VERSION ""

NS_ :

BS_:

BU_: WPC2 RLPSU DPSU APSU PSB SHVU_RR vHS_B2 FCS EMCU SLB ARS RCM CGW_CCU vDummy_HS_B ATS RLHV SGU PFSU ALBCU DSAU SWRC SHVU_FR RCS RRPSU BLTN_CAM SCM DLBCU OHCL RWPC RRHV WPC HOD ASAU

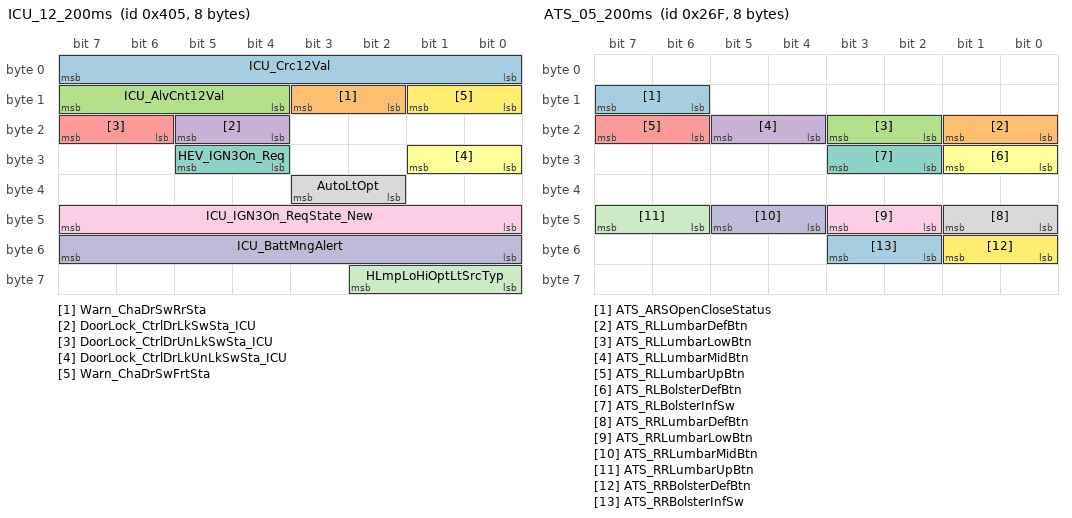
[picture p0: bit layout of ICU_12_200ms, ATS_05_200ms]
BO_ 1029 ICU_12_200ms: 8 CGW_CCU
 SG_ ICU_Crc12Val : 0|8@1+ (1,0) [0|0] ""  Vector__XXX
 SG_ Warn_ChaDrSwRrSta : 10|2@1+ (1,0) [0|0] ""  Vector__XXX
 SG_ ICU_AlvCnt12Val : 12|4@1+ (1,0) [0|0] ""  Vector__XXX
 SG_ DoorLock_CtrlDrLkSwSta_ICU : 20|2@1+ (1,0) [0|0] ""  Vector__XXX
 SG_ DoorLock_CtrlDrUnLkSwSta_ICU : 22|2@1+ (1,0) [0|0] ""  Vector__XXX
 SG_ DoorLock_CtrlDrLkUnLkSwSta_ICU : 24|2@1+ (1,0) [0|0] ""  Vector__XXX
 SG_ HEV_IGN3On_Req : 28|2@1+ (1,0) [0|0] ""  Vector__XXX
 SG_ AutoLtOpt : 34|2@1+ (1,0) [0|0] ""  Vector__XXX
 SG_ ICU_IGN3On_ReqState_New : 40|8@1+ (1,0) [0|0] ""  APSU,RLHV,RRHV,SHVU_FR,SHVU_RR,DPSU,DLBCU,PFSU,RRPSU,RLPSU
 SG_ ICU_BattMngAlert : 48|8@1+ (1,0) [0|0] ""  Vector__XXX
 SG_ HLmpLoHiOptLtSrcTyp : 56|3@1+ (1,0) [0|0] ""  Vector__XXX
 SG_ Warn_ChaDrSwFrtSta : 8|2@1+ (1,0) [0|0] ""  Vector__XXX

BO_ 623 ATS_05_200ms: 8 ATS
 SG_ ATS_ARSOpenCloseStatus : 14|2@1+ (1,0) [0|0] ""  Vector__XXX
 SG_ ATS_RLLumbarDefBtn : 16|2@1+ (1,0) [0|0] ""  Vector__XXX
 SG_ ATS_RLLumbarLowBtn : 18|2@1+ (1,0) [0|0] ""  Vector__XXX
 SG_ ATS_RLLumbarMidBtn : 20|2@1+ (1,0) [0|0] ""  Vector__XXX
 SG_ ATS_RLLumbarUpBtn : 22|2@1+ (1,0) [0|0] ""  Vector__XXX
 SG_ ATS_RLBolsterDefBtn : 24|2@1+ (1,0) [0|0] ""  Vector__XXX
 SG_ ATS_RLBolsterInfSw : 26|2@1+ (1,0) [0|0] ""  Vector__XXX
 SG_ ATS_RRLumbarDefBtn : 40|2@1+ (1,0) [0|0] ""  Vector__XXX
 SG_ ATS_RRLumbarLowBtn : 42|2@1+ (1,0) [0|0] ""  Vector__XXX
 SG_ ATS_RRLumbarMidBtn : 44|2@1+ (1,0) [0|0] ""  Vector__XXX
 SG_ ATS_RRLumbarUpBtn : 46|2@1+ (1,0) [0|0] ""  Vector__XXX
 SG_ ATS_RRBolsterDefBtn : 48|2@1+ (1,0) [0|0] ""  Vector__XXX
 SG_ ATS_RRBolsterInfSw : 50|2@1+ (1,0) [0|0] ""  Vector__XXX

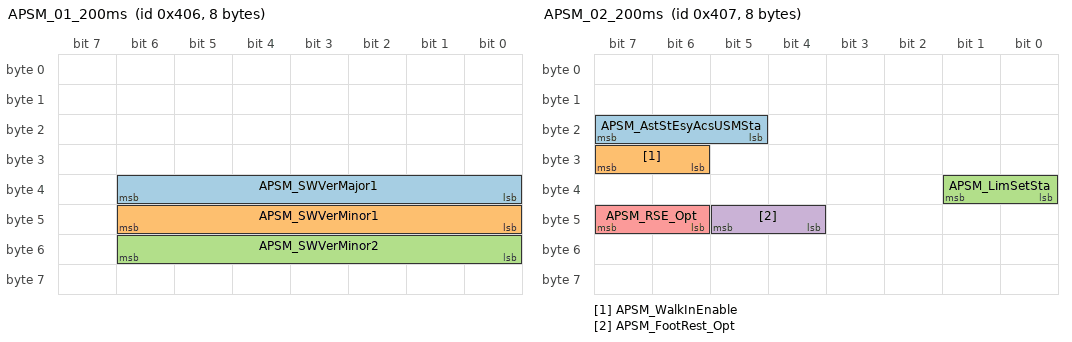
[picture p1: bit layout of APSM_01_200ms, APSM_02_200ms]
BO_ 1030 APSM_01_200ms: 8 APSU
 SG_ APSM_SWVerMajor1 : 32|7@1+ (1,0) [0|0] ""  CGW_CCU
 SG_ APSM_SWVerMinor1 : 40|7@1+ (1,0) [0|0] ""  CGW_CCU
 SG_ APSM_SWVerMinor2 : 48|7@1+ (1,0) [0|0] ""  CGW_CCU

BO_ 1031 APSM_02_200ms: 8 APSU
 SG_ APSM_AstStEsyAcsUSMSta : 21|3@1+ (1,0) [0|0] ""  CGW_CCU
 SG_ APSM_WalkInEnable : 30|2@1+ (1,0) [0|0] ""  Vector__XXX
 SG_ APSM_LimSetSta : 32|2@1+ (1,0) [0|0] ""  Vector__XXX
 SG_ APSM_FootRest_Opt : 44|2@1+ (1,0) [0|0] ""  Vector__XXX
 SG_ APSM_RSE_Opt : 46|2@1+ (1,0) [0|0] ""  Vector__XXX

BO_ 1048 ICU_08_200ms: 8 CGW_CCU
 SG_ ICU_Crc8Val : 0|8@1+ (1,0) [0|0] ""  Vector__XXX
 SG_ ICU_AlvCnt8Val : 12|4@1+ (1,0) [0|0] ""  Vector__XXX
 SG_ DriveTypeOption : 16|2@1+ (1,0) [0|0] ""  APSU,SHVU_FR,SHVU_RR,DPSU,DLBCU,ATS,BLTN_CAM
 SG_ Warn_RrLftSBRMATSwSta : 18|2@1+ (1,0) [0|0] ""  Vector__XXX
 SG_ Warn_RrRhtSBRMATSwSta : 20|2@1+ (1,0) [0|0] ""  Vector__XXX
 SG_ Lamp_FootLampOnReq : 30|2@1+ (1,0) [0|0] ""  Vector__XXX
 SG_ Lamp_MoodLampOnReq : 32|3@1+ (1,0) [0|0] ""  Vector__XXX
 SG_ ICU_PowerAutoCutModSta : 35|2@1+ (1,0) [0|0] ""  APSU,RLHV,RRHV,DPSU,RRPSU,RLPSU,BLTN_CAM
 SG_ ICU_SoCBattStaMsgReq : 37|2@1+ (1,0) [0|0] ""  Vector__XXX
 SG_ C_1stCTRSeatBeltSW : 39|1@1+ (1,0) [0|0] ""  Vector__XXX
 SG_ Brake_SwSta_ICU : 46|2@1+ (1,0) [0|0] ""  Vector__XXX
 SG_ C_1stCTRSBRMatSw : 48|1@1+ (1,0) [0|0] ""  Vector__XXX
 SG_ C_3rdRCSeatBeltSW : 51|1@1+ (1,0) [0|0] ""  ARS,RRPSU,RLPSU,WPC2
 SG_ C_3rdRRSBRMatSw : 52|1@1+ (1,0) [0|0] ""  ARS,RRPSU,RLPSU,WPC2
 SG_ C_3rdRLSBRMatSw : 53|1@1+ (1,0) [0|0] ""  ARS,RLPSU,WPC2
 SG_ C_3rdRRSeatBeltSW : 54|1@1+ (1,0) [0|0] ""  ARS,RRPSU,RLPSU,WPC2
 SG_ C_3rdRLSeatBeltSW : 55|1@1+ (1,0) [0|0] ""  ARS,RRPSU,RLPSU,WPC2
 SG_ HSWS_SysWrngSta_ICU : 8|2@1+ (1,0) [0|0] ""  Vector__XXX

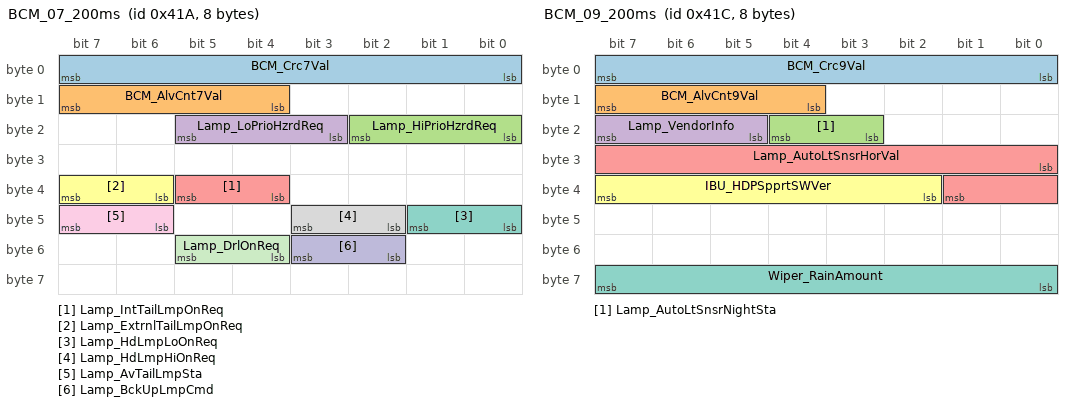
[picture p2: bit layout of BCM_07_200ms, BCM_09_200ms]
BO_ 1050 BCM_07_200ms: 8 CGW_CCU
 SG_ BCM_Crc7Val : 0|8@1+ (1,0) [0|0] ""  Vector__XXX
 SG_ BCM_AlvCnt7Val : 12|4@1+ (1,0) [0|0] ""  Vector__XXX
 SG_ Lamp_HiPrioHzrdReq : 16|3@1+ (1,0) [0|0] ""  Vector__XXX
 SG_ Lamp_LoPrioHzrdReq : 19|3@1+ (1,0) [0|0] ""  Vector__XXX
 SG_ Lamp_IntTailLmpOnReq : 36|2@1+ (1,0) [0|0] ""  FCS,WPC,RWPC,APSU,RLHV,RRHV,SHVU_FR,SHVU_RR,DPSU,WPC2
 SG_ Lamp_ExtrnlTailLmpOnReq : 38|2@1+ (1,0) [0|0] ""  BLTN_CAM
 SG_ Lamp_HdLmpLoOnReq : 40|2@1+ (1,0) [0|0] ""  Vector__XXX
 SG_ Lamp_HdLmpHiOnReq : 42|2@1+ (1,0) [0|0] ""  Vector__XXX
 SG_ Lamp_AvTailLmpSta : 46|2@1+ (1,0) [0|0] ""  SWRC,APSU,ATS
 SG_ Lamp_BckUpLmpCmd : 50|2@1+ (1,0) [0|0] ""  Vector__XXX
 SG_ Lamp_DrlOnReq : 52|2@1+ (1,0) [0|0] ""  Vector__XXX

BO_ 1052 BCM_09_200ms: 8 CGW_CCU
 SG_ BCM_Crc9Val : 0|8@1+ (1,0) [0|0] ""  Vector__XXX
 SG_ BCM_AlvCnt9Val : 12|4@1+ (1,0) [0|0] ""  Vector__XXX
 SG_ Lamp_AutoLtSnsrNightSta : 19|2@1+ (1,0) [0|0] ""  SWRC,APSU,ATS
 SG_ Lamp_VendorInfo : 21|3@1+ (1,0) [0|0] ""  Vector__XXX
 SG_ Lamp_AutoLtSnsrHorVal : 24|10@1+ (1,0) [0|0] ""  ATS
 SG_ IBU_HDPSpprtSWVer : 34|6@1+ (1,0) [0|0] ""  Vector__XXX
 SG_ Wiper_RainAmount : 56|8@1+ (0.5,0) [0|0] ""  Vector__XXX

BO_ 1041 ICU_02_200ms: 8 CGW_CCU
 SG_ ICU_Crc2Val : 0|8@1+ (1,0) [0|0] ""  Vector__XXX
 SG_ ICU_MtGearPosRSta : 10|2@1+ (1,0) [0|0] ""  BLTN_CAM
 SG_ ICU_AlvCnt2Val : 12|4@1+ (1,0) [0|0] ""  Vector__XXX
 SG_ Autocut_DlvryModSta : 20|2@1+ (1,0) [0|0] ""  Vector__XXX
 SG_ DoorLock_AsstDrUnLkSta : 22|2@1+ (1,0) [0|0] ""  Vector__XXX
 SG_ Warn_DrvDrSwSta : 24|2@1+ (1,0) [0|0] ""  WPC,RWPC,DPSU,BLTN_CAM,WPC2
 SG_ DoorLock_DrvKeyUnLkSwSta : 26|2@1+ (1,0) [0|0] ""  Vector__XXX
 SG_ DoorLock_RrLftDrUnLkSta : 28|2@1+ (1,0) [0|0] ""  Vector__XXX
 SG_ DoorLock_RrRtDrUnLkSta : 30|2@1+ (1,0) [0|0] ""  Vector__XXX
 SG_ Warn_AsstDrSwSta : 34|2@1+ (1,0) [0|0] ""  WPC,RWPC,APSU,RLPSU,BLTN_CAM,ALBCU,WPC2
 SG_ Warn_AsstStBltSwSta : 36|2@1+ (1,0) [0|0] ""  PSB,APSU,RLPSU,ASAU,ALBCU
 SG_ Warn_BrkFldSwSta : 38|2@1+ (1,0) [0|0] ""  Vector__XXX
 SG_ DoorLock_DrvKeyLkSwSta : 40|2@1+ (1,0) [0|0] ""  Vector__XXX
 SG_ Warn_DrvStBltSwSta : 42|2@1+ (1,0) [0|0] ""  PSB,DPSU,DLBCU,ATS,DSAU,ASAU
 SG_ Warn_HoodSwSta : 44|2@1+ (1,0) [0|0] ""  BLTN_CAM
 SG_ Warn_PassStOccSta : 46|2@1+ (1,0) [0|0] ""  APSU
 SG_ Warn_PrkngBrkSwSta : 48|2@1+ (1,0) [0|0] ""  APSU,RLHV,RRHV,PFSU,RRPSU,RLPSU
 SG_ Warn_RrCtrStBltSwSta : 50|2@1+ (1,0) [0|0] ""  PSB
 SG_ Warn_RrLftDrSwSta : 52|2@1+ (1,0) [0|0] ""  WPC,RWPC,APSU,RLHV,RLPSU,BLTN_CAM,WPC2
 SG_ Warn_RrLftStBltSwSta : 54|2@1+ (1,0) [0|0] ""  PSB,APSU,DPSU
 SG_ Warn_RrRtDrSwSta : 56|2@1+ (1,0) [0|0] ""  WPC,RWPC,APSU,RRHV,RRPSU,RLPSU,BLTN_CAM,WPC2
 SG_ Warn_RrRtStBltSwSta : 58|2@1+ (1,0) [0|0] ""  PSB,APSU,DPSU,RRPSU
 SG_ Warn_HoodSwMemorySta : 60|2@1+ (1,0) [0|0] ""  Vector__XXX
 SG_ Warn_WshrFldSwSta : 62|2@1+ (1,0) [0|0] ""  Vector__XXX
 SG_ ICU_Haptic_OPT : 8|2@1+ (1,0) [0|0] ""  Vector__XXX

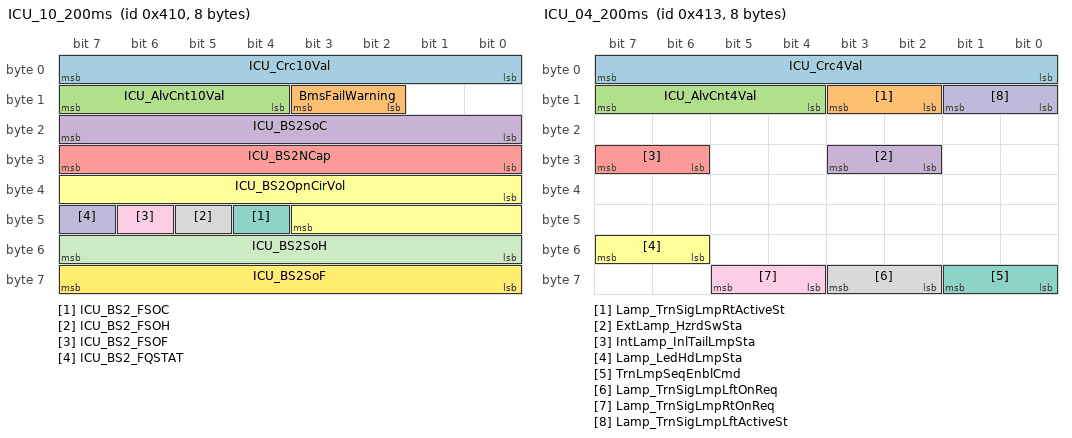
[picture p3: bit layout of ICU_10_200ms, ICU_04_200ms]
BO_ 1040 ICU_10_200ms: 8 CGW_CCU
 SG_ ICU_Crc10Val : 0|8@1+ (1,0) [0|0] ""  Vector__XXX
 SG_ BmsFailWarning : 10|2@1+ (1,0) [0|0] ""  Vector__XXX
 SG_ ICU_AlvCnt10Val : 12|4@1+ (1,0) [0|0] ""  Vector__XXX
 SG_ ICU_BS2SoC : 16|8@1+ (1,0) [0|0] ""  BLTN_CAM
 SG_ ICU_BS2NCap : 24|8@1+ (1,0) [0|0] ""  Vector__XXX
 SG_ ICU_BS2OpnCirVol : 32|12@1+ (0.001,10) [0|0] ""  Vector__XXX
 SG_ ICU_BS2_FSOC : 44|1@1+ (1,0) [0|0] ""  Vector__XXX
 SG_ ICU_BS2_FSOH : 45|1@1+ (1,0) [0|0] ""  Vector__XXX
 SG_ ICU_BS2_FSOF : 46|1@1+ (1,0) [0|0] ""  Vector__XXX
 SG_ ICU_BS2_FQSTAT : 47|1@1+ (1,0) [0|0] ""  Vector__XXX
 SG_ ICU_BS2SoH : 48|8@1+ (1,0) [0|0] ""  Vector__XXX
 SG_ ICU_BS2SoF : 56|8@1+ (0.05,0) [0|0] ""  Vector__XXX

BO_ 1043 ICU_04_200ms: 8 CGW_CCU
 SG_ ICU_Crc4Val : 0|8@1+ (1,0) [0|0] ""  Vector__XXX
 SG_ Lamp_TrnSigLmpRtActiveSt : 10|2@1+ (1,0) [0|0] ""  Vector__XXX
 SG_ ICU_AlvCnt4Val : 12|4@1+ (1,0) [0|0] ""  Vector__XXX
 SG_ ExtLamp_HzrdSwSta : 26|2@1+ (1,0) [0|0] ""  Vector__XXX
 SG_ IntLamp_InlTailLmpSta : 30|2@1+ (1,0) [0|0] ""  SWRC,BLTN_CAM,WPC2
 SG_ Lamp_LedHdLmpSta : 54|2@1+ (1,0) [0|0] ""  Vector__XXX
 SG_ TrnLmpSeqEnblCmd : 56|2@1+ (1,0) [0|0] ""  Vector__XXX
 SG_ Lamp_TrnSigLmpLftOnReq : 58|2@1+ (1,0) [0|0] ""  BLTN_CAM
 SG_ Lamp_TrnSigLmpRtOnReq : 60|2@1+ (1,0) [0|0] ""  BLTN_CAM
 SG_ Lamp_TrnSigLmpLftActiveSt : 8|2@1+ (1,0) [0|0] ""  Vector__XXX

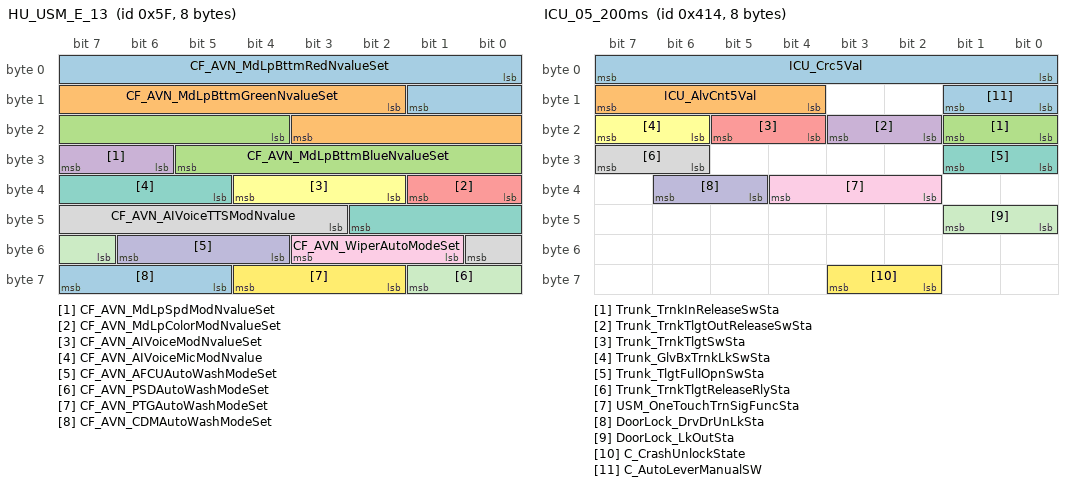
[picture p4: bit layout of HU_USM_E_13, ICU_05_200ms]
BO_ 95 HU_USM_E_13: 8 CGW_CCU
 SG_ CF_AVN_MdLpBttmRedNvalueSet : 0|10@1+ (1,0) [0|0] ""  Vector__XXX
 SG_ CF_AVN_MdLpBttmGreenNvalueSet : 10|10@1+ (1,0) [0|0] ""  Vector__XXX
 SG_ CF_AVN_MdLpBttmBlueNvalueSet : 20|10@1+ (1,10) [0|0] ""  Vector__XXX
 SG_ CF_AVN_MdLpSpdModNvalueSet : 30|2@1+ (1,0) [0|0] ""  Vector__XXX
 SG_ CF_AVN_MdLpColorModNvalueSet : 32|2@1+ (1,0) [0|0] ""  Vector__XXX
 SG_ CF_AVN_AIVoiceModNvalueSet : 34|3@1+ (1,0) [0|0] ""  SWRC
 SG_ CF_AVN_AIVoiceMicModNvalue : 37|6@1+ (1,0) [0|0] ""  SWRC
 SG_ CF_AVN_AIVoiceTTSModNvalue : 43|6@1+ (1,0) [0|0] ""  SWRC
 SG_ CF_AVN_WiperAutoModeSet : 49|3@1+ (1,0) [0|0] ""  Vector__XXX
 SG_ CF_AVN_AFCUAutoWashModeSet : 52|3@1+ (1,0) [0|0] ""  Vector__XXX
 SG_ CF_AVN_PSDAutoWashModeSet : 55|3@1+ (1,0) [0|0] ""  Vector__XXX
 SG_ CF_AVN_PTGAutoWashModeSet : 58|3@1+ (1,0) [0|0] ""  Vector__XXX
 SG_ CF_AVN_CDMAutoWashModeSet : 61|3@1+ (1,0) [0|0] ""  Vector__XXX

BO_ 639 ATS_04_00ms: 8 ATS
 SG_ ATS_RRSeatHeaterSW : 0|2@1+ (1,0) [0|0] ""  RRHV,SHVU_RR
 SG_ ATS_RLSeatHeaterUpSW : 10|2@1+ (1,0) [0|0] ""  RLHV,SHVU_RR
 SG_ ATS_RRSeatVentDownSW : 12|2@1+ (1,0) [0|0] ""  RRHV,SHVU_RR
 SG_ ATS_RLSeatVentDownSW : 14|2@1+ (1,0) [0|0] ""  RLHV,SHVU_RR
 SG_ ATS_RLMemoryRestBtn : 16|2@1+ (1,0) [0|0] ""  Vector__XXX
 SG_ ATS_RLMemoryReturnBtn : 18|2@1+ (1,0) [0|0] ""  Vector__XXX
 SG_ ATS_RLSeatHeaterSW : 2|2@1+ (1,0) [0|0] ""  RLHV,SHVU_RR
 SG_ ATS_RRMemoryRestBtn : 20|2@1+ (1,0) [0|0] ""  Vector__XXX
 SG_ ATS_RRMemoryReturnBtn : 22|2@1+ (1,0) [0|0] ""  Vector__XXX
 SG_ ATS_RRMemoryAvWtcBtn : 24|2@1+ (1,0) [0|0] ""  Vector__XXX
 SG_ ATS_RRMemoryReadingBtn : 26|2@1+ (1,0) [0|0] ""  Vector__XXX
 SG_ ATS_RRRestModBtnSTD : 32|2@1+ (1,0) [0|0] ""  Vector__XXX
 SG_ ATS_RRResetModBtnSTD : 34|2@1+ (1,0) [0|0] ""  Vector__XXX
 SG_ ATS_RRAvWtcModBtnSTD : 36|2@1+ (1,0) [0|0] ""  Vector__XXX
 SG_ ATS_RRReadingModBtnSTD : 38|2@1+ (1,0) [0|0] ""  Vector__XXX
 SG_ ATS_RRSeatVentSW : 4|2@1+ (1,0) [0|0] ""  RRHV,SHVU_RR
 SG_ ATS_RLRestModBtnSTD : 40|2@1+ (1,0) [0|0] ""  Vector__XXX
 SG_ ATS_RLResetModBtnSTD : 42|2@1+ (1,0) [0|0] ""  Vector__XXX
 SG_ ATS_RRModestateStopBtn : 44|2@1+ (1,0) [0|0] ""  Vector__XXX
 SG_ ATS_RLModestateStopBtn : 46|2@1+ (1,0) [0|0] ""  Vector__XXX
 SG_ ATS_RLResetRestBtn : 48|2@1+ (1,0) [0|0] ""  Vector__XXX
 SG_ ATS_RLResetReturnBtn : 50|2@1+ (1,0) [0|0] ""  Vector__XXX
 SG_ ATS_RRResetRestBtn : 52|2@1+ (1,0) [0|0] ""  Vector__XXX
 SG_ ATS_RRResetReturnBtn : 54|2@1+ (1,0) [0|0] ""  Vector__XXX
 SG_ ATS_RRResetAvWtcBtn : 56|2@1+ (1,0) [0|0] ""  Vector__XXX
 SG_ ATS_RRResetReadingBtn : 58|2@1+ (1,0) [0|0] ""  Vector__XXX
 SG_ ATS_RLSeatVentSW : 6|2@1+ (1,0) [0|0] ""  RLHV,SHVU_RR
 SG_ ATS_RRSeatHeaterUpSW : 8|2@1+ (1,0) [0|0] ""  RRHV,SHVU_RR

BO_ 1044 ICU_05_200ms: 8 CGW_CCU
 SG_ ICU_Crc5Val : 0|8@1+ (1,0) [0|0] ""  Vector__XXX
 SG_ ICU_AlvCnt5Val : 12|4@1+ (1,0) [0|0] ""  Vector__XXX
 SG_ Trunk_TrnkInReleaseSwSta : 16|2@1+ (1,0) [0|0] ""  Vector__XXX
 SG_ Trunk_TrnkTlgtOutReleaseSwSta : 18|2@1+ (1,0) [0|0] ""  Vector__XXX
 SG_ Trunk_TrnkTlgtSwSta : 20|2@1+ (1,0) [0|0] ""  APSU,RLHV,RRHV,PFSU,RRPSU,RLPSU,BLTN_CAM
 SG_ Trunk_GlvBxTrnkLkSwSta : 22|2@1+ (1,0) [0|0] ""  Vector__XXX
 SG_ Trunk_TlgtFullOpnSwSta : 24|2@1+ (1,0) [0|0] ""  Vector__XXX
 SG_ Trunk_TrnkTlgtReleaseRlySta : 30|2@1+ (1,0) [0|0] ""  Vector__XXX
 SG_ USM_OneTouchTrnSigFuncSta : 34|3@1+ (1,0) [0|0] ""  Vector__XXX
 SG_ DoorLock_DrvDrUnLkSta : 37|2@1+ (1,0) [0|0] ""  Vector__XXX
 SG_ DoorLock_LkOutSta : 40|2@1+ (1,0) [0|0] ""  Vector__XXX
 SG_ C_CrashUnlockState : 58|2@1+ (1,0) [0|0] ""  BLTN_CAM
 SG_ C_AutoLeverManualSW : 8|2@1+ (1,0) [0|0] ""  Vector__XXX

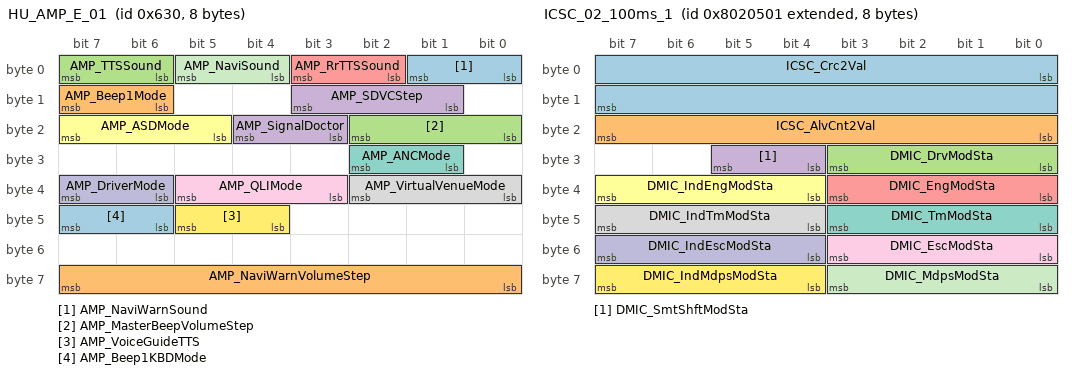
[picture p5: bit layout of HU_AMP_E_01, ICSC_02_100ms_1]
BO_ 1584 HU_AMP_E_01: 8 CGW_CCU
 SG_ AMP_NaviWarnSound : 0|2@1+ (1,0) [0|0] ""  Vector__XXX
 SG_ AMP_Beep1Mode : 14|2@1+ (1,0) [0|0] ""  ATS
 SG_ AMP_MasterBeepVolumeStep : 16|3@1+ (1,0) [0|0] ""  Vector__XXX
 SG_ AMP_SignalDoctor : 19|2@1+ (1,0) [0|0] ""  Vector__XXX
 SG_ AMP_RrTTSSound : 2|2@1+ (1,0) [0|0] ""  Vector__XXX
 SG_ AMP_ASDMode : 21|3@1+ (1,0) [0|0] ""  Vector__XXX
 SG_ AMP_ANCMode : 25|2@1+ (1,0) [0|0] ""  Vector__XXX
 SG_ AMP_VirtualVenueMode : 32|3@1+ (1,0) [0|0] ""  Vector__XXX
 SG_ AMP_QLIMode : 35|3@1+ (1,0) [0|0] ""  Vector__XXX
 SG_ AMP_DriverMode : 38|2@1+ (1,0) [0|0] ""  Vector__XXX
 SG_ AMP_NaviSound : 4|2@1+ (1,0) [0|0] ""  Vector__XXX
 SG_ AMP_VoiceGuideTTS : 44|2@1+ (1,0) [0|0] ""  Vector__XXX
 SG_ AMP_Beep1KBDMode : 46|2@1+ (1,0) [0|0] ""  Vector__XXX
 SG_ AMP_NaviWarnVolumeStep : 56|8@1+ (1,0) [0|0] ""  Vector__XXX
 SG_ AMP_TTSSound : 6|2@1+ (1,0) [0|0] ""  Vector__XXX
 SG_ AMP_SDVCStep : 9|3@1+ (1,0) [0|0] ""  Vector__XXX

BO_ 2281833729 ICSC_02_100ms_1: 8 CGW_CCU
 SG_ ICSC_Crc2Val : 0|16@1+ (1,0) [0|0] ""  Vector__XXX
 SG_ ICSC_AlvCnt2Val : 16|8@1+ (1,0) [0|0] ""  Vector__XXX
 SG_ DMIC_DrvModSta : 24|4@1+ (1,0) [0|0] ""  APSU,DLBCU,DSAU,ASAU,ALBCU
 SG_ DMIC_SmtShftModSta : 28|2@1+ (1,0) [0|0] ""  Vector__XXX
 SG_ DMIC_EngModSta : 32|4@1+ (1,0) [0|0] ""  Vector__XXX
 SG_ DMIC_IndEngModSta : 36|4@1+ (1,0) [0|0] ""  Vector__XXX
 SG_ DMIC_TmModSta : 40|4@1+ (1,0) [0|0] ""  Vector__XXX
 SG_ DMIC_IndTmModSta : 44|4@1+ (1,0) [0|0] ""  Vector__XXX
 SG_ DMIC_EscModSta : 48|4@1+ (1,0) [0|0] ""  Vector__XXX
 SG_ DMIC_IndEscModSta : 52|4@1+ (1,0) [0|0] ""  Vector__XXX
 SG_ DMIC_MdpsModSta : 56|4@1+ (1,0) [0|0] ""  Vector__XXX
 SG_ DMIC_IndMdpsModSta : 60|4@1+ (1,0) [0|0] ""  Vector__XXX

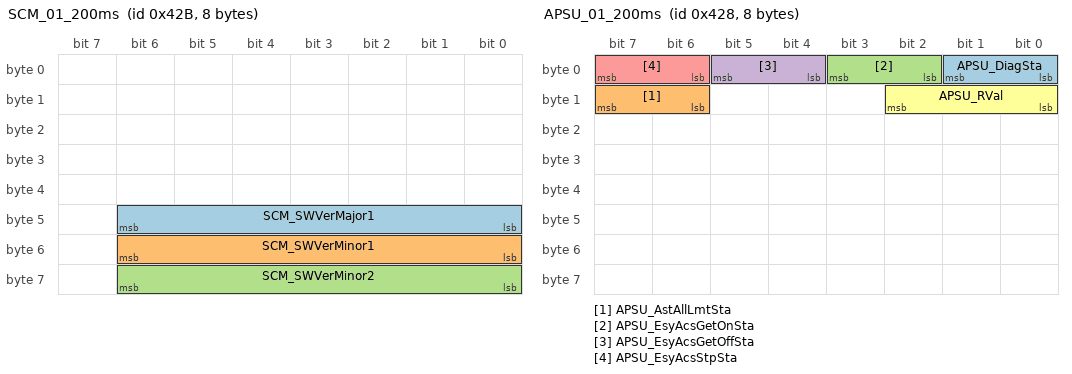
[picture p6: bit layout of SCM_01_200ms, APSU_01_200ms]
BO_ 1067 SCM_01_200ms: 8 SCM
 SG_ SCM_SWVerMajor1 : 40|7@1+ (1,0) [0|0] ""  CGW_CCU
 SG_ SCM_SWVerMinor1 : 48|7@1+ (1,0) [0|0] ""  CGW_CCU
 SG_ SCM_SWVerMinor2 : 56|7@1+ (1,0) [0|0] ""  CGW_CCU

BO_ 577 HU_APSU_PE_02: 8 CGW_CCU
 SG_ C_AstBolsterInfSw_HU : 0|2@1+ (1,0) [0|0] ""  ASAU,ALBCU
 SG_ C_RLHrestUpSw_HU : 14|2@1+ (1,0) [0|0] ""  APSU,RRPSU,RLPSU
 SG_ C_RLHrestDnSw_HU : 16|2@1+ (1,0) [0|0] ""  APSU,RRPSU,RLPSU
 SG_ C_RLHrestFwdSw_HU : 18|2@1+ (1,0) [0|0] ""  APSU,RRPSU,RLPSU
 SG_ C_AstBolsterDefSw_HU : 2|2@1+ (1,0) [0|0] ""  ASAU,ALBCU
 SG_ C_RLHrestBwdSw_HU : 20|2@1+ (1,0) [0|0] ""  APSU,RRPSU,RLPSU
 SG_ C_RLLumbarUpSw_HU : 22|2@1+ (1,0) [0|0] ""  RLPSU
 SG_ C_RLLumbarMidSw_HU : 24|2@1+ (1,0) [0|0] ""  RLPSU
 SG_ C_RLLumbarLowSw_HU : 26|2@1+ (1,0) [0|0] ""  RLPSU
 SG_ C_RLLumbarDefSw_HU : 28|2@1+ (1,0) [0|0] ""  RLPSU
 SG_ C_RLBolsterInfSw_HU : 30|2@1+ (1,0) [0|0] ""  RLPSU
 SG_ C_RLBolsterDefSw_HU : 32|2@1+ (1,0) [0|0] ""  RLPSU
 SG_ C_AstHrestUpSw_HU : 36|2@1+ (1,0) [0|0] ""  APSU
 SG_ C_AstHrestDnSw_HU : 38|2@1+ (1,0) [0|0] ""  APSU
 SG_ C_AstFootrestFldSw_HU : 4|2@1+ (1,0) [0|0] ""  APSU
 SG_ C_AstHrestFwdSw_HU : 46|2@1+ (1,0) [0|0] ""  APSU
 SG_ C_AstHrestBwdSw_HU : 54|2@1+ (1,0) [0|0] ""  APSU
 SG_ C_AstFootrestUnFldSw_HU : 6|2@1+ (1,0) [0|0] ""  APSU

BO_ 2281833731 ICSC_02_100ms_3: 8 CGW_CCU
 SG_ DMIC_VcuModSta : 0|4@1+ (1,0) [0|0] ""  Vector__XXX
 SG_ DMIC_DrvModTyp : 12|4@1+ (1,0) [0|0] ""  Vector__XXX
 SG_ DMIC_EngFltSta : 16|2@1+ (1,0) [0|0] ""  Vector__XXX
 SG_ DMIC_TmFltSta : 18|2@1+ (1,0) [0|0] ""  Vector__XXX
 SG_ DMIC_EscFltSta : 20|2@1+ (1,0) [0|0] ""  Vector__XXX
 SG_ DMIC_MdpsFltSta : 22|2@1+ (1,0) [0|0] ""  Vector__XXX
 SG_ DMIC_EcsFltSta : 24|2@1+ (1,0) [0|0] ""  Vector__XXX
 SG_ DMIC_AwdFltSta : 26|2@1+ (1,0) [0|0] ""  Vector__XXX
 SG_ DMIC_RevFltSta : 28|2@1+ (1,0) [0|0] ""  Vector__XXX
 SG_ DMIC_PrflFltSta : 30|2@1+ (1,0) [0|0] ""  Vector__XXX
 SG_ DMIC_ElsdFltSta : 32|2@1+ (1,0) [0|0] ""  Vector__XXX
 SG_ DMIC_EsndFltSta : 34|2@1+ (1,0) [0|0] ""  Vector__XXX
 SG_ DMIC_RwsFltSta : 36|2@1+ (1,0) [0|0] ""  Vector__XXX
 SG_ DMIC_IndWhlDrvSta : 38|2@1+ (1,0) [0|0] ""  Vector__XXX
 SG_ DMIC_IndVcuModSta : 4|4@1+ (1,0) [0|0] ""  Vector__XXX
 SG_ DMIC_VcuFltSta : 40|2@1+ (1,0) [0|0] ""  Vector__XXX
 SG_ DMIC_IndMtrPwrSta : 42|3@1+ (1,0) [0|0] ""  Vector__XXX
 SG_ DMIC_IndAccSenSta : 45|3@1+ (1,0) [0|0] ""  Vector__XXX
 SG_ DMIC_IndDecSenSta : 48|3@1+ (1,0) [0|0] ""  Vector__XXX
 SG_ DMIC_IndMaxVehSpdSta : 51|6@1+ (1,0) [0|0] ""  Vector__XXX
 SG_ DMIC_DrvMod2Typ : 60|4@1+ (1,0) [0|0] ""  Vector__XXX
 SG_ DMIC_DrvModFltSta : 8|4@1+ (1,0) [0|0] ""  Vector__XXX

BO_ 578 HU_APSU_PE_03: 8 CGW_CCU
 SG_ C_RRLegSupFwdSw_HU : 0|2@1+ (1,0) [0|0] ""  APSU,RRPSU,RLPSU
 SG_ C_RRHrestDnSw_HU : 10|2@1+ (1,0) [0|0] ""  APSU,RRPSU,RLPSU
 SG_ C_RRHrestFwdSw_HU : 12|2@1+ (1,0) [0|0] ""  APSU,RRPSU,RLPSU
 SG_ C_RRHrestBwdSw_HU : 14|2@1+ (1,0) [0|0] ""  APSU,RRPSU,RLPSU
 SG_ C_RRLumbarUpSw_HU : 16|2@1+ (1,0) [0|0] ""  APSU,RRPSU
 SG_ C_RRLumbarMidSw_HU : 18|2@1+ (1,0) [0|0] ""  APSU,RRPSU
 SG_ C_RRLegSupBwdSw_HU : 2|2@1+ (1,0) [0|0] ""  APSU,RRPSU,RLPSU
 SG_ C_RRLumbarLowSw_HU : 20|2@1+ (1,0) [0|0] ""  APSU,RRPSU
 SG_ C_RRLumbarDefSw_HU : 22|2@1+ (1,0) [0|0] ""  APSU,RRPSU
 SG_ C_RRBolsterInfSw_HU : 24|2@1+ (1,0) [0|0] ""  APSU,RRPSU
 SG_ C_RRLegSupUpSw_HU : 4|2@1+ (1,0) [0|0] ""  APSU,RRPSU,RLPSU
 SG_ C_RROneTchNValueSet : 40|3@1+ (1,0) [0|0] ""  APSU,RRPSU,RLPSU,ATS
 SG_ C_RLOneTchNValueSet : 43|3@1+ (1,0) [0|0] ""  APSU,RRPSU,RLPSU,ATS
 SG_ C_RRBolsterDefSw_HU : 46|2@1+ (1,0) [0|0] ""  APSU,RRPSU
 SG_ C_AstRlxTiltUpSw_HU : 50|2@1+ (1,0) [0|0] ""  APSU
 SG_ C_AstRlxTiltDnSw_HU : 52|2@1+ (1,0) [0|0] ""  APSU
 SG_ C_RLRSEUpSw_HU : 54|2@1+ (1,0) [0|0] ""  APSU,RRPSU,RLPSU
 SG_ C_RLRSEDnSw_HU : 56|2@1+ (1,0) [0|0] ""  APSU,RRPSU,RLPSU
 SG_ C_RRRSEUpSw_HU : 58|2@1+ (1,0) [0|0] ""  APSU,RRPSU,RLPSU
 SG_ C_RRLegSupDnSw_HU : 6|2@1+ (1,0) [0|0] ""  APSU,RRPSU,RLPSU
 SG_ C_RRRSEDnSw_HU : 60|2@1+ (1,0) [0|0] ""  APSU,RRPSU,RLPSU
 SG_ C_RRHrestUpSw_HU : 8|2@1+ (1,0) [0|0] ""  APSU,RRPSU,RLPSU

BO_ 1064 APSU_01_200ms: 8 APSU
 SG_ APSU_DiagSta : 0|2@1+ (1,0) [0|0] ""  Vector__XXX
 SG_ APSU_AstAllLmtSta : 14|2@1+ (1,0) [0|0] ""  RLPSU,RRPSU
 SG_ APSU_EsyAcsGetOnSta : 2|2@1+ (1,0) [0|0] ""  ALBCU
 SG_ APSU_EsyAcsGetOffSta : 4|2@1+ (1,0) [0|0] ""  ALBCU
 SG_ APSU_EsyAcsStpSta : 6|2@1+ (1,0) [0|0] ""  ALBCU
 SG_ APSU_RVal : 8|3@1+ (1,0) [0|0] ""  Vector__XXX

CM_ BO_ 1030 "[PE] Periodic and On Event";
CM_ SG_ 1030 APSM_SWVerMajor1 "First Word(ASCII) in APSM S/W Ver";
CM_ SG_ 1030 APSM_SWVerMinor1 "Second Word(ASCII) in APSM S/W Ver";
CM_ SG_ 1030 APSM_SWVerMinor2 "Third Word(ASCII) in APSM S/W Ver";
CM_ BO_ 1031 "[PE] Periodic and On Event";
CM_ SG_ 1031 APSM_AstStEsyAcsUSMSta "USM_MovingValue";
CM_ SG_ 1031 APSM_LimSetSta "APSM limit setting state";
CM_ SG_ 1031 APSM_FootRest_Opt "Foot Rest OPTION";
CM_ SG_ 1031 APSM_RSE_Opt "RSE OPTION";
CM_ BO_ 1064 "[PE] Periodic and On Event";
CM_ SG_ 1064 APSU_DiagSta "APSU_DiagnosticStatus";
CM_ SG_ 1064 APSU_EsyAcsGetOnSta "APSU_EasyAccessGetOnStatus";
CM_ SG_ 1064 APSU_EsyAcsGetOffSta "APSU_EasyAccessGetOffStatus";
CM_ SG_ 1064 APSU_EsyAcsStpSta "APSU_EasyAccessStopStatus";
CM_ SG_ 1064 APSU_RVal "APSU_RValue";
CM_ BO_ 639 "[EC] On Event and On Change";
CM_ SG_ 639 ATS_RRSeatHeaterSW "ATS touch command for seat heat control (For Rear Right seat)";
CM_ SG_ 639 ATS_RLSeatHeaterUpSW "ATS touch command for seat heat control  (For Rear Left seat)";
CM_ SG_ 639 ATS_RRSeatVentDownSW "ATS touch command for seat Vent control (For Rear Right seat)";
CM_ SG_ 639 ATS_RLSeatVentDownSW "ATS touch command for seat Vent control (For Rear Left seat)";
CM_ SG_ 639 ATS_RLMemoryRestBtn "Rear Left Rest Mode Custom Save Button (Except North America)";
CM_ SG_ 639 ATS_RLMemoryReturnBtn "Rear Left Return Mode Custom Save Button (Except North America)";
CM_ SG_ 639 ATS_RLSeatHeaterSW "ATS touch command for seat heat control  (For Rear Left seat)";
CM_ SG_ 639 ATS_RRMemoryRestBtn "Rear Right Rest Mode Custom Save Button (Except North America)";
CM_ SG_ 639 ATS_RRMemoryReturnBtn "Rear Right Return Mode Custom Save Button (Except North America)";
CM_ SG_ 639 ATS_RRMemoryAvWtcBtn "Rear Right AV Watching Mode Custom Save Button (Except North America)";
CM_ SG_ 639 ATS_RRMemoryReadingBtn "Rear Right Reading Mode Custom Save Button (Except North America)";
CM_ SG_ 639 ATS_RRRestModBtnSTD "Rear Right Rest Mode Touch Button (EXCEPT North America)";
CM_ SG_ 639 ATS_RRResetModBtnSTD "Rear Right Return Mode Touch Button (EXCEPT North America)";
CM_ SG_ 639 ATS_RRAvWtcModBtnSTD "Rear Right AV Watching Mode Touch Button (EXCEPT North America)";
CM_ SG_ 639 ATS_RRReadingModBtnSTD "Rear Right Reading Mode Touch Button (EXCEPT North America)";
CM_ SG_ 639 ATS_RRSeatVentSW "ATS touch command for seat Vent control (For Rear Right seat)";
CM_ SG_ 639 ATS_RLRestModBtnSTD "Rear Left Rest Mode Touch Button (EXCEPT North America)";
CM_ SG_ 639 ATS_RLResetModBtnSTD "Rear Left Return Mode Touch Button (EXCEPT North America)";
CM_ SG_ 639 ATS_RRModestateStopBtn "Rear Right One touch mode Stop Button";
CM_ SG_ 639 ATS_RLModestateStopBtn "Rear Left One touch mode Stop Button";
CM_ SG_ 639 ATS_RLResetRestBtn "Rear Left Rest Mode Custom Initialization Button (Except North America)";
CM_ SG_ 639 ATS_RLResetReturnBtn "Rear Left Return Mode Custom Initialization Button (Except North America)";
CM_ SG_ 639 ATS_RRResetRestBtn "Rear Right Rest Mode Custom Initialization Button (Except North America)";
CM_ SG_ 639 ATS_RRResetReturnBtn "Rear Right Return Mode Custom Initialization Button (Except North America)";
CM_ SG_ 639 ATS_RRResetAvWtcBtn "Rear Right AV Watching Mode Custom Initialization Button (Except North America)";
CM_ SG_ 639 ATS_RRResetReadingBtn "Rear Right Reading Mode Custom Initialization Button (Except North America)";
CM_ SG_ 639 ATS_RLSeatVentSW "ATS touch command for seat Vent control (For Rear Left seat)";
CM_ SG_ 639 ATS_RRSeatHeaterUpSW "ATS touch command for seat heat control  (For Rear Right seat)";
CM_ BO_ 623 "[PE] Periodic and On Event";
CM_ SG_ 623 ATS_ARSOpenCloseStatus "Armrest Open / Close Status";
CM_ SG_ 623 ATS_RLLumbarDefBtn "Rear Left Lumbar Deflation Touch Button";
CM_ SG_ 623 ATS_RLLumbarLowBtn "Rear Left Lumbar Low Touch Button";
CM_ SG_ 623 ATS_RLLumbarMidBtn "Rear Left Lumbar Middle Touch Button";
CM_ SG_ 623 ATS_RLLumbarUpBtn "Rear Left Lumbar Up Touch Button";
CM_ SG_ 623 ATS_RLBolsterDefBtn "Rear Left Bolster Deflation Touch Button";
CM_ SG_ 623 ATS_RLBolsterInfSw "Rear Left Bolster Inflation Touch Button";
CM_ SG_ 623 ATS_RRLumbarDefBtn "Rear Right Lumbar Deflation Touch Button";
CM_ SG_ 623 ATS_RRLumbarLowBtn "Rear Right Lumbar Low Touch Button";
CM_ SG_ 623 ATS_RRLumbarMidBtn "Rear Right Lumbar Middle Touch Button";
CM_ SG_ 623 ATS_RRLumbarUpBtn "Rear Right Lumbar Up Touch Button";
CM_ SG_ 623 ATS_RRBolsterDefBtn "Rear Right Bolster Deflation Touch Button";
CM_ SG_ 623 ATS_RRBolsterInfSw "Rear Right Bolster Inflation Touch Button";
CM_ BO_ 1050 "[PE] Periodic and On Event";
CM_ SG_ 1050 BCM_Crc7Val "BCM_CyclicRedundancyCheck7Value";
CM_ SG_ 1050 BCM_AlvCnt7Val "BCM_AliveCounter7Value";
CM_ SG_ 1050 Lamp_HiPrioHzrdReq "Lamp_HighPriorityHazardRequest ##2G##BCM - BCMmsg19 - C_HazardFromBCMHigh";
CM_ SG_ 1050 Lamp_LoPrioHzrdReq "Lamp_LowPriorityHazardStatus ##2G##BCM - BCMmsg19 - C_HazardfromBCMLow";
CM_ SG_ 1050 Lamp_IntTailLmpOnReq "Lamp_InternalTailLampOnRequest ##2G##BCM - BCMmsg19 - C_IntTailOn";
CM_ SG_ 1050 Lamp_ExtrnlTailLmpOnReq "Lamp_ExternalTailLampOnRequest ##2G##BCM - BCMmsg19 - C_ExtTailOn";
CM_ SG_ 1050 Lamp_HdLmpLoOnReq "Lamp_HeadLampLowOnRequest ##2G##BCM - BCMmsg19 - C_HLpLowOn";
CM_ SG_ 1050 Lamp_HdLmpHiOnReq "Lamp_HeadLampHighOnRequest ##2G##BCM - BCMmsg19 - C_HLpHighOn";
CM_ SG_ 1050 Lamp_AvTailLmpSta "Lamp_AvTailLampStatus ##2G##BCM - BCMmsg18 - C_AvTail";
CM_ BO_ 1052 "[PE] Periodic and On Event";
CM_ SG_ 1052 BCM_Crc9Val "BCM_CyclicRedundancyCheck9Value";
CM_ SG_ 1052 BCM_AlvCnt9Val "BCM_AliveCounter9Value";
CM_ SG_ 1052 Lamp_AutoLtSnsrNightSta "Lamp_AutoLightSensorNightStatus ##2G##BCM - BCMmsg24 - C_AutolightValue";
CM_ SG_ 1052 Lamp_AutoLtSnsrHorVal "Lamp_AutoLightSensorHorValue ##2G##BCM - BCMmsg24 - C_AutolightSensorHorState";
CM_ BO_ 1584 "[EC] On Event and On Change";
CM_ SG_ 1584 AMP_NaviWarnSound "Navi Warning prompt on/off";
CM_ SG_ 1584 AMP_Beep1Mode "Play touch beep sound one time
Beep1 mode on/off
For Harman AMP
Default : Off
Goes On when play beep sound
-This Signal's Feedback is AMP_Beep1ModeState(0x180)@AMP";
CM_ SG_ 1584 AMP_SignalDoctor "Command for Turn SignalDoctor(= Clarifi, Vitual high quality sound function) ON/OFF
Harman AMP Only
Current name is Clarifi";
CM_ SG_ 1584 AMP_RrTTSSound "Rear TTS prompt on/offOnly ON during the Rear TTS Sound Playing Default : Off-This Signal's Feedback is AMP_RrTTSModeState(0x60c)@AMP";
CM_ SG_ 1584 AMP_ASDMode "ASD Set Mode Value";
CM_ SG_ 1584 AMP_ANCMode "Signal for setting ANC On/Off";
CM_ SG_ 1584 AMP_NaviSound "Navi prompt on/off
Only ON during the Navi Guide Sound Playing
Default : Off
-This Signal's Feedback is AMP_NaviModeState(0x180)@AMP";
CM_ SG_ 1584 AMP_Beep1KBDMode "Play touch beep sound at keyboard screen on AVN-This Signal's Feedback is AMP_Beep1KBDModeState@AMP";
CM_ SG_ 1584 AMP_NaviWarnVolumeStep "- Command for Navigation Warning Prompt Volume Setting";
CM_ SG_ 1584 AMP_TTSSound "TTS prompt on/offOnly ON during the TTS Sound Playing Default : Off-This Signal's Feedback is AMP_TTSModeState(0x60c)@AMP";
CM_ SG_ 1584 AMP_SDVCStep "SDVC(Speed Dependant Volume Control = VSC) 
Step4 : off, low, mid, high";
CM_ BO_ 577 "[PE] Periodic and On Event";
CM_ SG_ 577 C_AstBolsterInfSw_HU "Assistant seat moving switch: Bolster Inflate";
CM_ SG_ 577 C_RLHrestUpSw_HU "2nd Left side seat Moving control : Headrest Up";
CM_ SG_ 577 C_RLHrestDnSw_HU "2nd Left side seat Moving control : Headrest Down";
CM_ SG_ 577 C_RLHrestFwdSw_HU "2nd Left side seat Moving control : Headrest Forward";
CM_ SG_ 577 C_AstBolsterDefSw_HU "Assistant seat moving switch: Bolster Deflate";
CM_ SG_ 577 C_RLHrestBwdSw_HU "2nd Left side seat Moving control : Headrest Backward";
CM_ SG_ 577 C_RLLumbarUpSw_HU "2nd Left side seat Moving control : Lumbar Up";
CM_ SG_ 577 C_RLLumbarMidSw_HU "2nd Left side seat Moving control : Lumbar Mid";
CM_ SG_ 577 C_RLLumbarLowSw_HU "2nd Left side seat Moving control : Lumbar Low";
CM_ SG_ 577 C_RLLumbarDefSw_HU "2nd Left side seat Moving control : Lumbar Deflate";
CM_ SG_ 577 C_RLBolsterInfSw_HU "2nd Left side seat Moving control : Bolster Inflate";
CM_ SG_ 577 C_RLBolsterDefSw_HU "2nd Left side seat Moving control : Bolster Deflate";
CM_ SG_ 577 C_AstHrestUpSw_HU "Assistant seat moving switch : Headrest Up";
CM_ SG_ 577 C_AstHrestDnSw_HU "Assistant seat Moving control : Headrest Down";
CM_ SG_ 577 C_AstFootrestFldSw_HU "Assistant seat moving switch: Footrest Fold";
CM_ SG_ 577 C_AstHrestFwdSw_HU "Assistant seat Moving control : Headrest Forward";
CM_ SG_ 577 C_AstHrestBwdSw_HU "Assistant seat moving switch : Headrest Backward";
CM_ SG_ 577 C_AstFootrestUnFldSw_HU "Assistant seat moving switch: Footrest Unfold";
CM_ BO_ 578 "[PE] Periodic and On Event";
CM_ SG_ 578 C_RRLegSupFwdSw_HU "2nd Right side seat Moving control : Leg Support Forward";
CM_ SG_ 578 C_RRHrestDnSw_HU "2nd Right side seat Moving control : Headrest Down";
CM_ SG_ 578 C_RRHrestFwdSw_HU "2nd Right side seat Moving control : Headrest Forward";
CM_ SG_ 578 C_RRHrestBwdSw_HU "2nd Right side seat Moving control : Headrest Backward";
CM_ SG_ 578 C_RRLumbarUpSw_HU "2nd Right side seat Moving control : Lumbar Up";
CM_ SG_ 578 C_RRLumbarMidSw_HU "2nd Right side seat Moving control : Lumbar Mid";
CM_ SG_ 578 C_RRLegSupBwdSw_HU "2nd Right side seat Moving control : Leg Support Backward";
CM_ SG_ 578 C_RRLumbarLowSw_HU "2nd Right side seat Moving control : Lumbar Low";
CM_ SG_ 578 C_RRLumbarDefSw_HU "2nd Right side seat Moving control : Lumbar Deflate";
CM_ SG_ 578 C_RRBolsterInfSw_HU "2nd Right side seat Moving control : Bolster Inflate";
CM_ SG_ 578 C_RRLegSupUpSw_HU "2nd Right side seat Moving control : Leg Support Up";
CM_ SG_ 578 C_RROneTchNValueSet "2nd Right side seat One Touch Mode";
CM_ SG_ 578 C_RLOneTchNValueSet "2nd Left side seat One Touch Mode";
CM_ SG_ 578 C_RRBolsterDefSw_HU "2nd Right side seat Moving control : Bolster Deflate";
CM_ SG_ 578 C_AstRlxTiltUpSw_HU "Assistant seat Moving control : Relaxtion Tilt Up";
CM_ SG_ 578 C_AstRlxTiltDnSw_HU "Assistant seat Moving control : Relaxtion Tilt Down";
CM_ SG_ 578 C_RLRSEUpSw_HU "2nd Left side seat Moving control : RSE Up";
CM_ SG_ 578 C_RLRSEDnSw_HU "2nd Left side seat Moving control : RSE Down";
CM_ SG_ 578 C_RRRSEUpSw_HU "2nd Right side seat Moving control : RSE Up";
CM_ SG_ 578 C_RRLegSupDnSw_HU "2nd Right side seat Moving control : Leg Support Down";
CM_ SG_ 578 C_RRRSEDnSw_HU "2nd Right side seat Moving control : RSE Down";
CM_ SG_ 578 C_RRHrestUpSw_HU "2nd Right side seat Moving control : Headrest Up";
CM_ BO_ 95 "[EC] On Event and On Change";
CM_ SG_ 95 CF_AVN_AIVoiceModNvalueSet "Signal of mood lamp concern about AI voice";
CM_ SG_ 95 CF_AVN_AIVoiceMicModNvalue "Signal of AI voice size HU to MLM";
CM_ SG_ 95 CF_AVN_AIVoiceTTSModNvalue "Signal TTS Mode HU to MLM";
CM_ BO_ 2281833729 "[P] Periodic";
CM_ SG_ 2281833729 ICSC_Crc2Val "ICSC_CyclicRedundancyCheck2Value";
CM_ SG_ 2281833729 ICSC_AlvCnt2Val "ICSC_AliveCounter2Value";
CM_ SG_ 2281833729 DMIC_DrvModSta "DMIC_DriveModeStatus ##2G##ICSC - IVSS11 - DrivingModeState";
CM_ SG_ 2281833729 DMIC_SmtShftModSta "DMIC_SmartShiftModeStatus ##2G##ICSC - IVSS11 - SMART_SHIFT_MODE";
CM_ SG_ 2281833729 DMIC_EngModSta "DMIC_EngineModeStatus ##2G##ICSC - IVSS11 - MODE_ENG";
CM_ SG_ 2281833729 DMIC_IndEngModSta "DMIC_IndividualEngineModeStatus ##2G##ICSC - IVSS11 - MODE_PT_IND";
CM_ SG_ 2281833729 DMIC_TmModSta "DMIC_TmModeStatus ##2G##ICSC - IVSS11 - MODE_TM";
CM_ SG_ 2281833729 DMIC_IndTmModSta "DMIC_IndividualTmModeStatus";
CM_ SG_ 2281833729 DMIC_EscModSta "DMIC_EscModeStatus ##2G##ICSC - IVSS11 - MODE_ESC";
CM_ SG_ 2281833729 DMIC_IndEscModSta "DMIC_IndividualEscModeStatus ##2G##ICSC - IVSS11 - MODE_ESC_IND";
CM_ SG_ 2281833729 DMIC_MdpsModSta "DMIC_MdpsModeStatus ##2G##ICSC - IVSS11 - MODE_MDPS";
CM_ SG_ 2281833729 DMIC_IndMdpsModSta "DMIC_IndividualMdpsModeStatus ##2G##ICSC - IVSS11 - MODE_MDPS_IND";
CM_ BO_ 2281833731 "[P] Periodic";
CM_ SG_ 2281833731 DMIC_VcuModSta "VCU: DMIC_VcuModeStatus like a #2G# IVSS11-MODE_ENG";
CM_ SG_ 2281833731 DMIC_DrvModTyp "DMIC_DriveModeType ##2G##ICSC - IVSS11 - DRIVE_MODE_TYPE";
CM_ SG_ 2281833731 DMIC_EngFltSta "DMIC_EngineFaultStatus ##2G##ICSC - IVSS11 - MODE_ENG_FltStat";
CM_ SG_ 2281833731 DMIC_TmFltSta "DMIC_TransmissionFaultStatus ##2G##ICSC - IVSS11 - MODE_TM_FltStat";
CM_ SG_ 2281833731 DMIC_EscFltSta "DMIC_EscFaultStatus ##2G##ICSC - IVSS11 - MODE_ESC_FltStat";
CM_ SG_ 2281833731 DMIC_MdpsFltSta "DMIC_MdpsFaultStatus ##2G##ICSC - IVSS11 - MODE_MDPS_FltStat";
CM_ SG_ 2281833731 DMIC_EcsFltSta "DMIC_EcsFltSta ##2G##ICSC - IVSS11 - MODE_ECS_FltStat";
CM_ SG_ 2281833731 DMIC_AwdFltSta "DMIC_AwdFaultStatus ##2G##ICSC - IVSS11 - MODE_4WD_FltStat";
CM_ SG_ 2281833731 DMIC_RevFltSta "DMIC_RevFaultStatus ##2G##ICSC - IVSS11 - MODE_REV_FltStat";
CM_ SG_ 2281833731 DMIC_PrflFltSta "DMIC_PrefillFaultStatus ##2G##ICSC - IVSS11 - MODE_PRFL_FltStat";
CM_ SG_ 2281833731 DMIC_ElsdFltSta "DMIC_ElsdFaultStatus ##2G##ICSC - IVSS11 - MODE_ELSD_FltStat";
CM_ SG_ 2281833731 DMIC_EsndFltSta "DMIC_EsndFaultStatus ##2G##ICSC - IVSS11 - MODE_ENSD_FltStat";
CM_ SG_ 2281833731 DMIC_RwsFltSta "DMIC_RwsFaultStatus";
CM_ SG_ 2281833731 DMIC_IndVcuModSta "VCU: DMIC_IndividualVcuModeStatus like a #2G# IVSS11-MODE_ENG_IND";
CM_ SG_ 2281833731 DMIC_VcuFltSta "VCU: DMIC_VcuFaultStatus like a ##2G##ICSC - IVSS11 - MODE_ENG_FltStat";
CM_ SG_ 2281833731 DMIC_DrvMod2Typ "DMIC_DriveModeType2 ##2G##ICSC - IVSS11 - DRIVE_MODE_TYPE";
CM_ SG_ 2281833731 DMIC_DrvModFltSta "DMIC_DriveModeFaultStatus ##2G##ICSC - IVSS11 - MODE_DRIVING_FltStat";
CM_ BO_ 1041 "[PE] Periodic and On Event";
CM_ SG_ 1041 ICU_Crc2Val "ICU_CyclicRedundancyCheck2Value";
CM_ SG_ 1041 ICU_MtGearPosRSta "##2G## -  - C_InhibitRMT,CF_Gway_InhibitRMT";
CM_ SG_ 1041 ICU_AlvCnt2Val "ICU_AliveCounter2Value";
CM_ SG_ 1041 Autocut_DlvryModSta "Autocut_DeliveryModeStatus ##2G## -  - C_SJBDeliveryMode,CF_Gway_SJBDeliveryMode";
CM_ SG_ 1041 DoorLock_AsstDrUnLkSta "DoorLock_AssistDoorUnLockStatus ##2G## -  - C_AstUnlockState,DoorLock_AsstDrUnLkSta";
CM_ SG_ 1041 Warn_DrvDrSwSta "DoorLock_DriverDoorSwitchStatus ##2G## -  - C_DrvDrSw,CF_Gway_DrvDrSw,Warn_DrvDrSwSta";
CM_ SG_ 1041 DoorLock_DrvKeyUnLkSwSta "DoorLock_DriverKeyUnLockSwitchStatus ##2G## -  - C_DrvKeyUnlockSw";
CM_ SG_ 1041 DoorLock_RrLftDrUnLkSta "DoorLock_RearLeftDoorUnLockStatus ##2G## -  - C_RLUnlockState,DoorLock_RrLftDrUnLkSta";
CM_ SG_ 1041 DoorLock_RrRtDrUnLkSta "DoorLock_RearRightDoorUnLockStatus ##2G## -  - C_RRUnlockState,DoorLock_RrRtDrUnLkSta";
CM_ SG_ 1041 Warn_AsstDrSwSta "Warn_AssistDoorSwitchStatus ##2G## -  - C_AstDrSw,CF_Gway_AstDrSw,Warn_AsstDrSwSta";
CM_ SG_ 1041 Warn_AsstStBltSwSta "Warn_AssistSeatBeltSwitchStatus ##2G## -  - C_AstSeatBeltSw,CF_Gway_AstSeatBeltSw";
CM_ SG_ 1041 Warn_BrkFldSwSta "Warn_BrakeFluidSwitchStatus ##2G## -  - C_BrakeFluidSw,CF_Gway_BrakeFluidSw";
CM_ SG_ 1041 DoorLock_DrvKeyLkSwSta "DoorLock_DriverKeyLockSwitchStatus ##2G## -  - C_DrvKeyLockSw";
CM_ SG_ 1041 Warn_DrvStBltSwSta "Warn_DriverSeatbeltSwitchStatus ##2G## -  - C_DrvSeatBeltSw,CF_Gway_DrvSeatBeltSw";
CM_ SG_ 1041 Warn_HoodSwSta "Warn_HoodSwitchStatus ##2G## -  - C_HoodSw,CF_Gway_HoodSw";
CM_ SG_ 1041 Warn_PassStOccSta "Warn_PassengerSeatOccupyStatus ##2G## -  - C_SBRMatSw";
CM_ SG_ 1041 Warn_PrkngBrkSwSta "Warn_ParkingBrakeSwitchStatus ##2G## -  - C_ParkBrakeSw";
CM_ SG_ 1041 Warn_RrCtrStBltSwSta "Warn_RearCenterSeatBeltSwitchStatus ##2G## -  - C_RCSeatBeltSw";
CM_ SG_ 1041 Warn_RrLftDrSwSta "Warn_RearLeftDoorSwitchStatus ##2G## -  - C_RLDrSw,CF_Gway_RLDrSw,Warn_RrLftDrSwSta";
CM_ SG_ 1041 Warn_RrLftStBltSwSta "Warn_RearLeftSeatBeltSwitchStatus ##2G## -  - C_RLSeatBeltSw";
CM_ SG_ 1041 Warn_RrRtDrSwSta "Warn_RearRightDoorSwitchStatus ##2G## -  - C_RRDrSw,CF_Gway_RRDrSw,Warn_RrRtDrSwSta";
CM_ SG_ 1041 Warn_RrRtStBltSwSta "Warn_RearRightSeatBeltSwitchStatus ##2G## -  - C_RRSeatBeltSw";
CM_ SG_ 1041 Warn_HoodSwMemorySta "Warn_HoodSwitchMemoryStatus ##2G## -  - CF_Hoodsw_memory,C_HoodSwMemory";
CM_ SG_ 1041 Warn_WshrFldSwSta "Washer Fluid Switch Signal ##2G## -  - CF_Gway_WasherFluidSw";
CM_ SG_ 1041 ICU_Haptic_OPT "Steering Wheel Haptic Warning Option Infomation ##2G## -  - C_ICU_Haptic_OPT";
CM_ BO_ 1043 "[PE] Periodic and On Event";
CM_ SG_ 1043 ICU_Crc4Val "ICU_CyclicRedundancyCheck4Value";
CM_ SG_ 1043 Lamp_TrnSigLmpRtActiveSt "Lamp_TurnSignalLampRightActiveState";
CM_ SG_ 1043 ICU_AlvCnt4Val "ICU_AliveCounter4Value";
CM_ SG_ 1043 ExtLamp_HzrdSwSta "ExtLamp_HazardSwitchStatus ##2G## -  - C_HazardSw,CF_Gway_HazardSw";
CM_ SG_ 1043 IntLamp_InlTailLmpSta "IntLamp_InternalTailLampStatus ##2G## -  - C_IntTailAct,CF_Gway_IntTailAct";
CM_ SG_ 1043 Lamp_LedHdLmpSta "Lamp_LedHeadLampStatus ##2G## -  - CF_Afs_LedHLStat";
CM_ SG_ 1043 Lamp_TrnSigLmpLftOnReq "Lamp_TurnSignalLampLeftOnRequest ##2G## -  - Lamp_TsigLmpFrtLftOnReq";
CM_ SG_ 1043 Lamp_TrnSigLmpRtOnReq "Lamp_TurnSignalLampRightOnRequest ##2G## -  - Lamp_TSigLmpRtLftOnReq";
CM_ SG_ 1043 Lamp_TrnSigLmpLftActiveSt "Lamp_TurnSignalLampLeftActiveState";
CM_ BO_ 1044 "[PE] Periodic and On Event";
CM_ SG_ 1044 ICU_Crc5Val "ICU_CyclicRedundancyCheck5Value";
CM_ SG_ 1044 ICU_AlvCnt5Val "ICU_AliveCounter5Value";
CM_ SG_ 1044 Trunk_TrnkInReleaseSwSta "Trunk_TrunkInnerReleaseSwitchStatus ##2G## -  - C_TrunkInnerReleaseSw";
CM_ SG_ 1044 Trunk_TrnkTlgtOutReleaseSwSta "Trunk_TrunkTailgateOutReleaseSwitchStatus ##2G## -  - C_TrunkTgOtrReleaseSW";
CM_ SG_ 1044 Trunk_TrnkTlgtSwSta "Trunk_TrunkTailgateSwitchStatus ##2G## -  - C_TrunkTgSw,CF_Gway_TrunkTgSw,Trunk_TrnkTlgtSwSta";
CM_ SG_ 1044 Trunk_GlvBxTrnkLkSwSta "Trunk_GloveBoxTrunkLockSwitchStatus ##2G## -  - C_GloveBoxTrunkLockSw";
CM_ SG_ 1044 Trunk_TlgtFullOpnSwSta "Trunk_TailGateFullOpenSwitchStatus ##2G## -  - C_TgFullOpenSW";
CM_ SG_ 1044 Trunk_TrnkTlgtReleaseRlySta "Trunk_TrunkTailgateReleaseRelayStatus ##2G## -  - C_TrunkTgReleaseRlyAct";
CM_ SG_ 1044 USM_OneTouchTrnSigFuncSta "USM_OneTouchTurnSignalFunctionStatus ##2G## -  - CF_Gway_OTTurnRValue,C_OTTurnRValue";
CM_ SG_ 1044 DoorLock_DrvDrUnLkSta "DoorLock_DriverDoorUnLockStatus ##2G## -  - C_DrvUnlockState,CF_Gway_DrvUnlockState";
CM_ SG_ 1044 DoorLock_LkOutSta "DoorLock_LockOutputStatus ##2G## -  - C_LockUnlockOutState";
CM_ SG_ 1044 C_CrashUnlockState "Crash Unlock Active State";
CM_ SG_ 1044 C_AutoLeverManualSW "Auto Lever Manual Switch Status Information";
CM_ BO_ 1048 "[PE] Periodic and On Event";
CM_ SG_ 1048 ICU_Crc8Val "ICU_CyclicRedundancyCheck8Value";
CM_ SG_ 1048 ICU_AlvCnt8Val "ICU_AliveCounter8Value";
CM_ SG_ 1048 DriveTypeOption "##2G## -  - C_DriveTypeOption,CF_Gway_DriveTypeOption";
CM_ SG_ 1048 Warn_RrLftSBRMATSwSta "##2G## -  - C_RLSBRMatSw";
CM_ SG_ 1048 Warn_RrRhtSBRMATSwSta "##2G## -  - C_RRSBRMatSw";
CM_ SG_ 1048 Lamp_FootLampOnReq "##2G## -  - C_FootLpOn";
CM_ SG_ 1048 Lamp_MoodLampOnReq "##2G## -  - C_MoodLpOn";
CM_ SG_ 1048 ICU_PowerAutoCutModSta "##2G## -  - CF_Gway_ICUPowerAutoCutMode";
CM_ SG_ 1048 ICU_SoCBattStaMsgReq "##2G## -  - Batt_SoCWarningAlertMsgReq";
CM_ SG_ 1048 Brake_SwSta_ICU "Brake Switch Status ##2G## -  - C_BrakeSw";
CM_ SG_ 1048 C_3rdRRSeatBeltSW "3rd Rear Right Seat Belt Switch Status";
CM_ SG_ 1048 C_3rdRLSeatBeltSW "3rd Rear Left Seat Belt Switch Status";
CM_ SG_ 1048 HSWS_SysWrngSta_ICU "HSWS Status ##2G## -  - C_HSWSSysStat";
CM_ BO_ 1040 "[PE] Periodic and On Event";
CM_ SG_ 1040 ICU_Crc10Val "ICU_CyclicRedundancyCheck10Value";
CM_ SG_ 1040 ICU_AlvCnt10Val "ICU_AliveCounter10Value";
CM_ SG_ 1040 ICU_BS2SoC "This signal is battery State of Charge as calculated by battery sensor. ##2G## -  - BS2_SOC,Batt_SoC";
CM_ SG_ 1040 ICU_BS2NCap "Nominal capacity ##2G## -  - BS2_CNOM";
CM_ SG_ 1040 ICU_BS2OpnCirVol "Last open circuit voltage ##2G## -  - BS2_OCV";
CM_ SG_ 1040 ICU_BS2_FSOC "Fault State of SOC";
CM_ SG_ 1040 ICU_BS2_FSOH "Fault State of SOH";
CM_ SG_ 1040 ICU_BS2_FSOF "Fault State of SOF";
CM_ SG_ 1040 ICU_BS2_FQSTAT "State of quiescent current";
CM_ SG_ 1040 ICU_BS2SoH "This signal is battery State of Health(SOH) as calculated by battery sensor. ##2G## -  - BAT_SOH";
CM_ SG_ 1040 ICU_BS2SoF "This signal is battery State of Function(SOF) as calculated by battery sensor. ##2G## -  - BAT_SOF";
CM_ BO_ 1029 "[PE] Periodic and On Event";
CM_ SG_ 1029 ICU_Crc12Val "ICU_CyclicRedundancyCheck12Value";
CM_ SG_ 1029 Warn_ChaDrSwRrSta "##2G## -  - CF_Gway_ChaDrSwRr";
CM_ SG_ 1029 ICU_AlvCnt12Val "ICU_AliveCounter12Value";
CM_ SG_ 1029 DoorLock_CtrlDrLkSwSta_ICU "Central Door Lock Switch State(DRV or AST or RL or RR Door trim)";
CM_ SG_ 1029 DoorLock_CtrlDrUnLkSwSta_ICU "Central Door Unlock Switch State(DRV or AST or RL or RR Door trim)";
CM_ SG_ 1029 DoorLock_CtrlDrLkUnLkSwSta_ICU "Central Door Lock/Unlock Switch State(C/PAD, Integrated & self return type)";
CM_ SG_ 1029 HEV_IGN3On_Req "HEV IGN3 Relay Control Request State";
CM_ SG_ 1029 AutoLtOpt "Auto Light »ç¾ç Àû¿ë ¿©ºÎ ¹× Àû¿ë ¿É¼Ç Á¤º¸ Ãâ·Â (¹ÌÀû¿ë/Àû¿ë)";
CM_ SG_ 1029 ICU_IGN3On_ReqState_New "EV IGN3 Relay Request unit State";
CM_ SG_ 1029 ICU_BattMngAlert "This signal is for battery discharge warning.";
CM_ SG_ 1029 HLmpLoHiOptLtSrcTyp "Head Low&High Lamp »ç¾ç Àû¿ë ¿©ºÎ ¹× Light Source Type, ¿É¼Ç Á¤º¸ Ãâ·Â";
CM_ SG_ 1029 Warn_ChaDrSwFrtSta "##2G## - -  CF_Gway_ChaDrSwFrt";
CM_ BO_ 1067 "[PE] Periodic and On Event";
CM_ SG_ 1067 SCM_SWVerMajor1 "First Word(ASCII) in SCM S/W Ver";
CM_ SG_ 1067 SCM_SWVerMinor1 "Second Word(ASCII) in SCM S/W Ver";
CM_ SG_ 1067 SCM_SWVerMinor2 "Third Word(ASCII) in SCM S/W Ver";
BA_DEF_ BO_ "DiagState" ENUM "No","Yes" ;
BA_DEF_ BO_ "DiagResponse" ENUM "No","Yes" ;
BA_DEF_ BO_ "DiagRequest" ENUM "No","Yes" ;
BA_DEF_ BO_ "TpMessage" ENUM "No","Yes" ;
BA_DEF_ BO_ "UsrMsgIDSforwardDeviation" INT 0 100 ;
BA_DEF_ BO_ "UsrMsgIDSbackwardDeviation" INT 50 1000 ;
BA_DEF_ BO_ "GenMsgCycleTime" INT 0 2000 ;
BA_DEF_ BO_ "GenMsgStartDelayTime" INT 0 2000 ;
BA_DEF_ BO_ "GenMsgSendType" ENUM "Cyclic","NoMsgSendType" ;
BA_DEF_ BO_ "GenMsgCycleTimeFast" INT 0 500 ;
BA_DEF_ BO_ "GenMsgDelayTime" INT 0 20 ;
BA_DEF_ BO_ "GenMsgILSupport" ENUM "No","Yes" ;
BA_DEF_ BO_ "GenMsgNrOfRepetition" INT 0 3 ;
BA_DEF_ BO_ "NmMessage" ENUM "No","Yes" ;
BA_DEF_ BO_ "NWM-Botschaft" ENUM "No","Yes" ;
BA_DEF_ BO_ "TpTxIndex" INT 0 255 ;
BA_DEF_ BO_ "VFrameFormat" ENUM "StandardCAN","ExtendedCAN","reserved","reserved","reserved","reserved","reserved","reserved","reserved","reserved","reserved","reserved","reserved","reserved","StandardCAN_FD","ExtendedCAN_FD" ;
BA_DEF_ SG_ "UserSigValidity" ENUM "B+","ACC","IG","IG1","IG2","IG3","IG1 or IG2","IG1 or IG3","Undef" ;
BA_DEF_ SG_ "TimeoutValue" STRING ;
BA_DEF_ SG_ "UsrSigPurpose" ENUM "Undef","FN","DIAG","DIAG(Req)","DIAG(Res)","DIAG(Phy)","DEV","CCP(Req)","CCP(Res)","NM","TP" ;
BA_DEF_ SG_ "GenSigStartValue" INT 0 1215752192 ;
BA_DEF_ SG_ "NetworkRequest" ENUM "Yes","No" ;
BA_DEF_ SG_ "NetworkRequestHoldingTime" INT 0 65535 ;
BA_DEF_ SG_ "Description" STRING ;
BA_DEF_ SG_ "Version" STRING ;
BA_DEF_ SG_ "GenSigEnvVarType" ENUM "Int","Float","Undef" ;
BA_DEF_ SG_ "GenSigSendType" ENUM "Cyclic","OnWrite","OnWriteWithRepetition","OnChange","OnChangeWithRepetition","IfActive","IfActiveWithRepetition","NoSigSendType","OnChangeAndIfActive","OnChangeAndIfActiveWithRepetition" ;
BA_DEF_ SG_ "GwSigLatencyTime" INT 0 65536 ;
BA_DEF_ SG_ "GwSigMissingSourceType" ENUM "Undef","OldValue","DefaultValue","InitialValue" ;
BA_DEF_ SG_ "NWM-WakeupAllowed" ENUM "<n.a.>" ;
BA_DEF_ SG_ "RoutingFactor" INT 1 1215752192 ;
BA_DEF_REL_ BU_SG_REL_ "GenSigTimeoutTime" INT 0 7000 ;
BA_DEF_DEF_ "DiagState" "No" ;
BA_DEF_DEF_ "DiagResponse" "No" ;
BA_DEF_DEF_ "DiagRequest" "No" ;
BA_DEF_DEF_ "TpMessage" "No" ;
BA_DEF_DEF_ "UsrMsgIDSforwardDeviation" 10 ;
BA_DEF_DEF_ "UsrMsgIDSbackwardDeviation" 100 ;
BA_DEF_DEF_ "GenMsgCycleTime" 200 ;
BA_DEF_DEF_ "GenMsgStartDelayTime" 0 ;
BA_DEF_DEF_ "GenMsgSendType" "NoMsgSendType" ;
BA_DEF_DEF_ "GenMsgCycleTimeFast" 40 ;
BA_DEF_DEF_ "GenMsgDelayTime" 20 ;
BA_DEF_DEF_ "GenMsgILSupport" "Yes" ;
BA_DEF_DEF_ "GenMsgNrOfRepetition" 3 ;
BA_DEF_DEF_ "NmMessage" "No" ;
BA_DEF_DEF_ "NWM-Botschaft" "No" ;
BA_DEF_DEF_ "TpTxIndex" 0 ;
BA_DEF_DEF_ "VFrameFormat" "StandardCAN" ;
BA_DEF_DEF_ "UserSigValidity" "IG" ;
BA_DEF_DEF_ "TimeoutValue" "" ;
BA_DEF_DEF_ "UsrSigPurpose" "FN" ;
BA_DEF_DEF_ "GenSigStartValue" 0 ;
BA_DEF_DEF_ "NetworkRequest" "No" ;
BA_DEF_DEF_ "NetworkRequestHoldingTime" 0 ;
BA_DEF_DEF_ "Description" "" ;
BA_DEF_DEF_ "Version" "" ;
BA_DEF_DEF_ "GenSigEnvVarType" "Undef" ;
BA_DEF_DEF_ "GenSigSendType" "NoSigSendType" ;
BA_DEF_DEF_ "GwSigLatencyTime" 40 ;
BA_DEF_DEF_ "GwSigMissingSourceType" "Undef" ;
BA_DEF_DEF_ "NWM-WakeupAllowed" "<n.a.>" ;
BA_DEF_DEF_ "RoutingFactor" 1 ;
BA_DEF_DEF_REL_ "GenSigTimeoutTime" 500 ;
BA_ "GenMsgSendType" BO_ 1030 0;
BA_ "Description" SG_ 1030 APSM_SWVerMajor1 "Indicate the SCM software version as follows:

- The software version is displayed in three digits.

- The Major and Minor digits are separated by '.'

- Signal values are transmitted to ASCII codes.



¡Ø Example

APSM_SWVerMajor1 : 0x41 (HEX) -> ASCII CODE : 'A' 

APSM_SWVerMinor1 : 0x30 (HEX) -> ASCII CODE : '0'

APSM_SWVerMinor2 : 0x33 (HEX) -> ASCII CODE : '3'

=> APSM S/W Ver is displayed 'A.03'";
BA_ "GenSigSendType" SG_ 1030 APSM_SWVerMajor1 4;
BA_ "UserSigValidity" SG_ 1030 APSM_SWVerMajor1 0;
BA_REL_ "GenSigTimeoutTime" BU_SG_REL_ CGW_CCU SG_ 1030 APSM_SWVerMajor1 1500;
BA_ "Version" SG_ 1030 APSM_SWVerMajor1 "21.07.00";
BA_ "Description" SG_ 1030 APSM_SWVerMinor1 "Indicate the APSM software version as follows:

- The software version is displayed in three digits.

- The Major and Minor digits are separated by '.'

- Signal values are transmitted to ASCII codes.



¡Ø Example

APSM_SWVerMajor1 : 0x41 (HEX) -> ASCII CODE : 'A' 

APSM_SWVerMinor1 : 0x30 (HEX) -> ASCII CODE : '0'

APSM_SWVerMinor2 : 0x33 (HEX) -> ASCII CODE : '3'

=> APSM S/W Ver is displayed 'A.03'";
BA_ "GenSigSendType" SG_ 1030 APSM_SWVerMinor1 4;
BA_ "UserSigValidity" SG_ 1030 APSM_SWVerMinor1 0;
BA_REL_ "GenSigTimeoutTime" BU_SG_REL_ CGW_CCU SG_ 1030 APSM_SWVerMinor1 1500;
BA_ "Version" SG_ 1030 APSM_SWVerMinor1 "18.10.06";
BA_ "Description" SG_ 1030 APSM_SWVerMinor2 "Indicate the APSM software version as follows:

- The software version is displayed in three digits.

- The Major and Minor digits are separated by '.'

- Signal values are transmitted to ASCII codes.



¡Ø Example

APSM_SWVerMajor1 : 0x41 (HEX) -> ASCII CODE : 'A' 

APSM_SWVerMinor1 : 0x30 (HEX) -> ASCII CODE : '0'

APSM_SWVerMinor2 : 0x33 (HEX) -> ASCII CODE : '3'

=> APSM S/W Ver is displayed 'A.03'";
BA_ "GenSigSendType" SG_ 1030 APSM_SWVerMinor2 4;
BA_ "UserSigValidity" SG_ 1030 APSM_SWVerMinor2 0;
BA_REL_ "GenSigTimeoutTime" BU_SG_REL_ CGW_CCU SG_ 1030 APSM_SWVerMinor2 1500;
BA_ "Version" SG_ 1030 APSM_SWVerMinor2 "18.10.06";
BA_ "GenMsgSendType" BO_ 1031 0;
BA_ "GenSigSendType" SG_ 1031 APSM_AstStEsyAcsUSMSta 4;
BA_ "UserSigValidity" SG_ 1031 APSM_AstStEsyAcsUSMSta 0;
BA_REL_ "GenSigTimeoutTime" BU_SG_REL_ CGW_CCU SG_ 1031 APSM_AstStEsyAcsUSMSta 1500;
BA_ "NetworkRequest" SG_ 1031 APSM_AstStEsyAcsUSMSta 0;
BA_ "NetworkRequestHoldingTime" SG_ 1031 APSM_AstStEsyAcsUSMSta 5000;
BA_ "Version" SG_ 1031 APSM_AstStEsyAcsUSMSta "19.08.08";
BA_ "Description" SG_ 1031 APSM_WalkInEnable "Apsm Walk In Mode Enable/Disable";
BA_ "GenSigSendType" SG_ 1031 APSM_WalkInEnable 4;
BA_ "UserSigValidity" SG_ 1031 APSM_WalkInEnable 0;
BA_ "NetworkRequest" SG_ 1031 APSM_WalkInEnable 0;
BA_ "NetworkRequestHoldingTime" SG_ 1031 APSM_WalkInEnable 5000;
BA_ "Version" SG_ 1031 APSM_WalkInEnable "19.07.06";
BA_ "GenSigSendType" SG_ 1031 APSM_LimSetSta 4;
BA_ "UserSigValidity" SG_ 1031 APSM_LimSetSta 0;
BA_ "NetworkRequest" SG_ 1031 APSM_LimSetSta 0;
BA_ "NetworkRequestHoldingTime" SG_ 1031 APSM_LimSetSta 5000;
BA_ "Version" SG_ 1031 APSM_LimSetSta "21.04.01";
BA_ "Description" SG_ 1031 APSM_FootRest_Opt "Foot Rest OPTION";
BA_ "GenSigSendType" SG_ 1031 APSM_FootRest_Opt 4;
BA_ "UserSigValidity" SG_ 1031 APSM_FootRest_Opt 0;
BA_ "NetworkRequest" SG_ 1031 APSM_FootRest_Opt 0;
BA_ "NetworkRequestHoldingTime" SG_ 1031 APSM_FootRest_Opt 5000;
BA_ "Version" SG_ 1031 APSM_FootRest_Opt "19.11.05";
BA_ "Description" SG_ 1031 APSM_RSE_Opt "RSE OPTION";
BA_ "GenSigSendType" SG_ 1031 APSM_RSE_Opt 4;
BA_ "UserSigValidity" SG_ 1031 APSM_RSE_Opt 0;
BA_ "NetworkRequest" SG_ 1031 APSM_RSE_Opt 0;
BA_ "NetworkRequestHoldingTime" SG_ 1031 APSM_RSE_Opt 5000;
BA_ "Version" SG_ 1031 APSM_RSE_Opt "20.07.11";
BA_ "GenMsgSendType" BO_ 1064 0;
BA_ "Description" SG_ 1064 APSU_DiagSta "(Old)C_APSU_DiagState";
BA_ "GenSigSendType" SG_ 1064 APSU_DiagSta 4;
BA_ "UserSigValidity" SG_ 1064 APSU_DiagSta 0;
BA_ "NetworkRequest" SG_ 1064 APSU_DiagSta 0;
BA_ "NetworkRequestHoldingTime" SG_ 1064 APSU_DiagSta 5000;
BA_ "Version" SG_ 1064 APSU_DiagSta "17.11.00";
BA_ "Description" SG_ 1064 APSU_AstAllLmtSta "°¡»ó ¸®¹ÌÆ® ¼³Á¤ »óÅÂ Á¤º¸

Virtual Limit Set State (Not Set / All Set)";
BA_ "GenSigSendType" SG_ 1064 APSU_AstAllLmtSta 4;
BA_ "UserSigValidity" SG_ 1064 APSU_AstAllLmtSta 0;
BA_REL_ "GenSigTimeoutTime" BU_SG_REL_ RLPSU SG_ 1064 APSU_AstAllLmtSta 1500;
BA_REL_ "GenSigTimeoutTime" BU_SG_REL_ RRPSU SG_ 1064 APSU_AstAllLmtSta 1500;
BA_ "Version" SG_ 1064 APSU_AstAllLmtSta "20.12.04";
BA_ "Description" SG_ 1064 APSU_EsyAcsGetOnSta "Easy Access Get On Information";
BA_ "GenSigSendType" SG_ 1064 APSU_EsyAcsGetOnSta 4;
BA_ "UserSigValidity" SG_ 1064 APSU_EsyAcsGetOnSta 0;
BA_REL_ "GenSigTimeoutTime" BU_SG_REL_ ALBCU SG_ 1064 APSU_EsyAcsGetOnSta 1500;
BA_ "NetworkRequest" SG_ 1064 APSU_EsyAcsGetOnSta 0;
BA_ "NetworkRequestHoldingTime" SG_ 1064 APSU_EsyAcsGetOnSta 5000;
BA_ "Version" SG_ 1064 APSU_EsyAcsGetOnSta "17.11.00";
BA_ "Description" SG_ 1064 APSU_EsyAcsGetOffSta "Easy Access Get Off Information";
BA_ "GenSigSendType" SG_ 1064 APSU_EsyAcsGetOffSta 4;
BA_ "UserSigValidity" SG_ 1064 APSU_EsyAcsGetOffSta 0;
BA_REL_ "GenSigTimeoutTime" BU_SG_REL_ ALBCU SG_ 1064 APSU_EsyAcsGetOffSta 1500;
BA_ "NetworkRequest" SG_ 1064 APSU_EsyAcsGetOffSta 0;
BA_ "NetworkRequestHoldingTime" SG_ 1064 APSU_EsyAcsGetOffSta 5000;
BA_ "Version" SG_ 1064 APSU_EsyAcsGetOffSta "17.11.00";
BA_ "Description" SG_ 1064 APSU_EsyAcsStpSta "Easy Access Stop Information";
BA_ "GenSigSendType" SG_ 1064 APSU_EsyAcsStpSta 4;
BA_ "UserSigValidity" SG_ 1064 APSU_EsyAcsStpSta 0;
BA_REL_ "GenSigTimeoutTime" BU_SG_REL_ ALBCU SG_ 1064 APSU_EsyAcsStpSta 1500;
BA_ "NetworkRequest" SG_ 1064 APSU_EsyAcsStpSta 0;
BA_ "NetworkRequestHoldingTime" SG_ 1064 APSU_EsyAcsStpSta 5000;
BA_ "Version" SG_ 1064 APSU_EsyAcsStpSta "17.11.00";
BA_ "GenSigSendType" SG_ 1064 APSU_RVal 4;
BA_ "UserSigValidity" SG_ 1064 APSU_RVal 0;
BA_ "NetworkRequest" SG_ 1064 APSU_RVal 0;
BA_ "NetworkRequestHoldingTime" SG_ 1064 APSU_RVal 5000;
BA_ "Version" SG_ 1064 APSU_RVal "17.11.00";
BA_ "GenMsgCycleTime" BO_ 639 0;
BA_ "Description" SG_ 639 ATS_RRSeatHeaterSW "ÈÄ¼® RH ½ÃÆ® ¿­¼± Á¶Àý";
BA_ "GenSigSendType" SG_ 639 ATS_RRSeatHeaterSW 4;
BA_ "UserSigValidity" SG_ 639 ATS_RRSeatHeaterSW 3;
BA_REL_ "GenSigTimeoutTime" BU_SG_REL_ RRHV SG_ 639 ATS_RRSeatHeaterSW 0;
BA_REL_ "GenSigTimeoutTime" BU_SG_REL_ SHVU_RR SG_ 639 ATS_RRSeatHeaterSW 0;
BA_ "NetworkRequest" SG_ 639 ATS_RRSeatHeaterSW 0;
BA_ "NetworkRequestHoldingTime" SG_ 639 ATS_RRSeatHeaterSW 5000;
BA_ "Version" SG_ 639 ATS_RRSeatHeaterSW "20.07.01";
BA_ "Description" SG_ 639 ATS_RLSeatHeaterUpSW "ÈÄ¼® LH ½ÃÆ® ¿­¼± Á¶Àý";
BA_ "GenSigSendType" SG_ 639 ATS_RLSeatHeaterUpSW 4;
BA_ "UserSigValidity" SG_ 639 ATS_RLSeatHeaterUpSW 3;
BA_REL_ "GenSigTimeoutTime" BU_SG_REL_ RLHV SG_ 639 ATS_RLSeatHeaterUpSW 0;
BA_REL_ "GenSigTimeoutTime" BU_SG_REL_ SHVU_RR SG_ 639 ATS_RLSeatHeaterUpSW 0;
BA_ "NetworkRequest" SG_ 639 ATS_RLSeatHeaterUpSW 0;
BA_ "NetworkRequestHoldingTime" SG_ 639 ATS_RLSeatHeaterUpSW 5000;
BA_ "Version" SG_ 639 ATS_RLSeatHeaterUpSW "20.12.04";
BA_ "Description" SG_ 639 ATS_RRSeatVentDownSW "ÈÄ¼® RH ½ÃÆ® ÅëÇ³ Á¶Àý";
BA_ "GenSigSendType" SG_ 639 ATS_RRSeatVentDownSW 4;
BA_ "UserSigValidity" SG_ 639 ATS_RRSeatVentDownSW 3;
BA_REL_ "GenSigTimeoutTime" BU_SG_REL_ RRHV SG_ 639 ATS_RRSeatVentDownSW 0;
BA_REL_ "GenSigTimeoutTime" BU_SG_REL_ SHVU_RR SG_ 639 ATS_RRSeatVentDownSW 0;
BA_ "NetworkRequest" SG_ 639 ATS_RRSeatVentDownSW 0;
BA_ "NetworkRequestHoldingTime" SG_ 639 ATS_RRSeatVentDownSW 5000;
BA_ "Version" SG_ 639 ATS_RRSeatVentDownSW "20.12.04";
BA_ "Description" SG_ 639 ATS_RLSeatVentDownSW "ÈÄ¼® LH ½ÃÆ® ÅëÇ³ Á¶Àý";
BA_ "GenSigSendType" SG_ 639 ATS_RLSeatVentDownSW 4;
BA_ "UserSigValidity" SG_ 639 ATS_RLSeatVentDownSW 3;
BA_REL_ "GenSigTimeoutTime" BU_SG_REL_ RLHV SG_ 639 ATS_RLSeatVentDownSW 0;
BA_REL_ "GenSigTimeoutTime" BU_SG_REL_ SHVU_RR SG_ 639 ATS_RLSeatVentDownSW 0;
BA_ "NetworkRequest" SG_ 639 ATS_RLSeatVentDownSW 0;
BA_ "NetworkRequestHoldingTime" SG_ 639 ATS_RLSeatVentDownSW 5000;
BA_ "Version" SG_ 639 ATS_RLSeatVentDownSW "20.12.04";
BA_ "Description" SG_ 639 ATS_RLMemoryRestBtn "Rear Left Rest Mode Custom Save Button (Except North America)";
BA_ "GenSigSendType" SG_ 639 ATS_RLMemoryRestBtn 4;
BA_ "UserSigValidity" SG_ 639 ATS_RLMemoryRestBtn 3;
BA_ "NetworkRequest" SG_ 639 ATS_RLMemoryRestBtn 0;
BA_ "NetworkRequestHoldingTime" SG_ 639 ATS_RLMemoryRestBtn 5000;
BA_ "Version" SG_ 639 ATS_RLMemoryRestBtn "21.01.02";
BA_ "Description" SG_ 639 ATS_RLMemoryReturnBtn "Rear Left Return Mode Custom Save Button (Except North America)";
BA_ "GenSigSendType" SG_ 639 ATS_RLMemoryReturnBtn 4;
BA_ "UserSigValidity" SG_ 639 ATS_RLMemoryReturnBtn 3;
BA_ "NetworkRequest" SG_ 639 ATS_RLMemoryReturnBtn 0;
BA_ "NetworkRequestHoldingTime" SG_ 639 ATS_RLMemoryReturnBtn 5000;
BA_ "Version" SG_ 639 ATS_RLMemoryReturnBtn "21.01.02";
BA_ "Description" SG_ 639 ATS_RLSeatHeaterSW "ÈÄ¼® LH ½ÃÆ® ¿­¼± Á¶Àý";
BA_ "GenSigSendType" SG_ 639 ATS_RLSeatHeaterSW 4;
BA_ "UserSigValidity" SG_ 639 ATS_RLSeatHeaterSW 3;
BA_REL_ "GenSigTimeoutTime" BU_SG_REL_ RLHV SG_ 639 ATS_RLSeatHeaterSW 0;
BA_REL_ "GenSigTimeoutTime" BU_SG_REL_ SHVU_RR SG_ 639 ATS_RLSeatHeaterSW 0;
BA_ "NetworkRequest" SG_ 639 ATS_RLSeatHeaterSW 0;
BA_ "NetworkRequestHoldingTime" SG_ 639 ATS_RLSeatHeaterSW 5000;
BA_ "Version" SG_ 639 ATS_RLSeatHeaterSW "20.07.01";
BA_ "Description" SG_ 639 ATS_RRMemoryRestBtn "Rear Right Rest Mode Custom Save Button (Except North America)";
BA_ "GenSigSendType" SG_ 639 ATS_RRMemoryRestBtn 4;
BA_ "UserSigValidity" SG_ 639 ATS_RRMemoryRestBtn 3;
BA_ "NetworkRequest" SG_ 639 ATS_RRMemoryRestBtn 0;
BA_ "NetworkRequestHoldingTime" SG_ 639 ATS_RRMemoryRestBtn 5000;
BA_ "Version" SG_ 639 ATS_RRMemoryRestBtn "21.01.02";
BA_ "Description" SG_ 639 ATS_RRMemoryReturnBtn "Rear Right Return Mode Custom Save Button (Except North America)";
BA_ "GenSigSendType" SG_ 639 ATS_RRMemoryReturnBtn 4;
BA_ "UserSigValidity" SG_ 639 ATS_RRMemoryReturnBtn 3;
BA_ "NetworkRequest" SG_ 639 ATS_RRMemoryReturnBtn 0;
BA_ "NetworkRequestHoldingTime" SG_ 639 ATS_RRMemoryReturnBtn 5000;
BA_ "Version" SG_ 639 ATS_RRMemoryReturnBtn "21.01.02";
BA_ "Description" SG_ 639 ATS_RRMemoryAvWtcBtn "Rear Right AV Watching Mode Custom Save Button (Except North America)";
BA_ "GenSigSendType" SG_ 639 ATS_RRMemoryAvWtcBtn 4;
BA_ "UserSigValidity" SG_ 639 ATS_RRMemoryAvWtcBtn 3;
BA_ "NetworkRequest" SG_ 639 ATS_RRMemoryAvWtcBtn 0;
BA_ "NetworkRequestHoldingTime" SG_ 639 ATS_RRMemoryAvWtcBtn 5000;
BA_ "Version" SG_ 639 ATS_RRMemoryAvWtcBtn "21.01.02";
BA_ "Description" SG_ 639 ATS_RRMemoryReadingBtn "Rear Right Reading Mode Custom Save Button (Except North America)";
BA_ "GenSigSendType" SG_ 639 ATS_RRMemoryReadingBtn 4;
BA_ "UserSigValidity" SG_ 639 ATS_RRMemoryReadingBtn 3;
BA_ "NetworkRequest" SG_ 639 ATS_RRMemoryReadingBtn 0;
BA_ "NetworkRequestHoldingTime" SG_ 639 ATS_RRMemoryReadingBtn 5000;
BA_ "Version" SG_ 639 ATS_RRMemoryReadingBtn "21.01.02";
BA_ "Description" SG_ 639 ATS_RRRestModBtnSTD "Rear Right Rest Mode Touch Button (EXCEPT North America)";
BA_ "GenSigSendType" SG_ 639 ATS_RRRestModBtnSTD 4;
BA_ "UserSigValidity" SG_ 639 ATS_RRRestModBtnSTD 3;
BA_ "NetworkRequest" SG_ 639 ATS_RRRestModBtnSTD 0;
BA_ "NetworkRequestHoldingTime" SG_ 639 ATS_RRRestModBtnSTD 5000;
BA_ "Version" SG_ 639 ATS_RRRestModBtnSTD "20.07.01";
BA_ "Description" SG_ 639 ATS_RRResetModBtnSTD "Rear Right Return Mode Touch Button (EXCEPT North America)";
BA_ "GenSigSendType" SG_ 639 ATS_RRResetModBtnSTD 4;
BA_ "UserSigValidity" SG_ 639 ATS_RRResetModBtnSTD 3;
BA_ "NetworkRequest" SG_ 639 ATS_RRResetModBtnSTD 0;
BA_ "NetworkRequestHoldingTime" SG_ 639 ATS_RRResetModBtnSTD 5000;
BA_ "Version" SG_ 639 ATS_RRResetModBtnSTD "20.07.01";
BA_ "Description" SG_ 639 ATS_RRAvWtcModBtnSTD "Rear Right AV Watching Mode Touch Button (EXCEPT North America)";
BA_ "GenSigSendType" SG_ 639 ATS_RRAvWtcModBtnSTD 4;
BA_ "UserSigValidity" SG_ 639 ATS_RRAvWtcModBtnSTD 3;
BA_ "NetworkRequest" SG_ 639 ATS_RRAvWtcModBtnSTD 0;
BA_ "NetworkRequestHoldingTime" SG_ 639 ATS_RRAvWtcModBtnSTD 5000;
BA_ "Version" SG_ 639 ATS_RRAvWtcModBtnSTD "20.07.01";
BA_ "Description" SG_ 639 ATS_RRReadingModBtnSTD "Rear Right Reading Mode Touch Button (EXCEPT North America)";
BA_ "GenSigSendType" SG_ 639 ATS_RRReadingModBtnSTD 4;
BA_ "UserSigValidity" SG_ 639 ATS_RRReadingModBtnSTD 3;
BA_ "NetworkRequest" SG_ 639 ATS_RRReadingModBtnSTD 0;
BA_ "NetworkRequestHoldingTime" SG_ 639 ATS_RRReadingModBtnSTD 5000;
BA_ "Version" SG_ 639 ATS_RRReadingModBtnSTD "20.07.01";
BA_ "Description" SG_ 639 ATS_RRSeatVentSW "ÈÄ¼® RH ½ÃÆ® ÅëÇ³ Á¶Àý";
BA_ "GenSigSendType" SG_ 639 ATS_RRSeatVentSW 4;
BA_ "UserSigValidity" SG_ 639 ATS_RRSeatVentSW 3;
BA_REL_ "GenSigTimeoutTime" BU_SG_REL_ RRHV SG_ 639 ATS_RRSeatVentSW 0;
BA_REL_ "GenSigTimeoutTime" BU_SG_REL_ SHVU_RR SG_ 639 ATS_RRSeatVentSW 0;
BA_ "NetworkRequest" SG_ 639 ATS_RRSeatVentSW 0;
BA_ "NetworkRequestHoldingTime" SG_ 639 ATS_RRSeatVentSW 5000;
BA_ "Version" SG_ 639 ATS_RRSeatVentSW "20.07.01";
BA_ "Description" SG_ 639 ATS_RLRestModBtnSTD "Rear Left Rest Mode Touch Button (EXCEPT North America)";
BA_ "GenSigSendType" SG_ 639 ATS_RLRestModBtnSTD 4;
BA_ "UserSigValidity" SG_ 639 ATS_RLRestModBtnSTD 3;
BA_ "NetworkRequest" SG_ 639 ATS_RLRestModBtnSTD 0;
BA_ "NetworkRequestHoldingTime" SG_ 639 ATS_RLRestModBtnSTD 5000;
BA_ "Version" SG_ 639 ATS_RLRestModBtnSTD "20.07.01";
BA_ "Description" SG_ 639 ATS_RLResetModBtnSTD "Rear Left Return Mode Touch Button (EXCEPT North America)";
BA_ "GenSigSendType" SG_ 639 ATS_RLResetModBtnSTD 4;
BA_ "UserSigValidity" SG_ 639 ATS_RLResetModBtnSTD 3;
BA_ "NetworkRequest" SG_ 639 ATS_RLResetModBtnSTD 0;
BA_ "NetworkRequestHoldingTime" SG_ 639 ATS_RLResetModBtnSTD 5000;
BA_ "Version" SG_ 639 ATS_RLResetModBtnSTD "20.07.01";
BA_ "Description" SG_ 639 ATS_RRModestateStopBtn "Rear Right One touch mode Stop Button";
BA_ "GenSigSendType" SG_ 639 ATS_RRModestateStopBtn 4;
BA_ "UserSigValidity" SG_ 639 ATS_RRModestateStopBtn 3;
BA_ "NetworkRequest" SG_ 639 ATS_RRModestateStopBtn 0;
BA_ "NetworkRequestHoldingTime" SG_ 639 ATS_RRModestateStopBtn 5000;
BA_ "Version" SG_ 639 ATS_RRModestateStopBtn "20.07.01";
BA_ "Description" SG_ 639 ATS_RLModestateStopBtn "Rear Left One touch mode Stop Button";
BA_ "GenSigSendType" SG_ 639 ATS_RLModestateStopBtn 4;
BA_ "UserSigValidity" SG_ 639 ATS_RLModestateStopBtn 3;
BA_ "NetworkRequest" SG_ 639 ATS_RLModestateStopBtn 0;
BA_ "NetworkRequestHoldingTime" SG_ 639 ATS_RLModestateStopBtn 5000;
BA_ "Version" SG_ 639 ATS_RLModestateStopBtn "20.07.01";
BA_ "Description" SG_ 639 ATS_RLResetRestBtn "Rear Left Rest Mode Custom Initialization Button (Except North America)";
BA_ "GenSigSendType" SG_ 639 ATS_RLResetRestBtn 4;
BA_ "UserSigValidity" SG_ 639 ATS_RLResetRestBtn 3;
BA_ "NetworkRequest" SG_ 639 ATS_RLResetRestBtn 0;
BA_ "NetworkRequestHoldingTime" SG_ 639 ATS_RLResetRestBtn 5000;
BA_ "Version" SG_ 639 ATS_RLResetRestBtn "21.01.02";
BA_ "Description" SG_ 639 ATS_RLResetReturnBtn "Rear Left Return Mode Custom Initialization Button (Except North America)";
BA_ "GenSigSendType" SG_ 639 ATS_RLResetReturnBtn 4;
BA_ "UserSigValidity" SG_ 639 ATS_RLResetReturnBtn 3;
BA_ "NetworkRequest" SG_ 639 ATS_RLResetReturnBtn 0;
BA_ "NetworkRequestHoldingTime" SG_ 639 ATS_RLResetReturnBtn 5000;
BA_ "Version" SG_ 639 ATS_RLResetReturnBtn "21.01.02";
BA_ "Description" SG_ 639 ATS_RRResetRestBtn "Rear Right Rest Mode Custom Initialization Button (Except North America)";
BA_ "GenSigSendType" SG_ 639 ATS_RRResetRestBtn 4;
BA_ "UserSigValidity" SG_ 639 ATS_RRResetRestBtn 3;
BA_ "NetworkRequest" SG_ 639 ATS_RRResetRestBtn 0;
BA_ "NetworkRequestHoldingTime" SG_ 639 ATS_RRResetRestBtn 5000;
BA_ "Version" SG_ 639 ATS_RRResetRestBtn "21.01.02";
BA_ "Description" SG_ 639 ATS_RRResetReturnBtn "Rear Right Return Mode Custom Initialization Button (Except North America)";
BA_ "GenSigSendType" SG_ 639 ATS_RRResetReturnBtn 4;
BA_ "UserSigValidity" SG_ 639 ATS_RRResetReturnBtn 3;
BA_ "NetworkRequest" SG_ 639 ATS_RRResetReturnBtn 0;
BA_ "NetworkRequestHoldingTime" SG_ 639 ATS_RRResetReturnBtn 5000;
BA_ "Version" SG_ 639 ATS_RRResetReturnBtn "21.01.02";
BA_ "Description" SG_ 639 ATS_RRResetAvWtcBtn "Rear Right AV Watching Mode Custom Initialization Button (Except North America)";
BA_ "GenSigSendType" SG_ 639 ATS_RRResetAvWtcBtn 4;
BA_ "UserSigValidity" SG_ 639 ATS_RRResetAvWtcBtn 3;
BA_ "NetworkRequest" SG_ 639 ATS_RRResetAvWtcBtn 0;
BA_ "NetworkRequestHoldingTime" SG_ 639 ATS_RRResetAvWtcBtn 5000;
BA_ "Version" SG_ 639 ATS_RRResetAvWtcBtn "21.01.02";
BA_ "Description" SG_ 639 ATS_RRResetReadingBtn "Rear Right Reading Mode Custom Initialization Button (Except North America)";
BA_ "GenSigSendType" SG_ 639 ATS_RRResetReadingBtn 4;
BA_ "UserSigValidity" SG_ 639 ATS_RRResetReadingBtn 3;
BA_ "NetworkRequest" SG_ 639 ATS_RRResetReadingBtn 0;
BA_ "NetworkRequestHoldingTime" SG_ 639 ATS_RRResetReadingBtn 5000;
BA_ "Version" SG_ 639 ATS_RRResetReadingBtn "21.01.02";
BA_ "Description" SG_ 639 ATS_RLSeatVentSW "ÈÄ¼® LH ½ÃÆ® ÅëÇ³ Á¶Àý";
BA_ "GenSigSendType" SG_ 639 ATS_RLSeatVentSW 4;
BA_ "UserSigValidity" SG_ 639 ATS_RLSeatVentSW 3;
BA_REL_ "GenSigTimeoutTime" BU_SG_REL_ RLHV SG_ 639 ATS_RLSeatVentSW 0;
BA_REL_ "GenSigTimeoutTime" BU_SG_REL_ SHVU_RR SG_ 639 ATS_RLSeatVentSW 0;
BA_ "NetworkRequest" SG_ 639 ATS_RLSeatVentSW 0;
BA_ "NetworkRequestHoldingTime" SG_ 639 ATS_RLSeatVentSW 5000;
BA_ "Version" SG_ 639 ATS_RLSeatVentSW "20.07.01";
BA_ "Description" SG_ 639 ATS_RRSeatHeaterUpSW "ÈÄ¼® RH ½ÃÆ® ¿­¼± Á¶Àý";
BA_ "GenSigSendType" SG_ 639 ATS_RRSeatHeaterUpSW 4;
BA_ "UserSigValidity" SG_ 639 ATS_RRSeatHeaterUpSW 3;
BA_REL_ "GenSigTimeoutTime" BU_SG_REL_ RRHV SG_ 639 ATS_RRSeatHeaterUpSW 0;
BA_REL_ "GenSigTimeoutTime" BU_SG_REL_ SHVU_RR SG_ 639 ATS_RRSeatHeaterUpSW 0;
BA_ "NetworkRequest" SG_ 639 ATS_RRSeatHeaterUpSW 0;
BA_ "NetworkRequestHoldingTime" SG_ 639 ATS_RRSeatHeaterUpSW 5000;
BA_ "Version" SG_ 639 ATS_RRSeatHeaterUpSW "20.12.04";
BA_ "GenMsgSendType" BO_ 623 0;
BA_ "Description" SG_ 623 ATS_ARSOpenCloseStatus "ÈÄ¼® ¾Ï·¹½ºÆ® ¿­¸²/´ÝÈû »óÅÂ ½ÅÈ£";
BA_ "GenSigSendType" SG_ 623 ATS_ARSOpenCloseStatus 4;
BA_ "UserSigValidity" SG_ 623 ATS_ARSOpenCloseStatus 3;
BA_ "NetworkRequest" SG_ 623 ATS_ARSOpenCloseStatus 0;
BA_ "NetworkRequestHoldingTime" SG_ 623 ATS_ARSOpenCloseStatus 5000;
BA_ "Version" SG_ 623 ATS_ARSOpenCloseStatus "20.12.05";
BA_ "Description" SG_ 623 ATS_RLLumbarDefBtn "ÈÄ¼® LH ·³¹ö ¹è±â ÀÛµ¿";
BA_ "GenSigSendType" SG_ 623 ATS_RLLumbarDefBtn 4;
BA_ "UserSigValidity" SG_ 623 ATS_RLLumbarDefBtn 3;
BA_ "NetworkRequest" SG_ 623 ATS_RLLumbarDefBtn 0;
BA_ "NetworkRequestHoldingTime" SG_ 623 ATS_RLLumbarDefBtn 5000;
BA_ "Version" SG_ 623 ATS_RLLumbarDefBtn "19.09.02";
BA_ "Description" SG_ 623 ATS_RLLumbarLowBtn "ÈÄ¼® LH ·³¹ö LOW ÀÛµ¿";
BA_ "GenSigSendType" SG_ 623 ATS_RLLumbarLowBtn 4;
BA_ "UserSigValidity" SG_ 623 ATS_RLLumbarLowBtn 3;
BA_ "NetworkRequest" SG_ 623 ATS_RLLumbarLowBtn 0;
BA_ "NetworkRequestHoldingTime" SG_ 623 ATS_RLLumbarLowBtn 5000;
BA_ "Version" SG_ 623 ATS_RLLumbarLowBtn "19.09.02";
BA_ "Description" SG_ 623 ATS_RLLumbarMidBtn "ÈÄ¼® LH ·³¹ö MID ÀÛµ¿";
BA_ "GenSigSendType" SG_ 623 ATS_RLLumbarMidBtn 4;
BA_ "UserSigValidity" SG_ 623 ATS_RLLumbarMidBtn 3;
BA_ "NetworkRequest" SG_ 623 ATS_RLLumbarMidBtn 0;
BA_ "NetworkRequestHoldingTime" SG_ 623 ATS_RLLumbarMidBtn 5000;
BA_ "Version" SG_ 623 ATS_RLLumbarMidBtn "19.09.02";
BA_ "Description" SG_ 623 ATS_RLLumbarUpBtn "ÈÄ¼® LH ·³¹ö UP ÀÛµ¿";
BA_ "GenSigSendType" SG_ 623 ATS_RLLumbarUpBtn 4;
BA_ "UserSigValidity" SG_ 623 ATS_RLLumbarUpBtn 3;
BA_ "NetworkRequest" SG_ 623 ATS_RLLumbarUpBtn 0;
BA_ "NetworkRequestHoldingTime" SG_ 623 ATS_RLLumbarUpBtn 5000;
BA_ "Version" SG_ 623 ATS_RLLumbarUpBtn "19.09.02";
BA_ "Description" SG_ 623 ATS_RLBolsterDefBtn "ÈÄ¼® LH º¼½ºÅÍ ¹è±â ÀÛµ¿";
BA_ "GenSigSendType" SG_ 623 ATS_RLBolsterDefBtn 4;
BA_ "UserSigValidity" SG_ 623 ATS_RLBolsterDefBtn 3;
BA_ "NetworkRequest" SG_ 623 ATS_RLBolsterDefBtn 0;
BA_ "NetworkRequestHoldingTime" SG_ 623 ATS_RLBolsterDefBtn 5000;
BA_ "Version" SG_ 623 ATS_RLBolsterDefBtn "19.09.02";
BA_ "Description" SG_ 623 ATS_RLBolsterInfSw "ÈÄ¼® LH º¼½ºÅÍ Èí±â ÀÛµ¿";
BA_ "GenSigSendType" SG_ 623 ATS_RLBolsterInfSw 4;
BA_ "UserSigValidity" SG_ 623 ATS_RLBolsterInfSw 3;
BA_ "NetworkRequest" SG_ 623 ATS_RLBolsterInfSw 0;
BA_ "NetworkRequestHoldingTime" SG_ 623 ATS_RLBolsterInfSw 5000;
BA_ "Version" SG_ 623 ATS_RLBolsterInfSw "19.09.02";
BA_ "Description" SG_ 623 ATS_RRLumbarDefBtn "ÈÄ¼® LH ·³¹ö ¹è±â ÀÛµ¿";
BA_ "GenSigSendType" SG_ 623 ATS_RRLumbarDefBtn 4;
BA_ "UserSigValidity" SG_ 623 ATS_RRLumbarDefBtn 3;
BA_ "NetworkRequest" SG_ 623 ATS_RRLumbarDefBtn 0;
BA_ "NetworkRequestHoldingTime" SG_ 623 ATS_RRLumbarDefBtn 5000;
BA_ "Version" SG_ 623 ATS_RRLumbarDefBtn "19.09.02";
BA_ "Description" SG_ 623 ATS_RRLumbarLowBtn "ÈÄ¼® RH ·³¹ö LOW ÀÛµ¿";
BA_ "GenSigSendType" SG_ 623 ATS_RRLumbarLowBtn 4;
BA_ "UserSigValidity" SG_ 623 ATS_RRLumbarLowBtn 3;
BA_ "NetworkRequest" SG_ 623 ATS_RRLumbarLowBtn 0;
BA_ "NetworkRequestHoldingTime" SG_ 623 ATS_RRLumbarLowBtn 5000;
BA_ "Version" SG_ 623 ATS_RRLumbarLowBtn "19.09.02";
BA_ "Description" SG_ 623 ATS_RRLumbarMidBtn "ÈÄ¼® RH ·³¹ö MID ÀÛµ¿";
BA_ "GenSigSendType" SG_ 623 ATS_RRLumbarMidBtn 4;
BA_ "UserSigValidity" SG_ 623 ATS_RRLumbarMidBtn 3;
BA_ "NetworkRequest" SG_ 623 ATS_RRLumbarMidBtn 0;
BA_ "NetworkRequestHoldingTime" SG_ 623 ATS_RRLumbarMidBtn 5000;
BA_ "Version" SG_ 623 ATS_RRLumbarMidBtn "19.09.02";
BA_ "Description" SG_ 623 ATS_RRLumbarUpBtn "ÈÄ¼® RH ·³¹ö UP ÀÛµ¿";
BA_ "GenSigSendType" SG_ 623 ATS_RRLumbarUpBtn 4;
BA_ "UserSigValidity" SG_ 623 ATS_RRLumbarUpBtn 3;
BA_ "NetworkRequest" SG_ 623 ATS_RRLumbarUpBtn 0;
BA_ "NetworkRequestHoldingTime" SG_ 623 ATS_RRLumbarUpBtn 5000;
BA_ "Version" SG_ 623 ATS_RRLumbarUpBtn "19.09.02";
BA_ "Description" SG_ 623 ATS_RRBolsterDefBtn "ÈÄ¼® RH º¼½ºÅÍ ¹è±â ÀÛµ¿";
BA_ "GenSigSendType" SG_ 623 ATS_RRBolsterDefBtn 4;
BA_ "UserSigValidity" SG_ 623 ATS_RRBolsterDefBtn 3;
BA_ "NetworkRequest" SG_ 623 ATS_RRBolsterDefBtn 0;
BA_ "NetworkRequestHoldingTime" SG_ 623 ATS_RRBolsterDefBtn 5000;
BA_ "Version" SG_ 623 ATS_RRBolsterDefBtn "19.09.02";
BA_ "Description" SG_ 623 ATS_RRBolsterInfSw "ÈÄ¼® RH º¼½ºÅÍ Èí±â ÀÛµ¿";
BA_ "GenSigSendType" SG_ 623 ATS_RRBolsterInfSw 4;
BA_ "UserSigValidity" SG_ 623 ATS_RRBolsterInfSw 3;
BA_ "NetworkRequest" SG_ 623 ATS_RRBolsterInfSw 0;
BA_ "NetworkRequestHoldingTime" SG_ 623 ATS_RRBolsterInfSw 5000;
BA_ "Version" SG_ 623 ATS_RRBolsterInfSw "19.09.02";
BA_ "GenMsgSendType" BO_ 1050 0;
BA_ "Description" SG_ 1050 BCM_Crc7Val "The data area for CRC calculation is based on the data length (DLC) of the message DB.

The CRC shall be calculated over the entire data block (excluding the CRC bytes) including the user data, alive counter and Data ID 

 

- CRC Polynomial (0x1D) , Initial Value : 0x00, XOR value : 0xFF, Data ID Mode : Both, Data ID : Message ID + 0xF800 

- The initial value is for CRC calculation and the message should be sent with the calculated result value. 

The mathematical expression to 8 bit CRC polynomial is given here. G(x) = x8 + x4 + x3 + x2 + 1";
BA_ "GenSigSendType" SG_ 1050 BCM_Crc7Val 4;
BA_ "GenSigStartValue" SG_ 1050 BCM_Crc7Val 255;
BA_ "UserSigValidity" SG_ 1050 BCM_Crc7Val 0;
BA_ "Version" SG_ 1050 BCM_Crc7Val "18.11.08";
BA_ "Description" SG_ 1050 BCM_AlvCnt7Val "For the first transmission request for a data element the counter shall be initialized with 0 and shall be incremented by 1

for every subsequent send request. When the counter reaches the maximum value(0xE), then it shall restart with 0 for the next send request";
BA_ "GenSigSendType" SG_ 1050 BCM_AlvCnt7Val 4;
BA_ "UserSigValidity" SG_ 1050 BCM_AlvCnt7Val 0;
BA_ "Version" SG_ 1050 BCM_AlvCnt7Val "18.11.08";
BA_ "Description" SG_ 1050 Lamp_HiPrioHzrdReq "-Higher priority than SJB hazard

-Diag/Arm/DisArm/Balarm/Panic/MTS

-Initial Value: 2";
BA_ "GenSigSendType" SG_ 1050 Lamp_HiPrioHzrdReq 4;
BA_ "GenSigStartValue" SG_ 1050 Lamp_HiPrioHzrdReq 2;
BA_ "UserSigValidity" SG_ 1050 Lamp_HiPrioHzrdReq 0;
BA_ "NetworkRequest" SG_ 1050 Lamp_HiPrioHzrdReq 0;
BA_ "NetworkRequestHoldingTime" SG_ 1050 Lamp_HiPrioHzrdReq 5000;
BA_ "Version" SG_ 1050 Lamp_HiPrioHzrdReq "17.12.00";
BA_ "Description" SG_ 1050 Lamp_LoPrioHzrdReq "-Lower priority than SJB hazard

-TrunkOpenClose/CrashUnlock/RemoteStart

-Initial Value: 2";
BA_ "GenSigSendType" SG_ 1050 Lamp_LoPrioHzrdReq 4;
BA_ "GenSigStartValue" SG_ 1050 Lamp_LoPrioHzrdReq 2;
BA_ "UserSigValidity" SG_ 1050 Lamp_LoPrioHzrdReq 0;
BA_ "NetworkRequest" SG_ 1050 Lamp_LoPrioHzrdReq 0;
BA_ "NetworkRequestHoldingTime" SG_ 1050 Lamp_LoPrioHzrdReq 5000;
BA_ "Version" SG_ 1050 Lamp_LoPrioHzrdReq "17.12.00";
BA_ "Description" SG_ 1050 Lamp_IntTailLmpOnReq "-(Old)C_INTTailOn";
BA_ "GenSigSendType" SG_ 1050 Lamp_IntTailLmpOnReq 4;
BA_ "UserSigValidity" SG_ 1050 Lamp_IntTailLmpOnReq 0;
BA_REL_ "GenSigTimeoutTime" BU_SG_REL_ FCS SG_ 1050 Lamp_IntTailLmpOnReq 1500;
BA_REL_ "GenSigTimeoutTime" BU_SG_REL_ WPC SG_ 1050 Lamp_IntTailLmpOnReq 1500;
BA_REL_ "GenSigTimeoutTime" BU_SG_REL_ RWPC SG_ 1050 Lamp_IntTailLmpOnReq 1500;
BA_REL_ "GenSigTimeoutTime" BU_SG_REL_ APSU SG_ 1050 Lamp_IntTailLmpOnReq 1500;
BA_REL_ "GenSigTimeoutTime" BU_SG_REL_ RLHV SG_ 1050 Lamp_IntTailLmpOnReq 1500;
BA_REL_ "GenSigTimeoutTime" BU_SG_REL_ RRHV SG_ 1050 Lamp_IntTailLmpOnReq 1500;
BA_REL_ "GenSigTimeoutTime" BU_SG_REL_ SHVU_FR SG_ 1050 Lamp_IntTailLmpOnReq 1500;
BA_REL_ "GenSigTimeoutTime" BU_SG_REL_ SHVU_RR SG_ 1050 Lamp_IntTailLmpOnReq 1500;
BA_REL_ "GenSigTimeoutTime" BU_SG_REL_ DPSU SG_ 1050 Lamp_IntTailLmpOnReq 1500;
BA_REL_ "GenSigTimeoutTime" BU_SG_REL_ WPC2 SG_ 1050 Lamp_IntTailLmpOnReq 1500;
BA_ "NetworkRequest" SG_ 1050 Lamp_IntTailLmpOnReq 0;
BA_ "NetworkRequestHoldingTime" SG_ 1050 Lamp_IntTailLmpOnReq 5000;
BA_ "Version" SG_ 1050 Lamp_IntTailLmpOnReq "17.12.00";
BA_ "Description" SG_ 1050 Lamp_ExtrnlTailLmpOnReq "-(Old)C_EXTTailOn";
BA_ "GenSigSendType" SG_ 1050 Lamp_ExtrnlTailLmpOnReq 4;
BA_ "UserSigValidity" SG_ 1050 Lamp_ExtrnlTailLmpOnReq 0;
BA_REL_ "GenSigTimeoutTime" BU_SG_REL_ BLTN_CAM SG_ 1050 Lamp_ExtrnlTailLmpOnReq 1500;
BA_ "NetworkRequest" SG_ 1050 Lamp_ExtrnlTailLmpOnReq 0;
BA_ "NetworkRequestHoldingTime" SG_ 1050 Lamp_ExtrnlTailLmpOnReq 5000;
BA_ "Version" SG_ 1050 Lamp_ExtrnlTailLmpOnReq "17.12.00";
BA_ "Description" SG_ 1050 Lamp_HdLmpLoOnReq "-(Old)C_HLampLowON";
BA_ "GenSigSendType" SG_ 1050 Lamp_HdLmpLoOnReq 4;
BA_ "UserSigValidity" SG_ 1050 Lamp_HdLmpLoOnReq 0;
BA_ "NetworkRequest" SG_ 1050 Lamp_HdLmpLoOnReq 0;
BA_ "NetworkRequestHoldingTime" SG_ 1050 Lamp_HdLmpLoOnReq 5000;
BA_ "Version" SG_ 1050 Lamp_HdLmpLoOnReq "17.12.00";
BA_ "Description" SG_ 1050 Lamp_HdLmpHiOnReq "-(Old)C_HLampHighON";
BA_ "GenSigSendType" SG_ 1050 Lamp_HdLmpHiOnReq 4;
BA_ "UserSigValidity" SG_ 1050 Lamp_HdLmpHiOnReq 0;
BA_ "NetworkRequest" SG_ 1050 Lamp_HdLmpHiOnReq 0;
BA_ "NetworkRequestHoldingTime" SG_ 1050 Lamp_HdLmpHiOnReq 5000;
BA_ "Version" SG_ 1050 Lamp_HdLmpHiOnReq "17.12.00";
BA_ "Description" SG_ 1050 Lamp_AvTailLmpSta "-Send with at the same time with C_IntTailOn

-Initiail Value: 1";
BA_ "GenSigSendType" SG_ 1050 Lamp_AvTailLmpSta 4;
BA_ "GenSigStartValue" SG_ 1050 Lamp_AvTailLmpSta 1;
BA_ "UserSigValidity" SG_ 1050 Lamp_AvTailLmpSta 0;
BA_REL_ "GenSigTimeoutTime" BU_SG_REL_ SWRC SG_ 1050 Lamp_AvTailLmpSta 1500;
BA_REL_ "GenSigTimeoutTime" BU_SG_REL_ APSU SG_ 1050 Lamp_AvTailLmpSta 1500;
BA_REL_ "GenSigTimeoutTime" BU_SG_REL_ ATS SG_ 1050 Lamp_AvTailLmpSta 1500;
BA_ "NetworkRequest" SG_ 1050 Lamp_AvTailLmpSta 0;
BA_ "NetworkRequestHoldingTime" SG_ 1050 Lamp_AvTailLmpSta 5000;
BA_ "Version" SG_ 1050 Lamp_AvTailLmpSta "17.12.00";
BA_ "Description" SG_ 1050 Lamp_BckUpLmpCmd "BackUp Lamp On/Off Command";
BA_ "GenSigSendType" SG_ 1050 Lamp_BckUpLmpCmd 4;
BA_ "UserSigValidity" SG_ 1050 Lamp_BckUpLmpCmd 0;
BA_ "NetworkRequest" SG_ 1050 Lamp_BckUpLmpCmd 0;
BA_ "NetworkRequestHoldingTime" SG_ 1050 Lamp_BckUpLmpCmd 5000;
BA_ "Version" SG_ 1050 Lamp_BckUpLmpCmd "20.08.02";
BA_ "Description" SG_ 1050 Lamp_DrlOnReq "Lamp on command for DRL";
BA_ "GenSigSendType" SG_ 1050 Lamp_DrlOnReq 4;
BA_ "UserSigValidity" SG_ 1050 Lamp_DrlOnReq 0;
BA_ "NetworkRequest" SG_ 1050 Lamp_DrlOnReq 0;
BA_ "NetworkRequestHoldingTime" SG_ 1050 Lamp_DrlOnReq 5000;
BA_ "Version" SG_ 1050 Lamp_DrlOnReq "20.09.00";
BA_ "GenMsgSendType" BO_ 1052 0;
BA_ "Description" SG_ 1052 BCM_Crc9Val "The data area for CRC calculation is based on the data length (DLC) of the message DB.

The CRC shall be calculated over the entire data block (excluding the CRC bytes) including the user data, alive counter and Data ID 

 

- CRC Polynomial (0x1D) , Initial Value : 0x00, XOR value : 0xFF, Data ID Mode : Both, Data ID : Message ID + 0xF800 

- The initial value is for CRC calculation and the message should be sent with the calculated result value. 

The mathematical expression to 8 bit CRC polynomial is given here. G(x) = x8 + x4 + x3 + x2 + 1";
BA_ "GenSigSendType" SG_ 1052 BCM_Crc9Val 4;
BA_ "GenSigStartValue" SG_ 1052 BCM_Crc9Val 255;
BA_ "UserSigValidity" SG_ 1052 BCM_Crc9Val 0;
BA_ "Version" SG_ 1052 BCM_Crc9Val "18.11.08";
BA_ "Description" SG_ 1052 BCM_AlvCnt9Val "For the first transmission request for a data element the counter shall be initialized with 0 and shall be incremented by 1

for every subsequent send request. When the counter reaches the maximum value(0xE), then it shall restart with 0 for the next send request";
BA_ "GenSigSendType" SG_ 1052 BCM_AlvCnt9Val 4;
BA_ "UserSigValidity" SG_ 1052 BCM_AlvCnt9Val 0;
BA_ "Version" SG_ 1052 BCM_AlvCnt9Val "18.11.08";
BA_ "Description" SG_ 1052 Lamp_AutoLtSnsrNightSta "This signal indicates autolight sensor output";
BA_ "GenSigSendType" SG_ 1052 Lamp_AutoLtSnsrNightSta 4;
BA_ "GenSigStartValue" SG_ 1052 Lamp_AutoLtSnsrNightSta 1;
BA_ "UserSigValidity" SG_ 1052 Lamp_AutoLtSnsrNightSta 0;
BA_REL_ "GenSigTimeoutTime" BU_SG_REL_ SWRC SG_ 1052 Lamp_AutoLtSnsrNightSta 1500;
BA_REL_ "GenSigTimeoutTime" BU_SG_REL_ APSU SG_ 1052 Lamp_AutoLtSnsrNightSta 1500;
BA_REL_ "GenSigTimeoutTime" BU_SG_REL_ ATS SG_ 1052 Lamp_AutoLtSnsrNightSta 1500;
BA_ "NetworkRequest" SG_ 1052 Lamp_AutoLtSnsrNightSta 0;
BA_ "NetworkRequestHoldingTime" SG_ 1052 Lamp_AutoLtSnsrNightSta 5000;
BA_ "Version" SG_ 1052 Lamp_AutoLtSnsrNightSta "20.04.06";
BA_ "Description" SG_ 1052 Lamp_VendorInfo "Rain seosor Vendor info (LIN to CAN signal)

- 001 : TRW(BCS)

- 010 : HELLA";
BA_ "GenSigSendType" SG_ 1052 Lamp_VendorInfo 4;
BA_ "GenSigStartValue" SG_ 1052 Lamp_VendorInfo 7;
BA_ "UserSigValidity" SG_ 1052 Lamp_VendorInfo 0;
BA_ "NetworkRequest" SG_ 1052 Lamp_VendorInfo 0;
BA_ "NetworkRequestHoldingTime" SG_ 1052 Lamp_VendorInfo 5000;
BA_ "Version" SG_ 1052 Lamp_VendorInfo "20.05.03";
BA_ "Description" SG_ 1052 Lamp_AutoLtSnsrHorVal "This signal indicates autolight sensor output (for HUD)";
BA_ "GenSigSendType" SG_ 1052 Lamp_AutoLtSnsrHorVal 4;
BA_ "UserSigValidity" SG_ 1052 Lamp_AutoLtSnsrHorVal 0;
BA_REL_ "GenSigTimeoutTime" BU_SG_REL_ ATS SG_ 1052 Lamp_AutoLtSnsrHorVal 1500;
BA_ "NetworkRequest" SG_ 1052 Lamp_AutoLtSnsrHorVal 0;
BA_ "NetworkRequestHoldingTime" SG_ 1052 Lamp_AutoLtSnsrHorVal 5000;
BA_ "Version" SG_ 1052 Lamp_AutoLtSnsrHorVal "21.07.05";
BA_ "Description" SG_ 1052 IBU_HDPSpprtSWVer "This signal indicates HDP-IBU requirement version";
BA_ "GenSigSendType" SG_ 1052 IBU_HDPSpprtSWVer 4;
BA_ "UserSigValidity" SG_ 1052 IBU_HDPSpprtSWVer 0;
BA_ "NetworkRequest" SG_ 1052 IBU_HDPSpprtSWVer 0;
BA_ "NetworkRequestHoldingTime" SG_ 1052 IBU_HDPSpprtSWVer 5000;
BA_ "Version" SG_ 1052 IBU_HDPSpprtSWVer "21.10.04";
BA_ "Description" SG_ 1052 Wiper_RainAmount "Amount of rain on windshield (LIN to CAN Signal)

- LIN Signal Name : VAL_RAIN_AMOUNT

- 0~150 : PH=0.5*HEX%

- 151~254 : Reserved

- 255 (1111 1111) : Invalid";
BA_ "GenSigSendType" SG_ 1052 Wiper_RainAmount 4;
BA_ "GenSigStartValue" SG_ 1052 Wiper_RainAmount 255;
BA_ "UserSigValidity" SG_ 1052 Wiper_RainAmount 0;
BA_ "NetworkRequest" SG_ 1052 Wiper_RainAmount 0;
BA_ "NetworkRequestHoldingTime" SG_ 1052 Wiper_RainAmount 5000;
BA_ "Version" SG_ 1052 Wiper_RainAmount "21.07.05";
BA_ "GenMsgCycleTime" BO_ 1584 0;
BA_ "Description" SG_ 1584 AMP_NaviWarnSound "Navi Warning prompt on/off

Only ON during the Navi Warning Sound Playing

Default : Off

-This Signal's Feedback is AMP_NaviWarnModeState@AMP";
BA_ "GenSigSendType" SG_ 1584 AMP_NaviWarnSound 4;
BA_ "GenSigStartValue" SG_ 1584 AMP_NaviWarnSound 3;
BA_ "UserSigValidity" SG_ 1584 AMP_NaviWarnSound 1;
BA_ "Version" SG_ 1584 AMP_NaviWarnSound "21.04.10";
BA_ "Description" SG_ 1584 AMP_Beep1Mode "16.02.05_[Default Value]

0x0";
BA_ "GenSigSendType" SG_ 1584 AMP_Beep1Mode 4;
BA_ "GenSigStartValue" SG_ 1584 AMP_Beep1Mode 3;
BA_ "UserSigValidity" SG_ 1584 AMP_Beep1Mode 1;
BA_REL_ "GenSigTimeoutTime" BU_SG_REL_ ATS SG_ 1584 AMP_Beep1Mode 0;
BA_ "NetworkRequest" SG_ 1584 AMP_Beep1Mode 0;
BA_ "Version" SG_ 1584 AMP_Beep1Mode "18.12.06";
BA_ "Description" SG_ 1584 AMP_MasterBeepVolumeStep "MasterBeepVolumeStep (0/1/2/3/4/5)";
BA_ "GenSigSendType" SG_ 1584 AMP_MasterBeepVolumeStep 4;
BA_ "GenSigStartValue" SG_ 1584 AMP_MasterBeepVolumeStep 7;
BA_ "UserSigValidity" SG_ 1584 AMP_MasterBeepVolumeStep 1;
BA_ "NetworkRequest" SG_ 1584 AMP_MasterBeepVolumeStep 0;
BA_ "Version" SG_ 1584 AMP_MasterBeepVolumeStep "20.08.02";
BA_ "Description" SG_ 1584 AMP_SignalDoctor "16.02.05_[Default Value]

0x1";
BA_ "GenSigSendType" SG_ 1584 AMP_SignalDoctor 4;
BA_ "GenSigStartValue" SG_ 1584 AMP_SignalDoctor 3;
BA_ "UserSigValidity" SG_ 1584 AMP_SignalDoctor 1;
BA_ "Version" SG_ 1584 AMP_SignalDoctor "18.12.06";
BA_ "Description" SG_ 1584 AMP_RrTTSSound "This signal is  Rear TTS output state information";
BA_ "GenSigSendType" SG_ 1584 AMP_RrTTSSound 4;
BA_ "GenSigStartValue" SG_ 1584 AMP_RrTTSSound 3;
BA_ "UserSigValidity" SG_ 1584 AMP_RrTTSSound 1;
BA_ "Version" SG_ 1584 AMP_RrTTSSound "19.12.01";
BA_ "Description" SG_ 1584 AMP_ASDMode "16.04.01_HI : default value 0x01

DH PE : default value 0x03 (this signal used for DH PE eng mode asd setting)";
BA_ "GenSigSendType" SG_ 1584 AMP_ASDMode 4;
BA_ "GenSigStartValue" SG_ 1584 AMP_ASDMode 7;
BA_ "UserSigValidity" SG_ 1584 AMP_ASDMode 1;
BA_ "NetworkRequest" SG_ 1584 AMP_ASDMode 0;
BA_ "Version" SG_ 1584 AMP_ASDMode "18.12.06";
BA_ "Description" SG_ 1584 AMP_ANCMode "18.03.08_";
BA_ "GenSigSendType" SG_ 1584 AMP_ANCMode 4;
BA_ "GenSigStartValue" SG_ 1584 AMP_ANCMode 3;
BA_ "UserSigValidity" SG_ 1584 AMP_ANCMode 1;
BA_ "Version" SG_ 1584 AMP_ANCMode "18.12.06";
BA_ "Description" SG_ 1584 AMP_VirtualVenueMode "Select VV mode";
BA_ "GenSigSendType" SG_ 1584 AMP_VirtualVenueMode 4;
BA_ "GenSigStartValue" SG_ 1584 AMP_VirtualVenueMode 7;
BA_ "UserSigValidity" SG_ 1584 AMP_VirtualVenueMode 1;
BA_ "NetworkRequest" SG_ 1584 AMP_VirtualVenueMode 0;
BA_ "Version" SG_ 1584 AMP_VirtualVenueMode "19.08.08";
BA_ "Description" SG_ 1584 AMP_QLIMode "Select QLI mode";
BA_ "GenSigSendType" SG_ 1584 AMP_QLIMode 4;
BA_ "GenSigStartValue" SG_ 1584 AMP_QLIMode 7;
BA_ "UserSigValidity" SG_ 1584 AMP_QLIMode 1;
BA_ "NetworkRequest" SG_ 1584 AMP_QLIMode 0;
BA_ "Version" SG_ 1584 AMP_QLIMode "19.08.08";
BA_ "Description" SG_ 1584 AMP_DriverMode "Turn On/Off Driver mode";
BA_ "GenSigSendType" SG_ 1584 AMP_DriverMode 4;
BA_ "GenSigStartValue" SG_ 1584 AMP_DriverMode 3;
BA_ "UserSigValidity" SG_ 1584 AMP_DriverMode 1;
BA_ "NetworkRequest" SG_ 1584 AMP_DriverMode 0;
BA_ "Version" SG_ 1584 AMP_DriverMode "19.08.08";
BA_ "Description" SG_ 1584 AMP_NaviSound "16.02.05_[Default Value]

0x0";
BA_ "GenSigSendType" SG_ 1584 AMP_NaviSound 4;
BA_ "GenSigStartValue" SG_ 1584 AMP_NaviSound 3;
BA_ "UserSigValidity" SG_ 1584 AMP_NaviSound 1;
BA_ "Version" SG_ 1584 AMP_NaviSound "19.01.05";
BA_ "Description" SG_ 1584 AMP_VoiceGuideTTS "Play VoiceGuide TTS";
BA_ "GenSigSendType" SG_ 1584 AMP_VoiceGuideTTS 4;
BA_ "GenSigStartValue" SG_ 1584 AMP_VoiceGuideTTS 3;
BA_ "UserSigValidity" SG_ 1584 AMP_VoiceGuideTTS 1;
BA_ "NetworkRequest" SG_ 1584 AMP_VoiceGuideTTS 0;
BA_ "Version" SG_ 1584 AMP_VoiceGuideTTS "19.08.08";
BA_ "Description" SG_ 1584 AMP_Beep1KBDMode "Play touch beep sound at keyboard screen on AVN

This Signal's Feedback is AMP_Beep1KBDModeState@AMP";
BA_ "GenSigSendType" SG_ 1584 AMP_Beep1KBDMode 4;
BA_ "GenSigStartValue" SG_ 1584 AMP_Beep1KBDMode 3;
BA_ "UserSigValidity" SG_ 1584 AMP_Beep1KBDMode 1;
BA_ "Version" SG_ 1584 AMP_Beep1KBDMode "20.06.01";
BA_ "Description" SG_ 1584 AMP_NaviWarnVolumeStep "- Command for Navigation Warning Prompt Volume Setting

- This Signal's Feedback is AMP_NaviWarnVolumeState@AMP";
BA_ "GenSigSendType" SG_ 1584 AMP_NaviWarnVolumeStep 4;
BA_ "GenSigStartValue" SG_ 1584 AMP_NaviWarnVolumeStep 255;
BA_ "UserSigValidity" SG_ 1584 AMP_NaviWarnVolumeStep 1;
BA_ "Version" SG_ 1584 AMP_NaviWarnVolumeStep "21.04.10";
BA_ "Description" SG_ 1584 AMP_TTSSound "This signal is  TTS output state information";
BA_ "GenSigSendType" SG_ 1584 AMP_TTSSound 4;
BA_ "GenSigStartValue" SG_ 1584 AMP_TTSSound 3;
BA_ "UserSigValidity" SG_ 1584 AMP_TTSSound 1;
BA_ "Version" SG_ 1584 AMP_TTSSound "19.07.06";
BA_ "Description" SG_ 1584 AMP_SDVCStep "16.02.05_";
BA_ "GenSigSendType" SG_ 1584 AMP_SDVCStep 4;
BA_ "UserSigValidity" SG_ 1584 AMP_SDVCStep 1;
BA_ "NetworkRequest" SG_ 1584 AMP_SDVCStep 0;
BA_ "Version" SG_ 1584 AMP_SDVCStep "18.12.06";
BA_ "GenMsgSendType" BO_ 577 0;
BA_ "GenSigSendType" SG_ 577 C_AstBolsterInfSw_HU 4;
BA_ "UserSigValidity" SG_ 577 C_AstBolsterInfSw_HU 0;
BA_REL_ "GenSigTimeoutTime" BU_SG_REL_ ASAU SG_ 577 C_AstBolsterInfSw_HU 1500;
BA_REL_ "GenSigTimeoutTime" BU_SG_REL_ ALBCU SG_ 577 C_AstBolsterInfSw_HU 1500;
BA_ "Version" SG_ 577 C_AstBolsterInfSw_HU "19.11.09";
BA_ "GenSigSendType" SG_ 577 C_RLHrestUpSw_HU 4;
BA_ "UserSigValidity" SG_ 577 C_RLHrestUpSw_HU 0;
BA_REL_ "GenSigTimeoutTime" BU_SG_REL_ APSU SG_ 577 C_RLHrestUpSw_HU 1500;
BA_REL_ "GenSigTimeoutTime" BU_SG_REL_ RRPSU SG_ 577 C_RLHrestUpSw_HU 1500;
BA_REL_ "GenSigTimeoutTime" BU_SG_REL_ RLPSU SG_ 577 C_RLHrestUpSw_HU 1500;
BA_ "Version" SG_ 577 C_RLHrestUpSw_HU "19.11.09";
BA_ "GenSigSendType" SG_ 577 C_RLHrestDnSw_HU 4;
BA_ "UserSigValidity" SG_ 577 C_RLHrestDnSw_HU 0;
BA_REL_ "GenSigTimeoutTime" BU_SG_REL_ APSU SG_ 577 C_RLHrestDnSw_HU 1500;
BA_REL_ "GenSigTimeoutTime" BU_SG_REL_ RRPSU SG_ 577 C_RLHrestDnSw_HU 1500;
BA_REL_ "GenSigTimeoutTime" BU_SG_REL_ RLPSU SG_ 577 C_RLHrestDnSw_HU 1500;
BA_ "Version" SG_ 577 C_RLHrestDnSw_HU "19.11.09";
BA_ "GenSigSendType" SG_ 577 C_RLHrestFwdSw_HU 4;
BA_ "UserSigValidity" SG_ 577 C_RLHrestFwdSw_HU 0;
BA_REL_ "GenSigTimeoutTime" BU_SG_REL_ APSU SG_ 577 C_RLHrestFwdSw_HU 1500;
BA_REL_ "GenSigTimeoutTime" BU_SG_REL_ RRPSU SG_ 577 C_RLHrestFwdSw_HU 1500;
BA_REL_ "GenSigTimeoutTime" BU_SG_REL_ RLPSU SG_ 577 C_RLHrestFwdSw_HU 1500;
BA_ "Version" SG_ 577 C_RLHrestFwdSw_HU "19.11.09";
BA_ "GenSigSendType" SG_ 577 C_AstBolsterDefSw_HU 4;
BA_ "UserSigValidity" SG_ 577 C_AstBolsterDefSw_HU 0;
BA_REL_ "GenSigTimeoutTime" BU_SG_REL_ ASAU SG_ 577 C_AstBolsterDefSw_HU 1500;
BA_REL_ "GenSigTimeoutTime" BU_SG_REL_ ALBCU SG_ 577 C_AstBolsterDefSw_HU 1500;
BA_ "Version" SG_ 577 C_AstBolsterDefSw_HU "19.11.09";
BA_ "GenSigSendType" SG_ 577 C_RLHrestBwdSw_HU 4;
BA_ "UserSigValidity" SG_ 577 C_RLHrestBwdSw_HU 0;
BA_REL_ "GenSigTimeoutTime" BU_SG_REL_ APSU SG_ 577 C_RLHrestBwdSw_HU 1500;
BA_REL_ "GenSigTimeoutTime" BU_SG_REL_ RRPSU SG_ 577 C_RLHrestBwdSw_HU 1500;
BA_REL_ "GenSigTimeoutTime" BU_SG_REL_ RLPSU SG_ 577 C_RLHrestBwdSw_HU 1500;
BA_ "Version" SG_ 577 C_RLHrestBwdSw_HU "19.11.09";
BA_ "GenSigSendType" SG_ 577 C_RLLumbarUpSw_HU 4;
BA_ "UserSigValidity" SG_ 577 C_RLLumbarUpSw_HU 0;
BA_REL_ "GenSigTimeoutTime" BU_SG_REL_ RLPSU SG_ 577 C_RLLumbarUpSw_HU 1500;
BA_ "Version" SG_ 577 C_RLLumbarUpSw_HU "19.11.09";
BA_ "GenSigSendType" SG_ 577 C_RLLumbarMidSw_HU 4;
BA_ "UserSigValidity" SG_ 577 C_RLLumbarMidSw_HU 0;
BA_REL_ "GenSigTimeoutTime" BU_SG_REL_ RLPSU SG_ 577 C_RLLumbarMidSw_HU 1500;
BA_ "Version" SG_ 577 C_RLLumbarMidSw_HU "19.11.09";
BA_ "GenSigSendType" SG_ 577 C_RLLumbarLowSw_HU 4;
BA_ "UserSigValidity" SG_ 577 C_RLLumbarLowSw_HU 0;
BA_REL_ "GenSigTimeoutTime" BU_SG_REL_ RLPSU SG_ 577 C_RLLumbarLowSw_HU 1500;
BA_ "Version" SG_ 577 C_RLLumbarLowSw_HU "19.11.09";
BA_ "GenSigSendType" SG_ 577 C_RLLumbarDefSw_HU 4;
BA_ "UserSigValidity" SG_ 577 C_RLLumbarDefSw_HU 0;
BA_REL_ "GenSigTimeoutTime" BU_SG_REL_ RLPSU SG_ 577 C_RLLumbarDefSw_HU 1500;
BA_ "Version" SG_ 577 C_RLLumbarDefSw_HU "19.11.09";
BA_ "GenSigSendType" SG_ 577 C_RLBolsterInfSw_HU 4;
BA_ "UserSigValidity" SG_ 577 C_RLBolsterInfSw_HU 0;
BA_REL_ "GenSigTimeoutTime" BU_SG_REL_ RLPSU SG_ 577 C_RLBolsterInfSw_HU 1500;
BA_ "Version" SG_ 577 C_RLBolsterInfSw_HU "19.11.09";
BA_ "GenSigSendType" SG_ 577 C_RLBolsterDefSw_HU 4;
BA_ "UserSigValidity" SG_ 577 C_RLBolsterDefSw_HU 0;
BA_REL_ "GenSigTimeoutTime" BU_SG_REL_ RLPSU SG_ 577 C_RLBolsterDefSw_HU 1500;
BA_ "Version" SG_ 577 C_RLBolsterDefSw_HU "19.11.09";
BA_ "GenSigSendType" SG_ 577 C_AstHrestUpSw_HU 4;
BA_ "UserSigValidity" SG_ 577 C_AstHrestUpSw_HU 0;
BA_REL_ "GenSigTimeoutTime" BU_SG_REL_ APSU SG_ 577 C_AstHrestUpSw_HU 1500;
BA_ "Version" SG_ 577 C_AstHrestUpSw_HU "19.11.09";
BA_ "GenSigSendType" SG_ 577 C_AstHrestDnSw_HU 4;
BA_ "UserSigValidity" SG_ 577 C_AstHrestDnSw_HU 0;
BA_REL_ "GenSigTimeoutTime" BU_SG_REL_ APSU SG_ 577 C_AstHrestDnSw_HU 1500;
BA_ "Version" SG_ 577 C_AstHrestDnSw_HU "19.11.09";
BA_ "GenSigSendType" SG_ 577 C_AstFootrestFldSw_HU 4;
BA_ "UserSigValidity" SG_ 577 C_AstFootrestFldSw_HU 0;
BA_REL_ "GenSigTimeoutTime" BU_SG_REL_ APSU SG_ 577 C_AstFootrestFldSw_HU 1500;
BA_ "Version" SG_ 577 C_AstFootrestFldSw_HU "19.11.09";
BA_ "GenSigSendType" SG_ 577 C_AstHrestFwdSw_HU 4;
BA_ "UserSigValidity" SG_ 577 C_AstHrestFwdSw_HU 0;
BA_REL_ "GenSigTimeoutTime" BU_SG_REL_ APSU SG_ 577 C_AstHrestFwdSw_HU 1500;
BA_ "Version" SG_ 577 C_AstHrestFwdSw_HU "19.11.09";
BA_ "GenSigSendType" SG_ 577 C_AstHrestBwdSw_HU 4;
BA_ "UserSigValidity" SG_ 577 C_AstHrestBwdSw_HU 0;
BA_REL_ "GenSigTimeoutTime" BU_SG_REL_ APSU SG_ 577 C_AstHrestBwdSw_HU 1500;
BA_ "Version" SG_ 577 C_AstHrestBwdSw_HU "19.11.09";
BA_ "GenSigSendType" SG_ 577 C_AstFootrestUnFldSw_HU 4;
BA_ "UserSigValidity" SG_ 577 C_AstFootrestUnFldSw_HU 0;
BA_REL_ "GenSigTimeoutTime" BU_SG_REL_ APSU SG_ 577 C_AstFootrestUnFldSw_HU 1500;
BA_ "Version" SG_ 577 C_AstFootrestUnFldSw_HU "19.11.09";
BA_ "GenMsgSendType" BO_ 578 0;
BA_ "GenSigSendType" SG_ 578 C_RRLegSupFwdSw_HU 4;
BA_ "UserSigValidity" SG_ 578 C_RRLegSupFwdSw_HU 0;
BA_REL_ "GenSigTimeoutTime" BU_SG_REL_ APSU SG_ 578 C_RRLegSupFwdSw_HU 1500;
BA_REL_ "GenSigTimeoutTime" BU_SG_REL_ RRPSU SG_ 578 C_RRLegSupFwdSw_HU 1500;
BA_REL_ "GenSigTimeoutTime" BU_SG_REL_ RLPSU SG_ 578 C_RRLegSupFwdSw_HU 1500;
BA_ "Version" SG_ 578 C_RRLegSupFwdSw_HU "19.11.09";
BA_ "GenSigSendType" SG_ 578 C_RRHrestDnSw_HU 4;
BA_ "UserSigValidity" SG_ 578 C_RRHrestDnSw_HU 0;
BA_REL_ "GenSigTimeoutTime" BU_SG_REL_ APSU SG_ 578 C_RRHrestDnSw_HU 1500;
BA_REL_ "GenSigTimeoutTime" BU_SG_REL_ RRPSU SG_ 578 C_RRHrestDnSw_HU 1500;
BA_REL_ "GenSigTimeoutTime" BU_SG_REL_ RLPSU SG_ 578 C_RRHrestDnSw_HU 1500;
BA_ "Version" SG_ 578 C_RRHrestDnSw_HU "19.11.09";
BA_ "GenSigSendType" SG_ 578 C_RRHrestFwdSw_HU 4;
BA_ "UserSigValidity" SG_ 578 C_RRHrestFwdSw_HU 0;
BA_REL_ "GenSigTimeoutTime" BU_SG_REL_ APSU SG_ 578 C_RRHrestFwdSw_HU 1500;
BA_REL_ "GenSigTimeoutTime" BU_SG_REL_ RRPSU SG_ 578 C_RRHrestFwdSw_HU 1500;
BA_REL_ "GenSigTimeoutTime" BU_SG_REL_ RLPSU SG_ 578 C_RRHrestFwdSw_HU 1500;
BA_ "Version" SG_ 578 C_RRHrestFwdSw_HU "19.11.09";
BA_ "GenSigSendType" SG_ 578 C_RRHrestBwdSw_HU 4;
BA_ "UserSigValidity" SG_ 578 C_RRHrestBwdSw_HU 0;
BA_REL_ "GenSigTimeoutTime" BU_SG_REL_ APSU SG_ 578 C_RRHrestBwdSw_HU 1500;
BA_REL_ "GenSigTimeoutTime" BU_SG_REL_ RRPSU SG_ 578 C_RRHrestBwdSw_HU 1500;
BA_REL_ "GenSigTimeoutTime" BU_SG_REL_ RLPSU SG_ 578 C_RRHrestBwdSw_HU 1500;
BA_ "Version" SG_ 578 C_RRHrestBwdSw_HU "19.11.09";
BA_ "GenSigSendType" SG_ 578 C_RRLumbarUpSw_HU 4;
BA_ "UserSigValidity" SG_ 578 C_RRLumbarUpSw_HU 0;
BA_REL_ "GenSigTimeoutTime" BU_SG_REL_ APSU SG_ 578 C_RRLumbarUpSw_HU 1500;
BA_REL_ "GenSigTimeoutTime" BU_SG_REL_ RRPSU SG_ 578 C_RRLumbarUpSw_HU 1500;
BA_ "Version" SG_ 578 C_RRLumbarUpSw_HU "19.11.09";
BA_ "GenSigSendType" SG_ 578 C_RRLumbarMidSw_HU 4;
BA_ "UserSigValidity" SG_ 578 C_RRLumbarMidSw_HU 0;
BA_REL_ "GenSigTimeoutTime" BU_SG_REL_ APSU SG_ 578 C_RRLumbarMidSw_HU 1500;
BA_REL_ "GenSigTimeoutTime" BU_SG_REL_ RRPSU SG_ 578 C_RRLumbarMidSw_HU 1500;
BA_ "Version" SG_ 578 C_RRLumbarMidSw_HU "19.11.09";
BA_ "GenSigSendType" SG_ 578 C_RRLegSupBwdSw_HU 4;
BA_ "UserSigValidity" SG_ 578 C_RRLegSupBwdSw_HU 0;
BA_REL_ "GenSigTimeoutTime" BU_SG_REL_ APSU SG_ 578 C_RRLegSupBwdSw_HU 1500;
BA_REL_ "GenSigTimeoutTime" BU_SG_REL_ RRPSU SG_ 578 C_RRLegSupBwdSw_HU 1500;
BA_REL_ "GenSigTimeoutTime" BU_SG_REL_ RLPSU SG_ 578 C_RRLegSupBwdSw_HU 1500;
BA_ "Version" SG_ 578 C_RRLegSupBwdSw_HU "19.11.09";
BA_ "GenSigSendType" SG_ 578 C_RRLumbarLowSw_HU 4;
BA_ "UserSigValidity" SG_ 578 C_RRLumbarLowSw_HU 0;
BA_REL_ "GenSigTimeoutTime" BU_SG_REL_ APSU SG_ 578 C_RRLumbarLowSw_HU 1500;
BA_REL_ "GenSigTimeoutTime" BU_SG_REL_ RRPSU SG_ 578 C_RRLumbarLowSw_HU 1500;
BA_ "Version" SG_ 578 C_RRLumbarLowSw_HU "19.11.09";
BA_ "GenSigSendType" SG_ 578 C_RRLumbarDefSw_HU 4;
BA_ "UserSigValidity" SG_ 578 C_RRLumbarDefSw_HU 0;
BA_REL_ "GenSigTimeoutTime" BU_SG_REL_ APSU SG_ 578 C_RRLumbarDefSw_HU 1500;
BA_REL_ "GenSigTimeoutTime" BU_SG_REL_ RRPSU SG_ 578 C_RRLumbarDefSw_HU 1500;
BA_ "Version" SG_ 578 C_RRLumbarDefSw_HU "19.11.09";
BA_ "GenSigSendType" SG_ 578 C_RRBolsterInfSw_HU 4;
BA_ "UserSigValidity" SG_ 578 C_RRBolsterInfSw_HU 0;
BA_REL_ "GenSigTimeoutTime" BU_SG_REL_ APSU SG_ 578 C_RRBolsterInfSw_HU 1500;
BA_REL_ "GenSigTimeoutTime" BU_SG_REL_ RRPSU SG_ 578 C_RRBolsterInfSw_HU 1500;
BA_ "Version" SG_ 578 C_RRBolsterInfSw_HU "19.11.09";
BA_ "GenSigSendType" SG_ 578 C_RRLegSupUpSw_HU 4;
BA_ "UserSigValidity" SG_ 578 C_RRLegSupUpSw_HU 0;
BA_REL_ "GenSigTimeoutTime" BU_SG_REL_ APSU SG_ 578 C_RRLegSupUpSw_HU 1500;
BA_REL_ "GenSigTimeoutTime" BU_SG_REL_ RRPSU SG_ 578 C_RRLegSupUpSw_HU 1500;
BA_REL_ "GenSigTimeoutTime" BU_SG_REL_ RLPSU SG_ 578 C_RRLegSupUpSw_HU 1500;
BA_ "Version" SG_ 578 C_RRLegSupUpSw_HU "19.11.09";
BA_ "GenSigSendType" SG_ 578 C_RROneTchNValueSet 4;
BA_ "UserSigValidity" SG_ 578 C_RROneTchNValueSet 0;
BA_REL_ "GenSigTimeoutTime" BU_SG_REL_ APSU SG_ 578 C_RROneTchNValueSet 1500;
BA_REL_ "GenSigTimeoutTime" BU_SG_REL_ RRPSU SG_ 578 C_RROneTchNValueSet 1500;
BA_REL_ "GenSigTimeoutTime" BU_SG_REL_ RLPSU SG_ 578 C_RROneTchNValueSet 1500;
BA_REL_ "GenSigTimeoutTime" BU_SG_REL_ ATS SG_ 578 C_RROneTchNValueSet 1500;
BA_ "Version" SG_ 578 C_RROneTchNValueSet "19.11.09";
BA_ "GenSigSendType" SG_ 578 C_RLOneTchNValueSet 4;
BA_ "UserSigValidity" SG_ 578 C_RLOneTchNValueSet 0;
BA_REL_ "GenSigTimeoutTime" BU_SG_REL_ APSU SG_ 578 C_RLOneTchNValueSet 1500;
BA_REL_ "GenSigTimeoutTime" BU_SG_REL_ RRPSU SG_ 578 C_RLOneTchNValueSet 1500;
BA_REL_ "GenSigTimeoutTime" BU_SG_REL_ RLPSU SG_ 578 C_RLOneTchNValueSet 1500;
BA_REL_ "GenSigTimeoutTime" BU_SG_REL_ ATS SG_ 578 C_RLOneTchNValueSet 1500;
BA_ "Version" SG_ 578 C_RLOneTchNValueSet "19.11.09";
BA_ "GenSigSendType" SG_ 578 C_RRBolsterDefSw_HU 4;
BA_ "UserSigValidity" SG_ 578 C_RRBolsterDefSw_HU 0;
BA_REL_ "GenSigTimeoutTime" BU_SG_REL_ APSU SG_ 578 C_RRBolsterDefSw_HU 1500;
BA_REL_ "GenSigTimeoutTime" BU_SG_REL_ RRPSU SG_ 578 C_RRBolsterDefSw_HU 1500;
BA_ "Version" SG_ 578 C_RRBolsterDefSw_HU "19.11.09";
BA_ "GenSigSendType" SG_ 578 C_AstRlxTiltUpSw_HU 4;
BA_ "UserSigValidity" SG_ 578 C_AstRlxTiltUpSw_HU 0;
BA_REL_ "GenSigTimeoutTime" BU_SG_REL_ APSU SG_ 578 C_AstRlxTiltUpSw_HU 1500;
BA_ "Version" SG_ 578 C_AstRlxTiltUpSw_HU "19.12.02";
BA_ "GenSigSendType" SG_ 578 C_AstRlxTiltDnSw_HU 4;
BA_ "UserSigValidity" SG_ 578 C_AstRlxTiltDnSw_HU 0;
BA_REL_ "GenSigTimeoutTime" BU_SG_REL_ APSU SG_ 578 C_AstRlxTiltDnSw_HU 1500;
BA_ "Version" SG_ 578 C_AstRlxTiltDnSw_HU "19.12.02";
BA_ "GenSigSendType" SG_ 578 C_RLRSEUpSw_HU 4;
BA_ "UserSigValidity" SG_ 578 C_RLRSEUpSw_HU 0;
BA_REL_ "GenSigTimeoutTime" BU_SG_REL_ APSU SG_ 578 C_RLRSEUpSw_HU 1500;
BA_REL_ "GenSigTimeoutTime" BU_SG_REL_ RRPSU SG_ 578 C_RLRSEUpSw_HU 1500;
BA_REL_ "GenSigTimeoutTime" BU_SG_REL_ RLPSU SG_ 578 C_RLRSEUpSw_HU 1500;
BA_ "Version" SG_ 578 C_RLRSEUpSw_HU "19.12.02";
BA_ "GenSigSendType" SG_ 578 C_RLRSEDnSw_HU 4;
BA_ "UserSigValidity" SG_ 578 C_RLRSEDnSw_HU 0;
BA_REL_ "GenSigTimeoutTime" BU_SG_REL_ APSU SG_ 578 C_RLRSEDnSw_HU 1500;
BA_REL_ "GenSigTimeoutTime" BU_SG_REL_ RRPSU SG_ 578 C_RLRSEDnSw_HU 1500;
BA_REL_ "GenSigTimeoutTime" BU_SG_REL_ RLPSU SG_ 578 C_RLRSEDnSw_HU 1500;
BA_ "Version" SG_ 578 C_RLRSEDnSw_HU "19.12.02";
BA_ "GenSigSendType" SG_ 578 C_RRRSEUpSw_HU 4;
BA_ "UserSigValidity" SG_ 578 C_RRRSEUpSw_HU 0;
BA_REL_ "GenSigTimeoutTime" BU_SG_REL_ APSU SG_ 578 C_RRRSEUpSw_HU 1500;
BA_REL_ "GenSigTimeoutTime" BU_SG_REL_ RRPSU SG_ 578 C_RRRSEUpSw_HU 1500;
BA_REL_ "GenSigTimeoutTime" BU_SG_REL_ RLPSU SG_ 578 C_RRRSEUpSw_HU 1500;
BA_ "Version" SG_ 578 C_RRRSEUpSw_HU "19.12.02";
BA_ "GenSigSendType" SG_ 578 C_RRLegSupDnSw_HU 4;
BA_ "UserSigValidity" SG_ 578 C_RRLegSupDnSw_HU 0;
BA_REL_ "GenSigTimeoutTime" BU_SG_REL_ APSU SG_ 578 C_RRLegSupDnSw_HU 1500;
BA_REL_ "GenSigTimeoutTime" BU_SG_REL_ RRPSU SG_ 578 C_RRLegSupDnSw_HU 1500;
BA_REL_ "GenSigTimeoutTime" BU_SG_REL_ RLPSU SG_ 578 C_RRLegSupDnSw_HU 1500;
BA_ "Version" SG_ 578 C_RRLegSupDnSw_HU "19.11.09";
BA_ "GenSigSendType" SG_ 578 C_RRRSEDnSw_HU 4;
BA_ "UserSigValidity" SG_ 578 C_RRRSEDnSw_HU 0;
BA_REL_ "GenSigTimeoutTime" BU_SG_REL_ APSU SG_ 578 C_RRRSEDnSw_HU 1500;
BA_REL_ "GenSigTimeoutTime" BU_SG_REL_ RRPSU SG_ 578 C_RRRSEDnSw_HU 1500;
BA_REL_ "GenSigTimeoutTime" BU_SG_REL_ RLPSU SG_ 578 C_RRRSEDnSw_HU 1500;
BA_ "Version" SG_ 578 C_RRRSEDnSw_HU "19.12.02";
BA_ "GenSigSendType" SG_ 578 C_RRHrestUpSw_HU 4;
BA_ "UserSigValidity" SG_ 578 C_RRHrestUpSw_HU 0;
BA_REL_ "GenSigTimeoutTime" BU_SG_REL_ APSU SG_ 578 C_RRHrestUpSw_HU 1500;
BA_REL_ "GenSigTimeoutTime" BU_SG_REL_ RRPSU SG_ 578 C_RRHrestUpSw_HU 1500;
BA_REL_ "GenSigTimeoutTime" BU_SG_REL_ RLPSU SG_ 578 C_RRHrestUpSw_HU 1500;
BA_ "Version" SG_ 578 C_RRHrestUpSw_HU "19.11.09";
BA_ "GenMsgCycleTime" BO_ 95 0;
BA_ "Description" SG_ 95 CF_AVN_MdLpBttmRedNvalueSet "USM Mood Lamp Bottom Red Color Set signal";
BA_ "GenSigSendType" SG_ 95 CF_AVN_MdLpBttmRedNvalueSet 4;
BA_ "GenSigStartValue" SG_ 95 CF_AVN_MdLpBttmRedNvalueSet 512;
BA_ "UserSigValidity" SG_ 95 CF_AVN_MdLpBttmRedNvalueSet 3;
BA_ "Version" SG_ 95 CF_AVN_MdLpBttmRedNvalueSet "21.05.01";
BA_ "Description" SG_ 95 CF_AVN_MdLpBttmGreenNvalueSet "USM Mood Lamp Bottom Green Color Set signal";
BA_ "GenSigSendType" SG_ 95 CF_AVN_MdLpBttmGreenNvalueSet 4;
BA_ "GenSigStartValue" SG_ 95 CF_AVN_MdLpBttmGreenNvalueSet 512;
BA_ "UserSigValidity" SG_ 95 CF_AVN_MdLpBttmGreenNvalueSet 3;
BA_ "Version" SG_ 95 CF_AVN_MdLpBttmGreenNvalueSet "21.05.01";
BA_ "Description" SG_ 95 CF_AVN_MdLpBttmBlueNvalueSet "USM Mood Lamp Bottom Red Color Set Signal";
BA_ "GenSigSendType" SG_ 95 CF_AVN_MdLpBttmBlueNvalueSet 4;
BA_ "GenSigStartValue" SG_ 95 CF_AVN_MdLpBttmBlueNvalueSet 512;
BA_ "UserSigValidity" SG_ 95 CF_AVN_MdLpBttmBlueNvalueSet 3;
BA_ "Version" SG_ 95 CF_AVN_MdLpBttmBlueNvalueSet "21.05.01";
BA_ "Description" SG_ 95 CF_AVN_MdLpSpdModNvalueSet "USM Mood Lamp Speed relation setting Set signal";
BA_ "GenSigSendType" SG_ 95 CF_AVN_MdLpSpdModNvalueSet 4;
BA_ "UserSigValidity" SG_ 95 CF_AVN_MdLpSpdModNvalueSet 3;
BA_ "Version" SG_ 95 CF_AVN_MdLpSpdModNvalueSet "21.05.01";
BA_ "Description" SG_ 95 CF_AVN_MdLpColorModNvalueSet "USM Mood Lamp Mode number Set signal";
BA_ "GenSigSendType" SG_ 95 CF_AVN_MdLpColorModNvalueSet 4;
BA_ "UserSigValidity" SG_ 95 CF_AVN_MdLpColorModNvalueSet 3;
BA_ "Version" SG_ 95 CF_AVN_MdLpColorModNvalueSet "21.05.01";
BA_ "GenSigSendType" SG_ 95 CF_AVN_AIVoiceModNvalueSet 4;
BA_ "UserSigValidity" SG_ 95 CF_AVN_AIVoiceModNvalueSet 3;
BA_REL_ "GenSigTimeoutTime" BU_SG_REL_ SWRC SG_ 95 CF_AVN_AIVoiceModNvalueSet 0;
BA_ "Version" SG_ 95 CF_AVN_AIVoiceModNvalueSet "21.07.05";
BA_ "GenSigSendType" SG_ 95 CF_AVN_AIVoiceMicModNvalue 4;
BA_ "UserSigValidity" SG_ 95 CF_AVN_AIVoiceMicModNvalue 3;
BA_REL_ "GenSigTimeoutTime" BU_SG_REL_ SWRC SG_ 95 CF_AVN_AIVoiceMicModNvalue 0;
BA_ "Version" SG_ 95 CF_AVN_AIVoiceMicModNvalue "22.01.06";
BA_ "GenSigSendType" SG_ 95 CF_AVN_AIVoiceTTSModNvalue 4;
BA_ "UserSigValidity" SG_ 95 CF_AVN_AIVoiceTTSModNvalue 3;
BA_REL_ "GenSigTimeoutTime" BU_SG_REL_ SWRC SG_ 95 CF_AVN_AIVoiceTTSModNvalue 0;
BA_ "Version" SG_ 95 CF_AVN_AIVoiceTTSModNvalue "22.01.06";
BA_ "Description" SG_ 95 CF_AVN_WiperAutoModeSet "Auto Washer Mode Wiper working set signal";
BA_ "GenSigSendType" SG_ 95 CF_AVN_WiperAutoModeSet 4;
BA_ "UserSigValidity" SG_ 95 CF_AVN_WiperAutoModeSet 3;
BA_ "Version" SG_ 95 CF_AVN_WiperAutoModeSet "21.12.00";
BA_ "Description" SG_ 95 CF_AVN_AFCUAutoWashModeSet "Auto wash set signal for AFCU unit";
BA_ "GenSigSendType" SG_ 95 CF_AVN_AFCUAutoWashModeSet 4;
BA_ "UserSigValidity" SG_ 95 CF_AVN_AFCUAutoWashModeSet 3;
BA_ "Version" SG_ 95 CF_AVN_AFCUAutoWashModeSet "22.01.06";
BA_ "Description" SG_ 95 CF_AVN_PSDAutoWashModeSet "Auto wash mode set signal for PSD Unit";
BA_ "GenSigSendType" SG_ 95 CF_AVN_PSDAutoWashModeSet 4;
BA_ "UserSigValidity" SG_ 95 CF_AVN_PSDAutoWashModeSet 3;
BA_ "Version" SG_ 95 CF_AVN_PSDAutoWashModeSet "22.01.06";
BA_ "Description" SG_ 95 CF_AVN_PTGAutoWashModeSet "Auto Wash Mode Set signal for PTG(PTL) Unit";
BA_ "GenSigSendType" SG_ 95 CF_AVN_PTGAutoWashModeSet 4;
BA_ "UserSigValidity" SG_ 95 CF_AVN_PTGAutoWashModeSet 3;
BA_ "Version" SG_ 95 CF_AVN_PTGAutoWashModeSet "22.01.06";
BA_ "Description" SG_ 95 CF_AVN_CDMAutoWashModeSet "Auto wash mode set signal for CDM";
BA_ "GenSigSendType" SG_ 95 CF_AVN_CDMAutoWashModeSet 4;
BA_ "UserSigValidity" SG_ 95 CF_AVN_CDMAutoWashModeSet 3;
BA_ "Version" SG_ 95 CF_AVN_CDMAutoWashModeSet "22.02.01";
BA_ "GenMsgSendType" BO_ 2281833729 0;
BA_ "GenMsgCycleTimeFast" BO_ 2281833729 0;
BA_ "GenMsgNrOfRepetition" BO_ 2281833729 0;
BA_ "VFrameFormat" BO_ 2281833729 1;
BA_ "Description" SG_ 2281833729 ICSC_Crc2Val "The data area for CRC calculation is based on the data length (DLC) of the message DB.

The CRC shall be calculated over the entire data block (excluding the CRC bytes) including the user data, alive counter and Data ID

 

- CRC Polynomial (0x1021) , Initial Value : 0xFFFF, XOR value : 0x0000, Data ID : Message ID + 0xF800 

- The initial value is for CRC calculation and the message should be sent with the calculated result value. 

- The mathematical expression to 16 bit CRC polynomial is given here. G(x) = x16 + x12 + x5 + 1";
BA_ "GenSigStartValue" SG_ 2281833729 ICSC_Crc2Val 65535;
BA_ "UserSigValidity" SG_ 2281833729 ICSC_Crc2Val 3;
BA_ "RoutingFactor" SG_ 2281833729 ICSC_Crc2Val 2;
BA_ "Version" SG_ 2281833729 ICSC_Crc2Val "18.11.08";
BA_ "Description" SG_ 2281833729 ICSC_AlvCnt2Val "For the first transmission request for a data element the counter shall be initialized with 0 and shall be incremented by 1 for every subsequent send request. 

When the counter reaches the maximum value(0xFF), then it shall restart with 0 for the next send request";
BA_ "UserSigValidity" SG_ 2281833729 ICSC_AlvCnt2Val 3;
BA_ "RoutingFactor" SG_ 2281833729 ICSC_AlvCnt2Val 2;
BA_ "Version" SG_ 2281833729 ICSC_AlvCnt2Val "18.11.08";
BA_ "Description" SG_ 2281833729 DMIC_DrvModSta "This signal is feedback state of driving mode for Cluster/AVN

This message is for DMIC(Driving Mode Integrated Control)";
BA_ "UserSigValidity" SG_ 2281833729 DMIC_DrvModSta 3;
BA_REL_ "GenSigTimeoutTime" BU_SG_REL_ APSU SG_ 2281833729 DMIC_DrvModSta 1500;
BA_REL_ "GenSigTimeoutTime" BU_SG_REL_ DLBCU SG_ 2281833729 DMIC_DrvModSta 1500;
BA_REL_ "GenSigTimeoutTime" BU_SG_REL_ DSAU SG_ 2281833729 DMIC_DrvModSta 1500;
BA_REL_ "GenSigTimeoutTime" BU_SG_REL_ ASAU SG_ 2281833729 DMIC_DrvModSta 1500;
BA_REL_ "GenSigTimeoutTime" BU_SG_REL_ ALBCU SG_ 2281833729 DMIC_DrvModSta 1500;
BA_ "RoutingFactor" SG_ 2281833729 DMIC_DrvModSta 2;
BA_ "Version" SG_ 2281833729 DMIC_DrvModSta "20.07.10";
BA_ "Description" SG_ 2281833729 DMIC_SmtShftModSta "This signal is a smart shift mode flag.";
BA_ "UserSigValidity" SG_ 2281833729 DMIC_SmtShftModSta 3;
BA_ "RoutingFactor" SG_ 2281833729 DMIC_SmtShftModSta 2;
BA_ "Version" SG_ 2281833729 DMIC_SmtShftModSta "17.12.00";
BA_ "Description" SG_ 2281833729 DMIC_EngModSta "This Signal is the request on mode transition for Controlling the Driving Mode.";
BA_ "UserSigValidity" SG_ 2281833729 DMIC_EngModSta 3;
BA_ "RoutingFactor" SG_ 2281833729 DMIC_EngModSta 2;
BA_ "Version" SG_ 2281833729 DMIC_EngModSta "20.05.02";
BA_ "Description" SG_ 2281833729 DMIC_IndEngModSta "This signal is for feedback about individual mode setting on AVN.";
BA_ "UserSigValidity" SG_ 2281833729 DMIC_IndEngModSta 3;
BA_ "RoutingFactor" SG_ 2281833729 DMIC_IndEngModSta 2;
BA_ "Version" SG_ 2281833729 DMIC_IndEngModSta "19.09.00";
BA_ "Description" SG_ 2281833729 DMIC_TmModSta "This Signal is the request on mode transition for Controlling the Driving Mode.";
BA_ "UserSigValidity" SG_ 2281833729 DMIC_TmModSta 3;
BA_ "RoutingFactor" SG_ 2281833729 DMIC_TmModSta 2;
BA_ "Version" SG_ 2281833729 DMIC_TmModSta "20.05.02";
BA_ "Description" SG_ 2281833729 DMIC_IndTmModSta "This signal is for feedback about individual mode setting on AVN.";
BA_ "UserSigValidity" SG_ 2281833729 DMIC_IndTmModSta 3;
BA_ "RoutingFactor" SG_ 2281833729 DMIC_IndTmModSta 2;
BA_ "Version" SG_ 2281833729 DMIC_IndTmModSta "19.09.00";
BA_ "Description" SG_ 2281833729 DMIC_EscModSta "This Signal is the request on mode transition for Controlling the Driving Mode.";
BA_ "UserSigValidity" SG_ 2281833729 DMIC_EscModSta 3;
BA_ "RoutingFactor" SG_ 2281833729 DMIC_EscModSta 2;
BA_ "Version" SG_ 2281833729 DMIC_EscModSta "20.05.02";
BA_ "Description" SG_ 2281833729 DMIC_IndEscModSta "This signal is for feedback about individual mode setting on AVN.";
BA_ "UserSigValidity" SG_ 2281833729 DMIC_IndEscModSta 3;
BA_ "RoutingFactor" SG_ 2281833729 DMIC_IndEscModSta 2;
BA_ "Version" SG_ 2281833729 DMIC_IndEscModSta "17.12.00";
BA_ "Description" SG_ 2281833729 DMIC_MdpsModSta "This Signal is the request on mode transition for Controlling the Driving Mode.";
BA_ "UserSigValidity" SG_ 2281833729 DMIC_MdpsModSta 3;
BA_ "RoutingFactor" SG_ 2281833729 DMIC_MdpsModSta 2;
BA_ "Version" SG_ 2281833729 DMIC_MdpsModSta "20.05.02";
BA_ "Description" SG_ 2281833729 DMIC_IndMdpsModSta "This signal is for feedback about individual mode setting on AVN.";
BA_ "UserSigValidity" SG_ 2281833729 DMIC_IndMdpsModSta 3;
BA_ "RoutingFactor" SG_ 2281833729 DMIC_IndMdpsModSta 2;
BA_ "Version" SG_ 2281833729 DMIC_IndMdpsModSta "19.09.00";
BA_ "GenMsgSendType" BO_ 2281833731 0;
BA_ "GenMsgCycleTimeFast" BO_ 2281833731 0;
BA_ "GenMsgNrOfRepetition" BO_ 2281833731 0;
BA_ "VFrameFormat" BO_ 2281833731 1;
BA_ "Description" SG_ 2281833731 DMIC_VcuModSta "This Signal is the request on mode transition for Controlling the Driving Mode.";
BA_ "UserSigValidity" SG_ 2281833731 DMIC_VcuModSta 3;
BA_ "RoutingFactor" SG_ 2281833731 DMIC_VcuModSta 2;
BA_ "Version" SG_ 2281833731 DMIC_VcuModSta "20.05.02";
BA_ "Description" SG_ 2281833731 DMIC_DrvModTyp "This signal indicates drive mode type.";
BA_ "UserSigValidity" SG_ 2281833731 DMIC_DrvModTyp 3;
BA_ "RoutingFactor" SG_ 2281833731 DMIC_DrvModTyp 2;
BA_ "Version" SG_ 2281833731 DMIC_DrvModTyp "19.11.05";
BA_ "Description" SG_ 2281833731 DMIC_EngFltSta "This signal indicates fault status of individual systems.";
BA_ "UserSigValidity" SG_ 2281833731 DMIC_EngFltSta 3;
BA_ "RoutingFactor" SG_ 2281833731 DMIC_EngFltSta 2;
BA_ "Version" SG_ 2281833731 DMIC_EngFltSta "17.12.00";
BA_ "Description" SG_ 2281833731 DMIC_TmFltSta "This signal indicates fault status of individual systems.";
BA_ "UserSigValidity" SG_ 2281833731 DMIC_TmFltSta 3;
BA_ "RoutingFactor" SG_ 2281833731 DMIC_TmFltSta 2;
BA_ "Version" SG_ 2281833731 DMIC_TmFltSta "17.12.00";
BA_ "Description" SG_ 2281833731 DMIC_EscFltSta "This signal indicates fault status of individual systems.";
BA_ "UserSigValidity" SG_ 2281833731 DMIC_EscFltSta 3;
BA_ "RoutingFactor" SG_ 2281833731 DMIC_EscFltSta 2;
BA_ "Version" SG_ 2281833731 DMIC_EscFltSta "17.12.00";
BA_ "Description" SG_ 2281833731 DMIC_MdpsFltSta "This signal indicates fault status of individual systems.";
BA_ "UserSigValidity" SG_ 2281833731 DMIC_MdpsFltSta 3;
BA_ "RoutingFactor" SG_ 2281833731 DMIC_MdpsFltSta 2;
BA_ "Version" SG_ 2281833731 DMIC_MdpsFltSta "17.12.00";
BA_ "Description" SG_ 2281833731 DMIC_EcsFltSta "This signal indicates fault status of individual systems.";
BA_ "UserSigValidity" SG_ 2281833731 DMIC_EcsFltSta 3;
BA_ "RoutingFactor" SG_ 2281833731 DMIC_EcsFltSta 2;
BA_ "Version" SG_ 2281833731 DMIC_EcsFltSta "17.12.00";
BA_ "Description" SG_ 2281833731 DMIC_AwdFltSta "This signal indicates fault status of individual systems.";
BA_ "UserSigValidity" SG_ 2281833731 DMIC_AwdFltSta 3;
BA_ "RoutingFactor" SG_ 2281833731 DMIC_AwdFltSta 2;
BA_ "Version" SG_ 2281833731 DMIC_AwdFltSta "17.12.00";
BA_ "Description" SG_ 2281833731 DMIC_RevFltSta "This signal indicates fault status of individual systems.";
BA_ "UserSigValidity" SG_ 2281833731 DMIC_RevFltSta 3;
BA_ "RoutingFactor" SG_ 2281833731 DMIC_RevFltSta 2;
BA_ "Version" SG_ 2281833731 DMIC_RevFltSta "17.12.00";
BA_ "Description" SG_ 2281833731 DMIC_PrflFltSta "This signal indicates fault status of individual systems.";
BA_ "UserSigValidity" SG_ 2281833731 DMIC_PrflFltSta 3;
BA_ "RoutingFactor" SG_ 2281833731 DMIC_PrflFltSta 2;
BA_ "Version" SG_ 2281833731 DMIC_PrflFltSta "17.12.00";
BA_ "Description" SG_ 2281833731 DMIC_ElsdFltSta "This signal indicates fault status of individual systems.";
BA_ "UserSigValidity" SG_ 2281833731 DMIC_ElsdFltSta 3;
BA_ "RoutingFactor" SG_ 2281833731 DMIC_ElsdFltSta 2;
BA_ "Version" SG_ 2281833731 DMIC_ElsdFltSta "17.12.00";
BA_ "Description" SG_ 2281833731 DMIC_EsndFltSta "This signal indicates fault status of individual systems.";
BA_ "UserSigValidity" SG_ 2281833731 DMIC_EsndFltSta 3;
BA_ "RoutingFactor" SG_ 2281833731 DMIC_EsndFltSta 2;
BA_ "Version" SG_ 2281833731 DMIC_EsndFltSta "17.12.00";
BA_ "Description" SG_ 2281833731 DMIC_RwsFltSta "This signal indicates fault status of individual systems.";
BA_ "UserSigValidity" SG_ 2281833731 DMIC_RwsFltSta 3;
BA_ "RoutingFactor" SG_ 2281833731 DMIC_RwsFltSta 2;
BA_ "Version" SG_ 2281833731 DMIC_RwsFltSta "17.11.00";
BA_ "Description" SG_ 2281833731 DMIC_IndWhlDrvSta "This signal is for feedback about tune-up mode(Wheel Drive type) setting on AVN.";
BA_ "UserSigValidity" SG_ 2281833731 DMIC_IndWhlDrvSta 3;
BA_ "RoutingFactor" SG_ 2281833731 DMIC_IndWhlDrvSta 2;
BA_ "Version" SG_ 2281833731 DMIC_IndWhlDrvSta "20.12.04";
BA_ "Description" SG_ 2281833731 DMIC_IndVcuModSta "This signal is for feedback about individual mode setting on AVN.";
BA_ "UserSigValidity" SG_ 2281833731 DMIC_IndVcuModSta 3;
BA_ "RoutingFactor" SG_ 2281833731 DMIC_IndVcuModSta 2;
BA_ "Version" SG_ 2281833731 DMIC_IndVcuModSta "20.04.02";
BA_ "Description" SG_ 2281833731 DMIC_VcuFltSta "This signal indicates fault status of individual systems.";
BA_ "UserSigValidity" SG_ 2281833731 DMIC_VcuFltSta 3;
BA_ "RoutingFactor" SG_ 2281833731 DMIC_VcuFltSta 2;
BA_ "Version" SG_ 2281833731 DMIC_VcuFltSta "20.04.02";
BA_ "Description" SG_ 2281833731 DMIC_IndMtrPwrSta "This signal is for feedback about tune-up mode(Motor Power) setting on AVN.";
BA_ "UserSigValidity" SG_ 2281833731 DMIC_IndMtrPwrSta 3;
BA_ "RoutingFactor" SG_ 2281833731 DMIC_IndMtrPwrSta 2;
BA_ "Version" SG_ 2281833731 DMIC_IndMtrPwrSta "20.12.04";
BA_ "Description" SG_ 2281833731 DMIC_IndAccSenSta "This signal is for feedback about tune-up mode(Acceleration sensitivity) setting on AVN.";
BA_ "UserSigValidity" SG_ 2281833731 DMIC_IndAccSenSta 3;
BA_ "RoutingFactor" SG_ 2281833731 DMIC_IndAccSenSta 2;
BA_ "Version" SG_ 2281833731 DMIC_IndAccSenSta "20.12.04";
BA_ "Description" SG_ 2281833731 DMIC_IndDecSenSta "This signal is for feedback about tune-up mode(Deceleration sensitivity) setting on AVN.";
BA_ "UserSigValidity" SG_ 2281833731 DMIC_IndDecSenSta 3;
BA_ "RoutingFactor" SG_ 2281833731 DMIC_IndDecSenSta 2;
BA_ "Version" SG_ 2281833731 DMIC_IndDecSenSta "20.12.04";
BA_ "Description" SG_ 2281833731 DMIC_IndMaxVehSpdSta "This signal is for feedback about tune-up mode(Maximum vehicle speed) setting on AVN.";
BA_ "UserSigValidity" SG_ 2281833731 DMIC_IndMaxVehSpdSta 3;
BA_ "RoutingFactor" SG_ 2281833731 DMIC_IndMaxVehSpdSta 2;
BA_ "Version" SG_ 2281833731 DMIC_IndMaxVehSpdSta "20.12.04";
BA_ "Description" SG_ 2281833731 DMIC_DrvMod2Typ "This signal indicates drive mode type.";
BA_ "UserSigValidity" SG_ 2281833731 DMIC_DrvMod2Typ 3;
BA_ "RoutingFactor" SG_ 2281833731 DMIC_DrvMod2Typ 2;
BA_ "Version" SG_ 2281833731 DMIC_DrvMod2Typ "20.04.04";
BA_ "Description" SG_ 2281833731 DMIC_DrvModFltSta "This signal is for Driving mode fault status. From this signal, AVN can deactivate any driving in mode selection menu.";
BA_ "UserSigValidity" SG_ 2281833731 DMIC_DrvModFltSta 3;
BA_ "RoutingFactor" SG_ 2281833731 DMIC_DrvModFltSta 2;
BA_ "Version" SG_ 2281833731 DMIC_DrvModFltSta "17.12.00";
BA_ "GenMsgSendType" BO_ 1041 0;
BA_ "Description" SG_ 1041 ICU_Crc2Val "The data area for CRC calculation is based on the data length (DLC) of the message DB.

The CRC shall be calculated over the entire data block (excluding the CRC bytes) including the user data, alive counter and Data ID 

 

- CRC Polynomial (0x1D) , Initial Value : 0x00, XOR value : 0xFF, Data ID Mode : Both, Data ID : Message ID + 0xF800 

- The initial value is for CRC calculation and the message should be sent with the calculated result value. 

The mathematical expression to 8 bit CRC polynomial is given here. G(x) = x8 + x4 + x3 + x2 + 1";
BA_ "GenSigSendType" SG_ 1041 ICU_Crc2Val 4;
BA_ "GenSigStartValue" SG_ 1041 ICU_Crc2Val 255;
BA_ "UserSigValidity" SG_ 1041 ICU_Crc2Val 0;
BA_ "Version" SG_ 1041 ICU_Crc2Val "18.11.08";
BA_ "Description" SG_ 1041 ICU_MtGearPosRSta "Manual Shift Lever R Switch Status 0x0:Off/0x1:On";
BA_ "GenSigSendType" SG_ 1041 ICU_MtGearPosRSta 4;
BA_ "UserSigValidity" SG_ 1041 ICU_MtGearPosRSta 3;
BA_REL_ "GenSigTimeoutTime" BU_SG_REL_ BLTN_CAM SG_ 1041 ICU_MtGearPosRSta 1500;
BA_ "Version" SG_ 1041 ICU_MtGearPosRSta "21.07.05";
BA_ "Description" SG_ 1041 ICU_AlvCnt2Val "For the first transmission request for a data element the counter shall be initialized with 0 and shall be incremented by 1

for every subsequent send request. When the counter reaches the maximum value(0xE), then it shall restart with 0 for the next send request";
BA_ "GenSigSendType" SG_ 1041 ICU_AlvCnt2Val 4;
BA_ "UserSigValidity" SG_ 1041 ICU_AlvCnt2Val 0;
BA_ "Version" SG_ 1041 ICU_AlvCnt2Val "18.11.08";
BA_ "Description" SG_ 1041 Autocut_DlvryModSta "-(Old)C_SJB_DeliveryMode

-Initial value: 1";
BA_ "GenSigSendType" SG_ 1041 Autocut_DlvryModSta 4;
BA_ "GenSigStartValue" SG_ 1041 Autocut_DlvryModSta 1;
BA_ "UserSigValidity" SG_ 1041 Autocut_DlvryModSta 0;
BA_ "NetworkRequest" SG_ 1041 Autocut_DlvryModSta 0;
BA_ "NetworkRequestHoldingTime" SG_ 1041 Autocut_DlvryModSta 5000;
BA_ "Version" SG_ 1041 Autocut_DlvryModSta "17.12.00";
BA_ "GenSigSendType" SG_ 1041 DoorLock_AsstDrUnLkSta 4;
BA_ "UserSigValidity" SG_ 1041 DoorLock_AsstDrUnLkSta 0;
BA_ "NetworkRequest" SG_ 1041 DoorLock_AsstDrUnLkSta 0;
BA_ "NetworkRequestHoldingTime" SG_ 1041 DoorLock_AsstDrUnLkSta 5000;
BA_ "Version" SG_ 1041 DoorLock_AsstDrUnLkSta "17.12.00";
BA_ "GenSigSendType" SG_ 1041 Warn_DrvDrSwSta 4;
BA_ "UserSigValidity" SG_ 1041 Warn_DrvDrSwSta 0;
BA_REL_ "GenSigTimeoutTime" BU_SG_REL_ WPC SG_ 1041 Warn_DrvDrSwSta 1500;
BA_REL_ "GenSigTimeoutTime" BU_SG_REL_ RWPC SG_ 1041 Warn_DrvDrSwSta 1500;
BA_REL_ "GenSigTimeoutTime" BU_SG_REL_ DPSU SG_ 1041 Warn_DrvDrSwSta 1500;
BA_REL_ "GenSigTimeoutTime" BU_SG_REL_ BLTN_CAM SG_ 1041 Warn_DrvDrSwSta 1500;
BA_REL_ "GenSigTimeoutTime" BU_SG_REL_ WPC2 SG_ 1041 Warn_DrvDrSwSta 1500;
BA_ "NetworkRequest" SG_ 1041 Warn_DrvDrSwSta 0;
BA_ "NetworkRequestHoldingTime" SG_ 1041 Warn_DrvDrSwSta 5000;
BA_ "Version" SG_ 1041 Warn_DrvDrSwSta "17.12.00";
BA_ "GenSigSendType" SG_ 1041 DoorLock_DrvKeyUnLkSwSta 4;
BA_ "UserSigValidity" SG_ 1041 DoorLock_DrvKeyUnLkSwSta 0;
BA_ "NetworkRequest" SG_ 1041 DoorLock_DrvKeyUnLkSwSta 0;
BA_ "NetworkRequestHoldingTime" SG_ 1041 DoorLock_DrvKeyUnLkSwSta 5000;
BA_ "Version" SG_ 1041 DoorLock_DrvKeyUnLkSwSta "17.12.00";
BA_ "GenSigSendType" SG_ 1041 DoorLock_RrLftDrUnLkSta 4;
BA_ "UserSigValidity" SG_ 1041 DoorLock_RrLftDrUnLkSta 0;
BA_ "NetworkRequest" SG_ 1041 DoorLock_RrLftDrUnLkSta 0;
BA_ "NetworkRequestHoldingTime" SG_ 1041 DoorLock_RrLftDrUnLkSta 5000;
BA_ "Version" SG_ 1041 DoorLock_RrLftDrUnLkSta "17.12.00";
BA_ "GenSigSendType" SG_ 1041 DoorLock_RrRtDrUnLkSta 4;
BA_ "UserSigValidity" SG_ 1041 DoorLock_RrRtDrUnLkSta 0;
BA_ "NetworkRequest" SG_ 1041 DoorLock_RrRtDrUnLkSta 0;
BA_ "NetworkRequestHoldingTime" SG_ 1041 DoorLock_RrRtDrUnLkSta 5000;
BA_ "Version" SG_ 1041 DoorLock_RrRtDrUnLkSta "17.12.00";
BA_ "GenSigSendType" SG_ 1041 Warn_AsstDrSwSta 4;
BA_ "UserSigValidity" SG_ 1041 Warn_AsstDrSwSta 0;
BA_REL_ "GenSigTimeoutTime" BU_SG_REL_ WPC SG_ 1041 Warn_AsstDrSwSta 1500;
BA_REL_ "GenSigTimeoutTime" BU_SG_REL_ RWPC SG_ 1041 Warn_AsstDrSwSta 1500;
BA_REL_ "GenSigTimeoutTime" BU_SG_REL_ APSU SG_ 1041 Warn_AsstDrSwSta 1500;
BA_REL_ "GenSigTimeoutTime" BU_SG_REL_ RLPSU SG_ 1041 Warn_AsstDrSwSta 1500;
BA_REL_ "GenSigTimeoutTime" BU_SG_REL_ BLTN_CAM SG_ 1041 Warn_AsstDrSwSta 1500;
BA_REL_ "GenSigTimeoutTime" BU_SG_REL_ ALBCU SG_ 1041 Warn_AsstDrSwSta 1500;
BA_REL_ "GenSigTimeoutTime" BU_SG_REL_ WPC2 SG_ 1041 Warn_AsstDrSwSta 1500;
BA_ "NetworkRequest" SG_ 1041 Warn_AsstDrSwSta 0;
BA_ "NetworkRequestHoldingTime" SG_ 1041 Warn_AsstDrSwSta 5000;
BA_ "Version" SG_ 1041 Warn_AsstDrSwSta "17.12.00";
BA_ "Description" SG_ 1041 Warn_AsstStBltSwSta "-Default value: 0x1 (Belt)



-Initial value: 0x1 (Belt)



-Timeout value: 0x1 (Belt)";
BA_ "GenSigSendType" SG_ 1041 Warn_AsstStBltSwSta 4;
BA_ "GenSigStartValue" SG_ 1041 Warn_AsstStBltSwSta 1;
BA_ "UserSigValidity" SG_ 1041 Warn_AsstStBltSwSta 0;
BA_REL_ "GenSigTimeoutTime" BU_SG_REL_ PSB SG_ 1041 Warn_AsstStBltSwSta 1500;
BA_REL_ "GenSigTimeoutTime" BU_SG_REL_ APSU SG_ 1041 Warn_AsstStBltSwSta 1500;
BA_REL_ "GenSigTimeoutTime" BU_SG_REL_ RLPSU SG_ 1041 Warn_AsstStBltSwSta 1500;
BA_REL_ "GenSigTimeoutTime" BU_SG_REL_ ASAU SG_ 1041 Warn_AsstStBltSwSta 1500;
BA_REL_ "GenSigTimeoutTime" BU_SG_REL_ ALBCU SG_ 1041 Warn_AsstStBltSwSta 1500;
BA_ "NetworkRequest" SG_ 1041 Warn_AsstStBltSwSta 0;
BA_ "NetworkRequestHoldingTime" SG_ 1041 Warn_AsstStBltSwSta 5000;
BA_ "Version" SG_ 1041 Warn_AsstStBltSwSta "17.12.00";
BA_ "GenSigSendType" SG_ 1041 Warn_BrkFldSwSta 4;
BA_ "UserSigValidity" SG_ 1041 Warn_BrkFldSwSta 0;
BA_ "NetworkRequest" SG_ 1041 Warn_BrkFldSwSta 0;
BA_ "NetworkRequestHoldingTime" SG_ 1041 Warn_BrkFldSwSta 5000;
BA_ "Version" SG_ 1041 Warn_BrkFldSwSta "17.12.00";
BA_ "GenSigSendType" SG_ 1041 DoorLock_DrvKeyLkSwSta 4;
BA_ "UserSigValidity" SG_ 1041 DoorLock_DrvKeyLkSwSta 0;
BA_ "NetworkRequest" SG_ 1041 DoorLock_DrvKeyLkSwSta 0;
BA_ "NetworkRequestHoldingTime" SG_ 1041 DoorLock_DrvKeyLkSwSta 5000;
BA_ "Version" SG_ 1041 DoorLock_DrvKeyLkSwSta "17.12.00";
BA_ "GenSigSendType" SG_ 1041 Warn_DrvStBltSwSta 4;
BA_ "UserSigValidity" SG_ 1041 Warn_DrvStBltSwSta 0;
BA_REL_ "GenSigTimeoutTime" BU_SG_REL_ PSB SG_ 1041 Warn_DrvStBltSwSta 1500;
BA_REL_ "GenSigTimeoutTime" BU_SG_REL_ DPSU SG_ 1041 Warn_DrvStBltSwSta 1500;
BA_REL_ "GenSigTimeoutTime" BU_SG_REL_ DLBCU SG_ 1041 Warn_DrvStBltSwSta 1500;
BA_REL_ "GenSigTimeoutTime" BU_SG_REL_ ATS SG_ 1041 Warn_DrvStBltSwSta 1500;
BA_REL_ "GenSigTimeoutTime" BU_SG_REL_ DSAU SG_ 1041 Warn_DrvStBltSwSta 1500;
BA_REL_ "GenSigTimeoutTime" BU_SG_REL_ ASAU SG_ 1041 Warn_DrvStBltSwSta 1500;
BA_ "NetworkRequest" SG_ 1041 Warn_DrvStBltSwSta 0;
BA_ "NetworkRequestHoldingTime" SG_ 1041 Warn_DrvStBltSwSta 5000;
BA_ "Version" SG_ 1041 Warn_DrvStBltSwSta "17.12.00";
BA_ "GenSigSendType" SG_ 1041 Warn_HoodSwSta 4;
BA_ "UserSigValidity" SG_ 1041 Warn_HoodSwSta 0;
BA_REL_ "GenSigTimeoutTime" BU_SG_REL_ BLTN_CAM SG_ 1041 Warn_HoodSwSta 1500;
BA_ "NetworkRequest" SG_ 1041 Warn_HoodSwSta 0;
BA_ "NetworkRequestHoldingTime" SG_ 1041 Warn_HoodSwSta 5000;
BA_ "Version" SG_ 1041 Warn_HoodSwSta "17.12.00";
BA_ "Description" SG_ 1041 Warn_PassStOccSta "Passenger Seated State







-Default value: 0x0 (¹ÌÅ¾½Â)



-Initial value: 0x0 (¹ÌÅ¾½Â)



-Timeout value: 0x0 (¹ÌÅ¾½Â)";
BA_ "GenSigSendType" SG_ 1041 Warn_PassStOccSta 4;
BA_ "UserSigValidity" SG_ 1041 Warn_PassStOccSta 0;
BA_REL_ "GenSigTimeoutTime" BU_SG_REL_ APSU SG_ 1041 Warn_PassStOccSta 1500;
BA_ "NetworkRequest" SG_ 1041 Warn_PassStOccSta 0;
BA_ "NetworkRequestHoldingTime" SG_ 1041 Warn_PassStOccSta 5000;
BA_ "Version" SG_ 1041 Warn_PassStOccSta "17.12.00";
BA_ "GenSigSendType" SG_ 1041 Warn_PrkngBrkSwSta 4;
BA_ "UserSigValidity" SG_ 1041 Warn_PrkngBrkSwSta 0;
BA_REL_ "GenSigTimeoutTime" BU_SG_REL_ APSU SG_ 1041 Warn_PrkngBrkSwSta 1500;
BA_REL_ "GenSigTimeoutTime" BU_SG_REL_ RLHV SG_ 1041 Warn_PrkngBrkSwSta 1500;
BA_REL_ "GenSigTimeoutTime" BU_SG_REL_ RRHV SG_ 1041 Warn_PrkngBrkSwSta 1500;
BA_REL_ "GenSigTimeoutTime" BU_SG_REL_ PFSU SG_ 1041 Warn_PrkngBrkSwSta 1500;
BA_REL_ "GenSigTimeoutTime" BU_SG_REL_ RRPSU SG_ 1041 Warn_PrkngBrkSwSta 1500;
BA_REL_ "GenSigTimeoutTime" BU_SG_REL_ RLPSU SG_ 1041 Warn_PrkngBrkSwSta 1500;
BA_ "NetworkRequest" SG_ 1041 Warn_PrkngBrkSwSta 0;
BA_ "NetworkRequestHoldingTime" SG_ 1041 Warn_PrkngBrkSwSta 5000;
BA_ "Version" SG_ 1041 Warn_PrkngBrkSwSta "17.12.00";
BA_ "GenSigSendType" SG_ 1041 Warn_RrCtrStBltSwSta 4;
BA_ "UserSigValidity" SG_ 1041 Warn_RrCtrStBltSwSta 0;
BA_REL_ "GenSigTimeoutTime" BU_SG_REL_ PSB SG_ 1041 Warn_RrCtrStBltSwSta 1500;
BA_ "NetworkRequest" SG_ 1041 Warn_RrCtrStBltSwSta 0;
BA_ "NetworkRequestHoldingTime" SG_ 1041 Warn_RrCtrStBltSwSta 5000;
BA_ "Version" SG_ 1041 Warn_RrCtrStBltSwSta "17.12.00";
BA_ "GenSigSendType" SG_ 1041 Warn_RrLftDrSwSta 4;
BA_ "UserSigValidity" SG_ 1041 Warn_RrLftDrSwSta 0;
BA_REL_ "GenSigTimeoutTime" BU_SG_REL_ WPC SG_ 1041 Warn_RrLftDrSwSta 1500;
BA_REL_ "GenSigTimeoutTime" BU_SG_REL_ RWPC SG_ 1041 Warn_RrLftDrSwSta 1500;
BA_REL_ "GenSigTimeoutTime" BU_SG_REL_ APSU SG_ 1041 Warn_RrLftDrSwSta 1500;
BA_REL_ "GenSigTimeoutTime" BU_SG_REL_ RLHV SG_ 1041 Warn_RrLftDrSwSta 1500;
BA_REL_ "GenSigTimeoutTime" BU_SG_REL_ RLPSU SG_ 1041 Warn_RrLftDrSwSta 1500;
BA_REL_ "GenSigTimeoutTime" BU_SG_REL_ BLTN_CAM SG_ 1041 Warn_RrLftDrSwSta 1500;
BA_REL_ "GenSigTimeoutTime" BU_SG_REL_ WPC2 SG_ 1041 Warn_RrLftDrSwSta 1500;
BA_ "NetworkRequest" SG_ 1041 Warn_RrLftDrSwSta 0;
BA_ "NetworkRequestHoldingTime" SG_ 1041 Warn_RrLftDrSwSta 5000;
BA_ "Version" SG_ 1041 Warn_RrLftDrSwSta "17.12.00";
BA_ "GenSigSendType" SG_ 1041 Warn_RrLftStBltSwSta 4;
BA_ "UserSigValidity" SG_ 1041 Warn_RrLftStBltSwSta 0;
BA_REL_ "GenSigTimeoutTime" BU_SG_REL_ PSB SG_ 1041 Warn_RrLftStBltSwSta 1500;
BA_REL_ "GenSigTimeoutTime" BU_SG_REL_ APSU SG_ 1041 Warn_RrLftStBltSwSta 1500;
BA_REL_ "GenSigTimeoutTime" BU_SG_REL_ DPSU SG_ 1041 Warn_RrLftStBltSwSta 1500;
BA_ "NetworkRequest" SG_ 1041 Warn_RrLftStBltSwSta 0;
BA_ "NetworkRequestHoldingTime" SG_ 1041 Warn_RrLftStBltSwSta 5000;
BA_ "Version" SG_ 1041 Warn_RrLftStBltSwSta "17.12.00";
BA_ "GenSigSendType" SG_ 1041 Warn_RrRtDrSwSta 4;
BA_ "UserSigValidity" SG_ 1041 Warn_RrRtDrSwSta 0;
BA_REL_ "GenSigTimeoutTime" BU_SG_REL_ WPC SG_ 1041 Warn_RrRtDrSwSta 1500;
BA_REL_ "GenSigTimeoutTime" BU_SG_REL_ RWPC SG_ 1041 Warn_RrRtDrSwSta 1500;
BA_REL_ "GenSigTimeoutTime" BU_SG_REL_ APSU SG_ 1041 Warn_RrRtDrSwSta 1500;
BA_REL_ "GenSigTimeoutTime" BU_SG_REL_ RRHV SG_ 1041 Warn_RrRtDrSwSta 1500;
BA_REL_ "GenSigTimeoutTime" BU_SG_REL_ RRPSU SG_ 1041 Warn_RrRtDrSwSta 1500;
BA_REL_ "GenSigTimeoutTime" BU_SG_REL_ RLPSU SG_ 1041 Warn_RrRtDrSwSta 1500;
BA_REL_ "GenSigTimeoutTime" BU_SG_REL_ BLTN_CAM SG_ 1041 Warn_RrRtDrSwSta 1500;
BA_REL_ "GenSigTimeoutTime" BU_SG_REL_ WPC2 SG_ 1041 Warn_RrRtDrSwSta 1500;
BA_ "NetworkRequest" SG_ 1041 Warn_RrRtDrSwSta 0;
BA_ "NetworkRequestHoldingTime" SG_ 1041 Warn_RrRtDrSwSta 5000;
BA_ "Version" SG_ 1041 Warn_RrRtDrSwSta "17.12.00";
BA_ "GenSigSendType" SG_ 1041 Warn_RrRtStBltSwSta 4;
BA_ "UserSigValidity" SG_ 1041 Warn_RrRtStBltSwSta 0;
BA_REL_ "GenSigTimeoutTime" BU_SG_REL_ PSB SG_ 1041 Warn_RrRtStBltSwSta 1500;
BA_REL_ "GenSigTimeoutTime" BU_SG_REL_ APSU SG_ 1041 Warn_RrRtStBltSwSta 1500;
BA_REL_ "GenSigTimeoutTime" BU_SG_REL_ DPSU SG_ 1041 Warn_RrRtStBltSwSta 1500;
BA_REL_ "GenSigTimeoutTime" BU_SG_REL_ RRPSU SG_ 1041 Warn_RrRtStBltSwSta 1500;
BA_ "NetworkRequest" SG_ 1041 Warn_RrRtStBltSwSta 0;
BA_ "NetworkRequestHoldingTime" SG_ 1041 Warn_RrRtStBltSwSta 5000;
BA_ "Version" SG_ 1041 Warn_RrRtStBltSwSta "17.12.00";
BA_ "Description" SG_ 1041 Warn_HoodSwMemorySta "Hood swtich open->close information(memory)



This signal is for oil level warning lamp reset In case hood open->close when IG-OFF, 0x01 sent for 5 sec at next IG-ON";
BA_ "GenSigSendType" SG_ 1041 Warn_HoodSwMemorySta 4;
BA_ "UserSigValidity" SG_ 1041 Warn_HoodSwMemorySta 3;
BA_ "NetworkRequest" SG_ 1041 Warn_HoodSwMemorySta 0;
BA_ "NetworkRequestHoldingTime" SG_ 1041 Warn_HoodSwMemorySta 5000;
BA_ "Version" SG_ 1041 Warn_HoodSwMemorySta "17.12.00";
BA_ "Description" SG_ 1041 Warn_WshrFldSwSta "Washer Fluid Switch Signal

This signal indicates Washer Fluid Switch Signal

0x0:Off/0x1:On";
BA_ "GenSigSendType" SG_ 1041 Warn_WshrFldSwSta 4;
BA_ "UserSigValidity" SG_ 1041 Warn_WshrFldSwSta 3;
BA_ "NetworkRequest" SG_ 1041 Warn_WshrFldSwSta 0;
BA_ "NetworkRequestHoldingTime" SG_ 1041 Warn_WshrFldSwSta 5000;
BA_ "Version" SG_ 1041 Warn_WshrFldSwSta "21.07.05";
BA_ "Description" SG_ 1041 ICU_Haptic_OPT "Steering Wheel Haptic Warning Option Infomation (From ICU)";
BA_ "GenSigSendType" SG_ 1041 ICU_Haptic_OPT 4;
BA_ "UserSigValidity" SG_ 1041 ICU_Haptic_OPT 0;
BA_ "NetworkRequest" SG_ 1041 ICU_Haptic_OPT 0;
BA_ "NetworkRequestHoldingTime" SG_ 1041 ICU_Haptic_OPT 5000;
BA_ "Version" SG_ 1041 ICU_Haptic_OPT "18.07.07";
BA_ "GenMsgSendType" BO_ 1043 0;
BA_ "Description" SG_ 1043 ICU_Crc4Val "The data area for CRC calculation is based on the data length (DLC) of the message DB.

The CRC shall be calculated over the entire data block (excluding the CRC bytes) including the user data, alive counter and Data ID 

 

- CRC Polynomial (0x1D) , Initial Value : 0x00, XOR value : 0xFF, Data ID Mode : Both, Data ID : Message ID + 0xF800 

- The initial value is for CRC calculation and the message should be sent with the calculated result value. 

The mathematical expression to 8 bit CRC polynomial is given here. G(x) = x8 + x4 + x3 + x2 + 1";
BA_ "GenSigSendType" SG_ 1043 ICU_Crc4Val 4;
BA_ "GenSigStartValue" SG_ 1043 ICU_Crc4Val 255;
BA_ "UserSigValidity" SG_ 1043 ICU_Crc4Val 0;
BA_ "Version" SG_ 1043 ICU_Crc4Val "18.11.08";
BA_ "Description" SG_ 1043 Lamp_TrnSigLmpRtActiveSt "Turn Signal Lamp Blink Info";
BA_ "GenSigSendType" SG_ 1043 Lamp_TrnSigLmpRtActiveSt 4;
BA_ "UserSigValidity" SG_ 1043 Lamp_TrnSigLmpRtActiveSt 0;
BA_ "NetworkRequest" SG_ 1043 Lamp_TrnSigLmpRtActiveSt 0;
BA_ "NetworkRequestHoldingTime" SG_ 1043 Lamp_TrnSigLmpRtActiveSt 5000;
BA_ "Version" SG_ 1043 Lamp_TrnSigLmpRtActiveSt "19.11.00";
BA_ "Description" SG_ 1043 ICU_AlvCnt4Val "For the first transmission request for a data element the counter shall be initialized with 0 and shall be incremented by 1

for every subsequent send request. When the counter reaches the maximum value(0xE), then it shall restart with 0 for the next send request";
BA_ "GenSigSendType" SG_ 1043 ICU_AlvCnt4Val 4;
BA_ "UserSigValidity" SG_ 1043 ICU_AlvCnt4Val 0;
BA_ "Version" SG_ 1043 ICU_AlvCnt4Val "18.11.08";
BA_ "GenSigSendType" SG_ 1043 ExtLamp_HzrdSwSta 4;
BA_ "UserSigValidity" SG_ 1043 ExtLamp_HzrdSwSta 0;
BA_ "NetworkRequest" SG_ 1043 ExtLamp_HzrdSwSta 0;
BA_ "NetworkRequestHoldingTime" SG_ 1043 ExtLamp_HzrdSwSta 5000;
BA_ "Version" SG_ 1043 ExtLamp_HzrdSwSta "17.12.00";
BA_ "Description" SG_ 1043 IntLamp_InlTailLmpSta "-(Old)C_INTTail_Act";
BA_ "GenSigSendType" SG_ 1043 IntLamp_InlTailLmpSta 4;
BA_ "UserSigValidity" SG_ 1043 IntLamp_InlTailLmpSta 0;
BA_REL_ "GenSigTimeoutTime" BU_SG_REL_ SWRC SG_ 1043 IntLamp_InlTailLmpSta 1500;
BA_REL_ "GenSigTimeoutTime" BU_SG_REL_ BLTN_CAM SG_ 1043 IntLamp_InlTailLmpSta 1500;
BA_REL_ "GenSigTimeoutTime" BU_SG_REL_ WPC2 SG_ 1043 IntLamp_InlTailLmpSta 1500;
BA_ "NetworkRequest" SG_ 1043 IntLamp_InlTailLmpSta 0;
BA_ "NetworkRequestHoldingTime" SG_ 1043 IntLamp_InlTailLmpSta 5000;
BA_ "Version" SG_ 1043 IntLamp_InlTailLmpSta "17.12.00";
BA_ "Description" SG_ 1043 Lamp_LedHdLmpSta "This signal is LED headlamp status inform whether LED fail or not which is regulation of ECE, Domestic.



If LED H/Lamp detects LED failure then a cluster shall be turn on to 'LED' indicator in the display panel and It should be to display the words 'Check LED Head Lamp!' on the LCD panel in the cluster module.

 

If LED H/Lamp detects FAN failure then a cluster shall be turn on 'LED' indicator in the display panel and It should be to display the words 'Check LED Head Lamp¡¯s FAN!' on the LCD panel in the cluster module.('LED' Indicator not blink)



1) Priority is higher LED failure than FAN failure.

2) 'LED' indicator off when Normal Conditions.";
BA_ "GenSigSendType" SG_ 1043 Lamp_LedHdLmpSta 4;
BA_ "UserSigValidity" SG_ 1043 Lamp_LedHdLmpSta 3;
BA_ "NetworkRequest" SG_ 1043 Lamp_LedHdLmpSta 0;
BA_ "NetworkRequestHoldingTime" SG_ 1043 Lamp_LedHdLmpSta 5000;
BA_ "Version" SG_ 1043 Lamp_LedHdLmpSta "17.12.00";
BA_ "Description" SG_ 1043 TrnLmpSeqEnblCmd "Turn Signal Sequential Enable CAN Command";
BA_ "GenSigSendType" SG_ 1043 TrnLmpSeqEnblCmd 4;
BA_ "UserSigValidity" SG_ 1043 TrnLmpSeqEnblCmd 0;
BA_ "NetworkRequest" SG_ 1043 TrnLmpSeqEnblCmd 0;
BA_ "NetworkRequestHoldingTime" SG_ 1043 TrnLmpSeqEnblCmd 5000;
BA_ "Version" SG_ 1043 TrnLmpSeqEnblCmd "20.08.07";
BA_ "GenSigSendType" SG_ 1043 Lamp_TrnSigLmpLftOnReq 4;
BA_ "UserSigValidity" SG_ 1043 Lamp_TrnSigLmpLftOnReq 0;
BA_REL_ "GenSigTimeoutTime" BU_SG_REL_ BLTN_CAM SG_ 1043 Lamp_TrnSigLmpLftOnReq 1500;
BA_ "NetworkRequest" SG_ 1043 Lamp_TrnSigLmpLftOnReq 0;
BA_ "NetworkRequestHoldingTime" SG_ 1043 Lamp_TrnSigLmpLftOnReq 5000;
BA_ "Version" SG_ 1043 Lamp_TrnSigLmpLftOnReq "17.12.05";
BA_ "GenSigSendType" SG_ 1043 Lamp_TrnSigLmpRtOnReq 4;
BA_ "UserSigValidity" SG_ 1043 Lamp_TrnSigLmpRtOnReq 0;
BA_REL_ "GenSigTimeoutTime" BU_SG_REL_ BLTN_CAM SG_ 1043 Lamp_TrnSigLmpRtOnReq 1500;
BA_ "NetworkRequest" SG_ 1043 Lamp_TrnSigLmpRtOnReq 0;
BA_ "NetworkRequestHoldingTime" SG_ 1043 Lamp_TrnSigLmpRtOnReq 5000;
BA_ "Version" SG_ 1043 Lamp_TrnSigLmpRtOnReq "17.12.05";
BA_ "Description" SG_ 1043 Lamp_TrnSigLmpLftActiveSt "Turn Signal Lmap Blink Info";
BA_ "GenSigSendType" SG_ 1043 Lamp_TrnSigLmpLftActiveSt 4;
BA_ "UserSigValidity" SG_ 1043 Lamp_TrnSigLmpLftActiveSt 0;
BA_ "NetworkRequest" SG_ 1043 Lamp_TrnSigLmpLftActiveSt 0;
BA_ "NetworkRequestHoldingTime" SG_ 1043 Lamp_TrnSigLmpLftActiveSt 5000;
BA_ "Version" SG_ 1043 Lamp_TrnSigLmpLftActiveSt "19.11.00";
BA_ "GenMsgSendType" BO_ 1044 0;
BA_ "Description" SG_ 1044 ICU_Crc5Val "The data area for CRC calculation is based on the data length (DLC) of the message DB.

The CRC shall be calculated over the entire data block (excluding the CRC bytes) including the user data, alive counter and Data ID 

 

- CRC Polynomial (0x1D) , Initial Value : 0x00, XOR value : 0xFF, Data ID Mode : Both, Data ID : Message ID + 0xF800 

- The initial value is for CRC calculation and the message should be sent with the calculated result value. 

The mathematical expression to 8 bit CRC polynomial is given here. G(x) = x8 + x4 + x3 + x2 + 1";
BA_ "GenSigSendType" SG_ 1044 ICU_Crc5Val 4;
BA_ "GenSigStartValue" SG_ 1044 ICU_Crc5Val 255;
BA_ "UserSigValidity" SG_ 1044 ICU_Crc5Val 0;
BA_ "Version" SG_ 1044 ICU_Crc5Val "18.11.08";
BA_ "Description" SG_ 1044 ICU_AlvCnt5Val "For the first transmission request for a data element the counter shall be initialized with 0 and shall be incremented by 1

for every subsequent send request. When the counter reaches the maximum value(0xE), then it shall restart with 0 for the next send request";
BA_ "GenSigSendType" SG_ 1044 ICU_AlvCnt5Val 4;
BA_ "UserSigValidity" SG_ 1044 ICU_AlvCnt5Val 0;
BA_ "Version" SG_ 1044 ICU_AlvCnt5Val "18.11.08";
BA_ "Description" SG_ 1044 Trunk_TrnkInReleaseSwSta "-Trunk Inner Release SW";
BA_ "GenSigSendType" SG_ 1044 Trunk_TrnkInReleaseSwSta 4;
BA_ "UserSigValidity" SG_ 1044 Trunk_TrnkInReleaseSwSta 0;
BA_ "NetworkRequest" SG_ 1044 Trunk_TrnkInReleaseSwSta 0;
BA_ "NetworkRequestHoldingTime" SG_ 1044 Trunk_TrnkInReleaseSwSta 5000;
BA_ "Version" SG_ 1044 Trunk_TrnkInReleaseSwSta "17.12.00";
BA_ "Description" SG_ 1044 Trunk_TrnkTlgtOutReleaseSwSta "-(Old)C_TRUNK_LID

-Trunk/Tailgate Outter Release SW";
BA_ "GenSigSendType" SG_ 1044 Trunk_TrnkTlgtOutReleaseSwSta 4;
BA_ "UserSigValidity" SG_ 1044 Trunk_TrnkTlgtOutReleaseSwSta 0;
BA_ "NetworkRequest" SG_ 1044 Trunk_TrnkTlgtOutReleaseSwSta 0;
BA_ "NetworkRequestHoldingTime" SG_ 1044 Trunk_TrnkTlgtOutReleaseSwSta 5000;
BA_ "Version" SG_ 1044 Trunk_TrnkTlgtOutReleaseSwSta "17.12.00";
BA_ "Description" SG_ 1044 Trunk_TrnkTlgtSwSta "Full Lock SW Status Signal



(TailGate/TrunkLid Tpye all)



1. Luggage or Trunkroom Lamp On/Off



2. TailGate/TrunkLid Open Ind in cluster



3. Normal Open SW



  - SW Off: Full Lock(Full Close state)



  - SW On: ^Full Lock";
BA_ "GenSigSendType" SG_ 1044 Trunk_TrnkTlgtSwSta 4;
BA_ "UserSigValidity" SG_ 1044 Trunk_TrnkTlgtSwSta 0;
BA_REL_ "GenSigTimeoutTime" BU_SG_REL_ APSU SG_ 1044 Trunk_TrnkTlgtSwSta 1500;
BA_REL_ "GenSigTimeoutTime" BU_SG_REL_ RLHV SG_ 1044 Trunk_TrnkTlgtSwSta 1500;
BA_REL_ "GenSigTimeoutTime" BU_SG_REL_ RRHV SG_ 1044 Trunk_TrnkTlgtSwSta 1500;
BA_REL_ "GenSigTimeoutTime" BU_SG_REL_ PFSU SG_ 1044 Trunk_TrnkTlgtSwSta 1500;
BA_REL_ "GenSigTimeoutTime" BU_SG_REL_ RRPSU SG_ 1044 Trunk_TrnkTlgtSwSta 1500;
BA_REL_ "GenSigTimeoutTime" BU_SG_REL_ RLPSU SG_ 1044 Trunk_TrnkTlgtSwSta 1500;
BA_REL_ "GenSigTimeoutTime" BU_SG_REL_ BLTN_CAM SG_ 1044 Trunk_TrnkTlgtSwSta 1500;
BA_ "NetworkRequest" SG_ 1044 Trunk_TrnkTlgtSwSta 0;
BA_ "NetworkRequestHoldingTime" SG_ 1044 Trunk_TrnkTlgtSwSta 5000;
BA_ "Version" SG_ 1044 Trunk_TrnkTlgtSwSta "17.12.00";
BA_ "Description" SG_ 1044 Trunk_GlvBxTrnkLkSwSta "- Glove Box Trunk Lock SW";
BA_ "GenSigSendType" SG_ 1044 Trunk_GlvBxTrnkLkSwSta 4;
BA_ "UserSigValidity" SG_ 1044 Trunk_GlvBxTrnkLkSwSta 0;
BA_ "NetworkRequest" SG_ 1044 Trunk_GlvBxTrnkLkSwSta 0;
BA_ "NetworkRequestHoldingTime" SG_ 1044 Trunk_GlvBxTrnkLkSwSta 5000;
BA_ "Version" SG_ 1044 Trunk_GlvBxTrnkLkSwSta "17.12.00";
BA_ "Description" SG_ 1044 Trunk_TlgtFullOpnSwSta "Full Open SW Status Signal



(Power TailGate/TrunkLid Tpye or tailgate latch 2sw type)



* Normal Open SW



  - SW Off: ^Full Open



  - SW On: Full Open(Full Open state)";
BA_ "GenSigSendType" SG_ 1044 Trunk_TlgtFullOpnSwSta 4;
BA_ "UserSigValidity" SG_ 1044 Trunk_TlgtFullOpnSwSta 0;
BA_ "NetworkRequest" SG_ 1044 Trunk_TlgtFullOpnSwSta 0;
BA_ "NetworkRequestHoldingTime" SG_ 1044 Trunk_TlgtFullOpnSwSta 5000;
BA_ "Version" SG_ 1044 Trunk_TlgtFullOpnSwSta "17.12.00";
BA_ "GenSigSendType" SG_ 1044 Trunk_TrnkTlgtReleaseRlySta 4;
BA_ "UserSigValidity" SG_ 1044 Trunk_TrnkTlgtReleaseRlySta 0;
BA_ "NetworkRequest" SG_ 1044 Trunk_TrnkTlgtReleaseRlySta 0;
BA_ "NetworkRequestHoldingTime" SG_ 1044 Trunk_TrnkTlgtReleaseRlySta 5000;
BA_ "Version" SG_ 1044 Trunk_TrnkTlgtReleaseRlySta "17.12.00";
BA_ "Description" SG_ 1044 USM_OneTouchTrnSigFuncSta "This signal is 



- For One Touch Turn Signal Function,



 the advanced version of One Touch triple turn signal



- Communicated with Cluster for setting USM



- Periodic Event Signal to notice current staus to USM of Cluster";
BA_ "GenSigSendType" SG_ 1044 USM_OneTouchTrnSigFuncSta 4;
BA_ "UserSigValidity" SG_ 1044 USM_OneTouchTrnSigFuncSta 0;
BA_ "NetworkRequest" SG_ 1044 USM_OneTouchTrnSigFuncSta 0;
BA_ "NetworkRequestHoldingTime" SG_ 1044 USM_OneTouchTrnSigFuncSta 5000;
BA_ "Version" SG_ 1044 USM_OneTouchTrnSigFuncSta "21.07.05";
BA_ "GenSigSendType" SG_ 1044 DoorLock_DrvDrUnLkSta 4;
BA_ "UserSigValidity" SG_ 1044 DoorLock_DrvDrUnLkSta 0;
BA_ "NetworkRequest" SG_ 1044 DoorLock_DrvDrUnLkSta 0;
BA_ "NetworkRequestHoldingTime" SG_ 1044 DoorLock_DrvDrUnLkSta 5000;
BA_ "Version" SG_ 1044 DoorLock_DrvDrUnLkSta "17.12.00";
BA_ "Description" SG_ 1044 DoorLock_LkOutSta "- Door Lock or Unlock Output State 



0x0 : Off (Door lock/unlock output Off state)



0x1 : On (Door lock/unlock output On state)";
BA_ "GenSigSendType" SG_ 1044 DoorLock_LkOutSta 4;
BA_ "UserSigValidity" SG_ 1044 DoorLock_LkOutSta 0;
BA_ "NetworkRequest" SG_ 1044 DoorLock_LkOutSta 0;
BA_ "NetworkRequestHoldingTime" SG_ 1044 DoorLock_LkOutSta 5000;
BA_ "Version" SG_ 1044 DoorLock_LkOutSta "17.12.00";
BA_ "Description" SG_ 1044 C_CrashUnlockState "Crash Unlock Active State

-0x0:Off

-0x1:Unlock(crash)";
BA_ "GenSigSendType" SG_ 1044 C_CrashUnlockState 4;
BA_ "UserSigValidity" SG_ 1044 C_CrashUnlockState 0;
BA_REL_ "GenSigTimeoutTime" BU_SG_REL_ BLTN_CAM SG_ 1044 C_CrashUnlockState 1500;
BA_ "NetworkRequest" SG_ 1044 C_CrashUnlockState 0;
BA_ "Version" SG_ 1044 C_CrashUnlockState "21.07.05";
BA_ "Description" SG_ 1044 C_AutoLeverManualSW "This signal represents operating status of AT/CVT/DCT Lever Manual Switch";
BA_ "GenSigSendType" SG_ 1044 C_AutoLeverManualSW 4;
BA_ "UserSigValidity" SG_ 1044 C_AutoLeverManualSW 3;
BA_ "Version" SG_ 1044 C_AutoLeverManualSW "19.09.06";
BA_ "GenMsgSendType" BO_ 1048 0;
BA_ "Description" SG_ 1048 ICU_Crc8Val "The data area for CRC calculation is based on the data length (DLC) of the message DB.

The CRC shall be calculated over the entire data block (excluding the CRC bytes) including the user data, alive counter and Data ID 

 

- CRC Polynomial (0x1D) , Initial Value : 0x00, XOR value : 0xFF, Data ID Mode : Both, Data ID : Message ID + 0xF800 

- The initial value is for CRC calculation and the message should be sent with the calculated result value. 

The mathematical expression to 8 bit CRC polynomial is given here. G(x) = x8 + x4 + x3 + x2 + 1";
BA_ "GenSigSendType" SG_ 1048 ICU_Crc8Val 4;
BA_ "GenSigStartValue" SG_ 1048 ICU_Crc8Val 255;
BA_ "UserSigValidity" SG_ 1048 ICU_Crc8Val 0;
BA_ "Version" SG_ 1048 ICU_Crc8Val "18.11.08";
BA_ "Description" SG_ 1048 ICU_AlvCnt8Val "For the first transmission request for a data element the counter shall be initialized with 0 and shall be incremented by 1

for every subsequent send request. When the counter reaches the maximum value(0xE), then it shall restart with 0 for the next send request";
BA_ "GenSigSendType" SG_ 1048 ICU_AlvCnt8Val 4;
BA_ "UserSigValidity" SG_ 1048 ICU_AlvCnt8Val 0;
BA_ "Version" SG_ 1048 ICU_AlvCnt8Val "18.11.08";
BA_ "Description" SG_ 1048 DriveTypeOption "Drive Type Option

This signal is used to determine driver's seat position('Drive Type') about this vehicle.";
BA_ "GenSigSendType" SG_ 1048 DriveTypeOption 4;
BA_ "UserSigValidity" SG_ 1048 DriveTypeOption 0;
BA_REL_ "GenSigTimeoutTime" BU_SG_REL_ APSU SG_ 1048 DriveTypeOption 1500;
BA_REL_ "GenSigTimeoutTime" BU_SG_REL_ SHVU_FR SG_ 1048 DriveTypeOption 1500;
BA_REL_ "GenSigTimeoutTime" BU_SG_REL_ SHVU_RR SG_ 1048 DriveTypeOption 1500;
BA_REL_ "GenSigTimeoutTime" BU_SG_REL_ DPSU SG_ 1048 DriveTypeOption 1500;
BA_REL_ "GenSigTimeoutTime" BU_SG_REL_ DLBCU SG_ 1048 DriveTypeOption 1500;
BA_REL_ "GenSigTimeoutTime" BU_SG_REL_ ATS SG_ 1048 DriveTypeOption 1500;
BA_REL_ "GenSigTimeoutTime" BU_SG_REL_ BLTN_CAM SG_ 1048 DriveTypeOption 1500;
BA_ "NetworkRequest" SG_ 1048 DriveTypeOption 0;
BA_ "NetworkRequestHoldingTime" SG_ 1048 DriveTypeOption 5000;
BA_ "Version" SG_ 1048 DriveTypeOption "17.12.00";
BA_ "Description" SG_ 1048 Warn_RrLftSBRMATSwSta "Rear Left Seated State";
BA_ "GenSigSendType" SG_ 1048 Warn_RrLftSBRMATSwSta 4;
BA_ "UserSigValidity" SG_ 1048 Warn_RrLftSBRMATSwSta 0;
BA_ "NetworkRequest" SG_ 1048 Warn_RrLftSBRMATSwSta 0;
BA_ "NetworkRequestHoldingTime" SG_ 1048 Warn_RrLftSBRMATSwSta 5000;
BA_ "Version" SG_ 1048 Warn_RrLftSBRMATSwSta "17.12.00";
BA_ "Description" SG_ 1048 Warn_RrRhtSBRMATSwSta "Rear Right Seated State";
BA_ "GenSigSendType" SG_ 1048 Warn_RrRhtSBRMATSwSta 4;
BA_ "UserSigValidity" SG_ 1048 Warn_RrRhtSBRMATSwSta 0;
BA_ "NetworkRequest" SG_ 1048 Warn_RrRhtSBRMATSwSta 0;
BA_ "NetworkRequestHoldingTime" SG_ 1048 Warn_RrRhtSBRMATSwSta 5000;
BA_ "Version" SG_ 1048 Warn_RrRhtSBRMATSwSta "17.12.00";
BA_ "Description" SG_ 1048 Lamp_FootLampOnReq "Foot Lamp Command";
BA_ "GenSigSendType" SG_ 1048 Lamp_FootLampOnReq 4;
BA_ "UserSigValidity" SG_ 1048 Lamp_FootLampOnReq 0;
BA_ "NetworkRequest" SG_ 1048 Lamp_FootLampOnReq 0;
BA_ "NetworkRequestHoldingTime" SG_ 1048 Lamp_FootLampOnReq 5000;
BA_ "Version" SG_ 1048 Lamp_FootLampOnReq "17.12.00";
BA_ "Description" SG_ 1048 Lamp_MoodLampOnReq "Mood lamp command";
BA_ "GenSigSendType" SG_ 1048 Lamp_MoodLampOnReq 4;
BA_ "UserSigValidity" SG_ 1048 Lamp_MoodLampOnReq 0;
BA_ "NetworkRequest" SG_ 1048 Lamp_MoodLampOnReq 0;
BA_ "NetworkRequestHoldingTime" SG_ 1048 Lamp_MoodLampOnReq 5000;
BA_ "Version" SG_ 1048 Lamp_MoodLampOnReq "21.07.05";
BA_ "Description" SG_ 1048 ICU_PowerAutoCutModSta "ICU Delivery Mode State";
BA_ "GenSigSendType" SG_ 1048 ICU_PowerAutoCutModSta 4;
BA_ "UserSigValidity" SG_ 1048 ICU_PowerAutoCutModSta 3;
BA_REL_ "GenSigTimeoutTime" BU_SG_REL_ APSU SG_ 1048 ICU_PowerAutoCutModSta 1500;
BA_REL_ "GenSigTimeoutTime" BU_SG_REL_ RLHV SG_ 1048 ICU_PowerAutoCutModSta 1500;
BA_REL_ "GenSigTimeoutTime" BU_SG_REL_ RRHV SG_ 1048 ICU_PowerAutoCutModSta 1500;
BA_REL_ "GenSigTimeoutTime" BU_SG_REL_ DPSU SG_ 1048 ICU_PowerAutoCutModSta 1500;
BA_REL_ "GenSigTimeoutTime" BU_SG_REL_ RRPSU SG_ 1048 ICU_PowerAutoCutModSta 1500;
BA_REL_ "GenSigTimeoutTime" BU_SG_REL_ RLPSU SG_ 1048 ICU_PowerAutoCutModSta 1500;
BA_REL_ "GenSigTimeoutTime" BU_SG_REL_ BLTN_CAM SG_ 1048 ICU_PowerAutoCutModSta 1500;
BA_ "Version" SG_ 1048 ICU_PowerAutoCutModSta "17.12.00";
BA_ "Description" SG_ 1048 ICU_SoCBattStaMsgReq "Determine if soc level is warning or alert.";
BA_ "GenSigSendType" SG_ 1048 ICU_SoCBattStaMsgReq 4;
BA_ "GenSigStartValue" SG_ 1048 ICU_SoCBattStaMsgReq 3;
BA_ "UserSigValidity" SG_ 1048 ICU_SoCBattStaMsgReq 0;
BA_ "Version" SG_ 1048 ICU_SoCBattStaMsgReq "17.12.00";
BA_ "Description" SG_ 1048 C_1stCTRSeatBeltSW "1st Center Seat Belt Switch Status";
BA_ "GenSigSendType" SG_ 1048 C_1stCTRSeatBeltSW 4;
BA_ "UserSigValidity" SG_ 1048 C_1stCTRSeatBeltSW 0;
BA_ "NetworkRequest" SG_ 1048 C_1stCTRSeatBeltSW 0;
BA_ "NetworkRequestHoldingTime" SG_ 1048 C_1stCTRSeatBeltSW 5000;
BA_ "Version" SG_ 1048 C_1stCTRSeatBeltSW "19.04.06";
BA_ "Description" SG_ 1048 Brake_SwSta_ICU "Brake Switch Status";
BA_ "GenSigSendType" SG_ 1048 Brake_SwSta_ICU 4;
BA_ "UserSigValidity" SG_ 1048 Brake_SwSta_ICU 0;
BA_ "NetworkRequest" SG_ 1048 Brake_SwSta_ICU 0;
BA_ "NetworkRequestHoldingTime" SG_ 1048 Brake_SwSta_ICU 5000;
BA_ "Version" SG_ 1048 Brake_SwSta_ICU "21.07.05";
BA_ "Description" SG_ 1048 C_1stCTRSBRMatSw "1st Center Seated State



-Default value: 0x0 (¹ÌÅ¾½Â)

-Initial value: 0x0 (¹ÌÅ¾½Â)

-Timeout value: 0x0 (¹ÌÅ¾½Â)";
BA_ "GenSigSendType" SG_ 1048 C_1stCTRSBRMatSw 4;
BA_ "UserSigValidity" SG_ 1048 C_1stCTRSBRMatSw 0;
BA_ "NetworkRequest" SG_ 1048 C_1stCTRSBRMatSw 0;
BA_ "NetworkRequestHoldingTime" SG_ 1048 C_1stCTRSBRMatSw 5000;
BA_ "Version" SG_ 1048 C_1stCTRSBRMatSw "19.04.06";
BA_ "Description" SG_ 1048 C_3rdRCSeatBeltSW "3rd Rear Center Seat Belt Switch Status";
BA_ "GenSigSendType" SG_ 1048 C_3rdRCSeatBeltSW 4;
BA_ "UserSigValidity" SG_ 1048 C_3rdRCSeatBeltSW 0;
BA_REL_ "GenSigTimeoutTime" BU_SG_REL_ ARS SG_ 1048 C_3rdRCSeatBeltSW 1500;
BA_REL_ "GenSigTimeoutTime" BU_SG_REL_ RRPSU SG_ 1048 C_3rdRCSeatBeltSW 1500;
BA_REL_ "GenSigTimeoutTime" BU_SG_REL_ RLPSU SG_ 1048 C_3rdRCSeatBeltSW 1500;
BA_REL_ "GenSigTimeoutTime" BU_SG_REL_ WPC2 SG_ 1048 C_3rdRCSeatBeltSW 1500;
BA_ "NetworkRequest" SG_ 1048 C_3rdRCSeatBeltSW 0;
BA_ "NetworkRequestHoldingTime" SG_ 1048 C_3rdRCSeatBeltSW 5000;
BA_ "Version" SG_ 1048 C_3rdRCSeatBeltSW "18.03.04";
BA_ "Description" SG_ 1048 C_3rdRRSBRMatSw "3rd Rear Right Seated State



-Default value: 0x0 (¹ÌÅ¾½Â)

-Initial value: 0x0 (¹ÌÅ¾½Â)

-Timeout value: 0x0 (¹ÌÅ¾½Â)";
BA_ "GenSigSendType" SG_ 1048 C_3rdRRSBRMatSw 4;
BA_ "UserSigValidity" SG_ 1048 C_3rdRRSBRMatSw 0;
BA_REL_ "GenSigTimeoutTime" BU_SG_REL_ ARS SG_ 1048 C_3rdRRSBRMatSw 1500;
BA_REL_ "GenSigTimeoutTime" BU_SG_REL_ RRPSU SG_ 1048 C_3rdRRSBRMatSw 1500;
BA_REL_ "GenSigTimeoutTime" BU_SG_REL_ RLPSU SG_ 1048 C_3rdRRSBRMatSw 1500;
BA_REL_ "GenSigTimeoutTime" BU_SG_REL_ WPC2 SG_ 1048 C_3rdRRSBRMatSw 1500;
BA_ "NetworkRequest" SG_ 1048 C_3rdRRSBRMatSw 0;
BA_ "NetworkRequestHoldingTime" SG_ 1048 C_3rdRRSBRMatSw 5000;
BA_ "Version" SG_ 1048 C_3rdRRSBRMatSw "18.03.04";
BA_ "Description" SG_ 1048 C_3rdRLSBRMatSw "3rd Rear Left Seated State



-Default value: 0x0 (¹ÌÅ¾½Â)

-Initial value: 0x0 (¹ÌÅ¾½Â)

-Timeout value: 0x0 (¹ÌÅ¾½Â)";
BA_ "GenSigSendType" SG_ 1048 C_3rdRLSBRMatSw 4;
BA_ "UserSigValidity" SG_ 1048 C_3rdRLSBRMatSw 0;
BA_REL_ "GenSigTimeoutTime" BU_SG_REL_ ARS SG_ 1048 C_3rdRLSBRMatSw 1500;
BA_REL_ "GenSigTimeoutTime" BU_SG_REL_ RLPSU SG_ 1048 C_3rdRLSBRMatSw 1500;
BA_REL_ "GenSigTimeoutTime" BU_SG_REL_ WPC2 SG_ 1048 C_3rdRLSBRMatSw 1500;
BA_ "NetworkRequest" SG_ 1048 C_3rdRLSBRMatSw 0;
BA_ "NetworkRequestHoldingTime" SG_ 1048 C_3rdRLSBRMatSw 5000;
BA_ "Version" SG_ 1048 C_3rdRLSBRMatSw "18.03.04";
BA_ "Description" SG_ 1048 C_3rdRRSeatBeltSW "3rd Rear Right Seat Belt Switch Status";
BA_ "GenSigSendType" SG_ 1048 C_3rdRRSeatBeltSW 4;
BA_ "UserSigValidity" SG_ 1048 C_3rdRRSeatBeltSW 0;
BA_REL_ "GenSigTimeoutTime" BU_SG_REL_ ARS SG_ 1048 C_3rdRRSeatBeltSW 1500;
BA_REL_ "GenSigTimeoutTime" BU_SG_REL_ RRPSU SG_ 1048 C_3rdRRSeatBeltSW 1500;
BA_REL_ "GenSigTimeoutTime" BU_SG_REL_ RLPSU SG_ 1048 C_3rdRRSeatBeltSW 1500;
BA_REL_ "GenSigTimeoutTime" BU_SG_REL_ WPC2 SG_ 1048 C_3rdRRSeatBeltSW 1500;
BA_ "NetworkRequest" SG_ 1048 C_3rdRRSeatBeltSW 0;
BA_ "NetworkRequestHoldingTime" SG_ 1048 C_3rdRRSeatBeltSW 5000;
BA_ "Version" SG_ 1048 C_3rdRRSeatBeltSW "18.03.04";
BA_ "Description" SG_ 1048 C_3rdRLSeatBeltSW "3rd Rear Left Seat Belt Switch Status";
BA_ "GenSigSendType" SG_ 1048 C_3rdRLSeatBeltSW 4;
BA_ "UserSigValidity" SG_ 1048 C_3rdRLSeatBeltSW 0;
BA_REL_ "GenSigTimeoutTime" BU_SG_REL_ ARS SG_ 1048 C_3rdRLSeatBeltSW 1500;
BA_REL_ "GenSigTimeoutTime" BU_SG_REL_ RRPSU SG_ 1048 C_3rdRLSeatBeltSW 1500;
BA_REL_ "GenSigTimeoutTime" BU_SG_REL_ RLPSU SG_ 1048 C_3rdRLSeatBeltSW 1500;
BA_REL_ "GenSigTimeoutTime" BU_SG_REL_ WPC2 SG_ 1048 C_3rdRLSeatBeltSW 1500;
BA_ "NetworkRequest" SG_ 1048 C_3rdRLSeatBeltSW 0;
BA_ "NetworkRequestHoldingTime" SG_ 1048 C_3rdRLSeatBeltSW 5000;
BA_ "Version" SG_ 1048 C_3rdRLSeatBeltSW "18.03.04";
BA_ "Description" SG_ 1048 HSWS_SysWrngSta_ICU "0x0 : Normal

0x1 : System Fail

0x2 : Reserved

0x3 : Invalid";
BA_ "GenSigSendType" SG_ 1048 HSWS_SysWrngSta_ICU 4;
BA_ "UserSigValidity" SG_ 1048 HSWS_SysWrngSta_ICU 4;
BA_ "Version" SG_ 1048 HSWS_SysWrngSta_ICU "17.12.00";
BA_ "GenMsgSendType" BO_ 1040 0;
BA_ "Description" SG_ 1040 ICU_Crc10Val "The data area for CRC calculation is based on the data length (DLC) of the message DB.

The CRC shall be calculated over the entire data block (excluding the CRC bytes) including the user data, alive counter and Data ID 

 

- CRC Polynomial (0x1D) , Initial Value : 0x00, XOR value : 0xFF, Data ID Mode : Both, Data ID : Message ID + 0xF800 

- The initial value is for CRC calculation and the message should be sent with the calculated result value. 

The mathematical expression to 8 bit CRC polynomial is given here. G(x) = x8 + x4 + x3 + x2 + 1";
BA_ "GenSigSendType" SG_ 1040 ICU_Crc10Val 4;
BA_ "GenSigStartValue" SG_ 1040 ICU_Crc10Val 255;
BA_ "UserSigValidity" SG_ 1040 ICU_Crc10Val 0;
BA_ "Version" SG_ 1040 ICU_Crc10Val "18.11.08";
BA_ "Description" SG_ 1040 BmsFailWarning "If a 12V lithium battery fails, it is a signal that is sent according to the type of fault";
BA_ "GenSigSendType" SG_ 1040 BmsFailWarning 4;
BA_ "UserSigValidity" SG_ 1040 BmsFailWarning 0;
BA_ "Version" SG_ 1040 BmsFailWarning "21.03.11";
BA_ "Description" SG_ 1040 ICU_AlvCnt10Val "For the first transmission request for a data element the counter shall be initialized with 0 and shall be incremented by 1

for every subsequent send request. When the counter reaches the maximum value(0xE), then it shall restart with 0 for the next send request";
BA_ "GenSigSendType" SG_ 1040 ICU_AlvCnt10Val 4;
BA_ "UserSigValidity" SG_ 1040 ICU_AlvCnt10Val 0;
BA_ "Version" SG_ 1040 ICU_AlvCnt10Val "18.11.08";
BA_ "Description" SG_ 1040 ICU_BS2SoC "This signal is battery State of Charge as calculated by battery sensor.";
BA_ "GenSigSendType" SG_ 1040 ICU_BS2SoC 4;
BA_ "GenSigStartValue" SG_ 1040 ICU_BS2SoC 255;
BA_ "UserSigValidity" SG_ 1040 ICU_BS2SoC 3;
BA_REL_ "GenSigTimeoutTime" BU_SG_REL_ BLTN_CAM SG_ 1040 ICU_BS2SoC 1500;
BA_ "Version" SG_ 1040 ICU_BS2SoC "21.07.05";
BA_ "Description" SG_ 1040 ICU_BS2NCap "Nominal capacity";
BA_ "GenSigSendType" SG_ 1040 ICU_BS2NCap 4;
BA_ "GenSigStartValue" SG_ 1040 ICU_BS2NCap 255;
BA_ "UserSigValidity" SG_ 1040 ICU_BS2NCap 3;
BA_ "Version" SG_ 1040 ICU_BS2NCap "21.07.05";
BA_ "Description" SG_ 1040 ICU_BS2OpnCirVol "Last open circuit voltage";
BA_ "GenSigSendType" SG_ 1040 ICU_BS2OpnCirVol 4;
BA_ "GenSigStartValue" SG_ 1040 ICU_BS2OpnCirVol 4095;
BA_ "UserSigValidity" SG_ 1040 ICU_BS2OpnCirVol 3;
BA_ "Version" SG_ 1040 ICU_BS2OpnCirVol "21.07.05";
BA_ "Description" SG_ 1040 ICU_BS2_FSOC "This signal indicates whether the state of SOC signal is fault or not";
BA_ "GenSigSendType" SG_ 1040 ICU_BS2_FSOC 4;
BA_ "GenSigStartValue" SG_ 1040 ICU_BS2_FSOC 1;
BA_ "UserSigValidity" SG_ 1040 ICU_BS2_FSOC 3;
BA_ "Version" SG_ 1040 ICU_BS2_FSOC "18.08.03";
BA_ "Description" SG_ 1040 ICU_BS2_FSOH "This signal indicates whether the state of SOH signal is fault or not";
BA_ "GenSigSendType" SG_ 1040 ICU_BS2_FSOH 4;
BA_ "GenSigStartValue" SG_ 1040 ICU_BS2_FSOH 1;
BA_ "UserSigValidity" SG_ 1040 ICU_BS2_FSOH 3;
BA_ "Version" SG_ 1040 ICU_BS2_FSOH "18.08.03";
BA_ "Description" SG_ 1040 ICU_BS2_FSOF "This signal indicates whether the state of SOF signal is fault or not";
BA_ "GenSigSendType" SG_ 1040 ICU_BS2_FSOF 4;
BA_ "GenSigStartValue" SG_ 1040 ICU_BS2_FSOF 1;
BA_ "UserSigValidity" SG_ 1040 ICU_BS2_FSOF 3;
BA_ "Version" SG_ 1040 ICU_BS2_FSOF "18.08.03";
BA_ "Description" SG_ 1040 ICU_BS2_FQSTAT "This signal indicates whether quiescent current is high or not compared to pre-defined value";
BA_ "GenSigSendType" SG_ 1040 ICU_BS2_FQSTAT 4;
BA_ "GenSigStartValue" SG_ 1040 ICU_BS2_FQSTAT 1;
BA_ "UserSigValidity" SG_ 1040 ICU_BS2_FQSTAT 3;
BA_ "Version" SG_ 1040 ICU_BS2_FQSTAT "18.08.03";
BA_ "Description" SG_ 1040 ICU_BS2SoH "This signal is battery State of Health(SOH) as calculated by battery sensor.



This value shows reduction rate of nominal capacity.



This value can be used for diagnosis information of application system.";
BA_ "GenSigSendType" SG_ 1040 ICU_BS2SoH 4;
BA_ "GenSigStartValue" SG_ 1040 ICU_BS2SoH 255;
BA_ "UserSigValidity" SG_ 1040 ICU_BS2SoH 3;
BA_ "Version" SG_ 1040 ICU_BS2SoH "21.07.05";
BA_ "Description" SG_ 1040 ICU_BS2SoF "This signal is battery State of Function(SOF) as calculated by battery sensor.



This value shows information about the battery ability to crank the engine (both of warm & cold cranking).



This value is prediction value of the minimum voltage for the next cranking.";
BA_ "GenSigSendType" SG_ 1040 ICU_BS2SoF 4;
BA_ "GenSigStartValue" SG_ 1040 ICU_BS2SoF 255;
BA_ "UserSigValidity" SG_ 1040 ICU_BS2SoF 3;
BA_ "Version" SG_ 1040 ICU_BS2SoF "21.07.05";
BA_ "GenMsgSendType" BO_ 1029 0;
BA_ "Description" SG_ 1029 ICU_Crc12Val "The data area for CRC calculation is based on the data length (DLC) of the message DB.

The CRC shall be calculated over the entire data block (excluding the CRC bytes) including the user data, alive counter and Data ID 

 

- CRC Polynomial (0x1D) , Initial Value : 0x00, XOR value : 0xFF, Data ID Mode : Both, Data ID : Message ID + 0xF800 

- The initial value is for CRC calculation and the message should be sent with the calculated result value. 

The mathematical expression to 8 bit CRC polynomial is given here. G(x) = x8 + x4 + x3 + x2 + 1";
BA_ "GenSigSendType" SG_ 1029 ICU_Crc12Val 4;
BA_ "GenSigStartValue" SG_ 1029 ICU_Crc12Val 255;
BA_ "UserSigValidity" SG_ 1029 ICU_Crc12Val 0;
BA_ "Version" SG_ 1029 ICU_Crc12Val "18.11.08";
BA_ "Description" SG_ 1029 Warn_ChaDrSwRrSta "Rear Charging Door Open Switch";
BA_ "GenSigSendType" SG_ 1029 Warn_ChaDrSwRrSta 4;
BA_ "UserSigValidity" SG_ 1029 Warn_ChaDrSwRrSta 7;
BA_ "Version" SG_ 1029 Warn_ChaDrSwRrSta "18.08.12";
BA_ "Description" SG_ 1029 ICU_AlvCnt12Val "For the first transmission request for a data element the counter shall be initialized with 0 and shall be incremented by 1

for every subsequent send request. When the counter reaches the maximum value(0xE), then it shall restart with 0 for the next send request";
BA_ "GenSigSendType" SG_ 1029 ICU_AlvCnt12Val 4;
BA_ "UserSigValidity" SG_ 1029 ICU_AlvCnt12Val 0;
BA_ "Version" SG_ 1029 ICU_AlvCnt12Val "18.11.08";
BA_ "Description" SG_ 1029 DoorLock_CtrlDrLkSwSta_ICU "Central Door Lock Switch State

(DRV or AST or RL or RR Door trim)";
BA_ "GenSigSendType" SG_ 1029 DoorLock_CtrlDrLkSwSta_ICU 4;
BA_ "UserSigValidity" SG_ 1029 DoorLock_CtrlDrLkSwSta_ICU 0;
BA_ "NetworkRequest" SG_ 1029 DoorLock_CtrlDrLkSwSta_ICU 0;
BA_ "NetworkRequestHoldingTime" SG_ 1029 DoorLock_CtrlDrLkSwSta_ICU 5000;
BA_ "Version" SG_ 1029 DoorLock_CtrlDrLkSwSta_ICU "19.07.01";
BA_ "Description" SG_ 1029 DoorLock_CtrlDrUnLkSwSta_ICU "Central Door Unlock Switch State

(DRV or AST or RL or RR Door trim)";
BA_ "GenSigSendType" SG_ 1029 DoorLock_CtrlDrUnLkSwSta_ICU 4;
BA_ "UserSigValidity" SG_ 1029 DoorLock_CtrlDrUnLkSwSta_ICU 0;
BA_ "NetworkRequest" SG_ 1029 DoorLock_CtrlDrUnLkSwSta_ICU 0;
BA_ "NetworkRequestHoldingTime" SG_ 1029 DoorLock_CtrlDrUnLkSwSta_ICU 5000;
BA_ "Version" SG_ 1029 DoorLock_CtrlDrUnLkSwSta_ICU "19.07.01";
BA_ "Description" SG_ 1029 DoorLock_CtrlDrLkUnLkSwSta_ICU "Central Door Lock/Unlock Switch State

(C/PAD, Integrated & self return type)";
BA_ "GenSigSendType" SG_ 1029 DoorLock_CtrlDrLkUnLkSwSta_ICU 4;
BA_ "UserSigValidity" SG_ 1029 DoorLock_CtrlDrLkUnLkSwSta_ICU 0;
BA_ "NetworkRequest" SG_ 1029 DoorLock_CtrlDrLkUnLkSwSta_ICU 0;
BA_ "NetworkRequestHoldingTime" SG_ 1029 DoorLock_CtrlDrLkUnLkSwSta_ICU 5000;
BA_ "Version" SG_ 1029 DoorLock_CtrlDrLkUnLkSwSta_ICU "19.07.01";
BA_ "Description" SG_ 1029 HEV_IGN3On_Req "HEV IGN3 Relay Control Request State

0x0:Default (IG3 Off)

0x1:IG3 On (by BMS)

0x2:IG3 On (by IG1 On)

0x3:IG3 On (by AVNT)";
BA_ "GenSigSendType" SG_ 1029 HEV_IGN3On_Req 4;
BA_ "UserSigValidity" SG_ 1029 HEV_IGN3On_Req 7;
BA_ "Version" SG_ 1029 HEV_IGN3On_Req "20.04.04";
BA_ "Description" SG_ 1029 AutoLtOpt "Auto Light »ç¾ç Àû¿ë ¿©ºÎ ¹× Àû¿ë ¿É¼Ç Á¤º¸ Ãâ·Â (¹ÌÀû¿ë/Àû¿ë)";
BA_ "GenSigSendType" SG_ 1029 AutoLtOpt 4;
BA_ "UserSigValidity" SG_ 1029 AutoLtOpt 0;
BA_ "Version" SG_ 1029 AutoLtOpt "20.09.00";
BA_ "Description" SG_ 1029 ICU_IGN3On_ReqState_New "IGN3 Relay Control Request Unit State For EV/ PHEV Vehicle";
BA_ "GenSigSendType" SG_ 1029 ICU_IGN3On_ReqState_New 4;
BA_ "UserSigValidity" SG_ 1029 ICU_IGN3On_ReqState_New 7;
BA_REL_ "GenSigTimeoutTime" BU_SG_REL_ APSU SG_ 1029 ICU_IGN3On_ReqState_New 1500;
BA_REL_ "GenSigTimeoutTime" BU_SG_REL_ RLHV SG_ 1029 ICU_IGN3On_ReqState_New 1500;
BA_REL_ "GenSigTimeoutTime" BU_SG_REL_ RRHV SG_ 1029 ICU_IGN3On_ReqState_New 1500;
BA_REL_ "GenSigTimeoutTime" BU_SG_REL_ SHVU_FR SG_ 1029 ICU_IGN3On_ReqState_New 1500;
BA_REL_ "GenSigTimeoutTime" BU_SG_REL_ SHVU_RR SG_ 1029 ICU_IGN3On_ReqState_New 1500;
BA_REL_ "GenSigTimeoutTime" BU_SG_REL_ DPSU SG_ 1029 ICU_IGN3On_ReqState_New 1500;
BA_REL_ "GenSigTimeoutTime" BU_SG_REL_ DLBCU SG_ 1029 ICU_IGN3On_ReqState_New 1500;
BA_REL_ "GenSigTimeoutTime" BU_SG_REL_ PFSU SG_ 1029 ICU_IGN3On_ReqState_New 1500;
BA_REL_ "GenSigTimeoutTime" BU_SG_REL_ RRPSU SG_ 1029 ICU_IGN3On_ReqState_New 1500;
BA_REL_ "GenSigTimeoutTime" BU_SG_REL_ RLPSU SG_ 1029 ICU_IGN3On_ReqState_New 1500;
BA_ "Version" SG_ 1029 ICU_IGN3On_ReqState_New "21.07.05";
BA_ "Description" SG_ 1029 ICU_BattMngAlert "This signal is for battery discharge warning.

1bit : Hazard

2bit : Tail

3bit~8bit : Reserved";
BA_ "GenSigSendType" SG_ 1029 ICU_BattMngAlert 4;
BA_ "UserSigValidity" SG_ 1029 ICU_BattMngAlert 0;
BA_ "Version" SG_ 1029 ICU_BattMngAlert "21.07.05";
BA_ "Description" SG_ 1029 HLmpLoHiOptLtSrcTyp "Head Low and High Lamp Option and Light Source Type";
BA_ "GenSigSendType" SG_ 1029 HLmpLoHiOptLtSrcTyp 4;
BA_ "UserSigValidity" SG_ 1029 HLmpLoHiOptLtSrcTyp 0;
BA_ "Version" SG_ 1029 HLmpLoHiOptLtSrcTyp "20.09.00";
BA_ "Description" SG_ 1029 Warn_ChaDrSwFrtSta "Front Charging Door Open Switch";
BA_ "GenSigSendType" SG_ 1029 Warn_ChaDrSwFrtSta 4;
BA_ "UserSigValidity" SG_ 1029 Warn_ChaDrSwFrtSta 7;
BA_ "Version" SG_ 1029 Warn_ChaDrSwFrtSta "18.08.12";
BA_ "GenMsgSendType" BO_ 1067 0;
BA_ "Description" SG_ 1067 SCM_SWVerMajor1 "Indicate the SCM software version as follows:

- The software version is displayed in three digits.

- The Major and Minor digits are separated by '.'

- Signal values are transmitted to ASCII codes.



¡Ø Example

SCM_SWVerMajor1 : 0x41 (HEX) -> ASCII CODE : 'A' 

SCM_SWVerMinor1 : 0x30 (HEX) -> ASCII CODE : '0'

SCM_SWVerMinor2 : 0x33 (HEX) -> ASCII CODE : '3'

=> SCM S/W Ver is displayed 'A.03'";
BA_ "GenSigSendType" SG_ 1067 SCM_SWVerMajor1 4;
BA_ "UserSigValidity" SG_ 1067 SCM_SWVerMajor1 0;
BA_REL_ "GenSigTimeoutTime" BU_SG_REL_ CGW_CCU SG_ 1067 SCM_SWVerMajor1 1500;
BA_ "Version" SG_ 1067 SCM_SWVerMajor1 "20.12.04";
BA_ "Description" SG_ 1067 SCM_SWVerMinor1 "Indicate the SCM software version as follows:

- The software version is displayed in three digits.

- The Major and Minor digits are separated by '.'

- Signal values are transmitted to ASCII codes.



¡Ø Example

SCM_SWVerMajor1 : 0x41 (HEX) -> ASCII CODE : 'A' 

SCM_SWVerMinor1 : 0x30 (HEX) -> ASCII CODE : '0'

SCM_SWVerMinor2 : 0x33 (HEX) -> ASCII CODE : '3'

=> SCM S/W Ver is displayed 'A.03'";
BA_ "GenSigSendType" SG_ 1067 SCM_SWVerMinor1 4;
BA_ "UserSigValidity" SG_ 1067 SCM_SWVerMinor1 0;
BA_REL_ "GenSigTimeoutTime" BU_SG_REL_ CGW_CCU SG_ 1067 SCM_SWVerMinor1 1500;
BA_ "Version" SG_ 1067 SCM_SWVerMinor1 "18.10.06";
BA_ "Description" SG_ 1067 SCM_SWVerMinor2 "Indicate the SCM software version as follows:

- The software version is displayed in three digits.

- The Major and Minor digits are separated by '.'

- Signal values are transmitted to ASCII codes.



¡Ø Example

SCM_SWVerMajor1 : 0x41 (HEX) -> ASCII CODE : 'A' 

SCM_SWVerMinor1 : 0x30 (HEX) -> ASCII CODE : '0'

SCM_SWVerMinor2 : 0x33 (HEX) -> ASCII CODE : '3'

=> SCM S/W Ver is displayed 'A.03'";
BA_ "GenSigSendType" SG_ 1067 SCM_SWVerMinor2 4;
BA_ "UserSigValidity" SG_ 1067 SCM_SWVerMinor2 0;
BA_REL_ "GenSigTimeoutTime" BU_SG_REL_ CGW_CCU SG_ 1067 SCM_SWVerMinor2 1500;
BA_ "Version" SG_ 1067 SCM_SWVerMinor2 "18.10.06";
VAL_ 1030 APSM_SWVerMajor1 0 "0x0x0~0x7F:ASCII Code Value (HEX)" 127 "0x0x0~0x7F:ASCII Code Value (HEX)" ;
VAL_ 1030 APSM_SWVerMinor1 0 "0x0x0~0x7F:ASCII Code Value (HEX)" 127 "0x0x0~0x7F:ASCII Code Value (HEX)" ;
VAL_ 1030 APSM_SWVerMinor2 0 "0x0x0~0x7F:ASCII Code Value (HEX)" 127 "0x0x0~0x7F:ASCII Code Value (HEX)" ;
VAL_ 1031 APSM_AstStEsyAcsUSMSta 0 "Default Value" 1 "Off (Disable)" 2 "50mmOn (Enable)" 3 "75mmOn (Enable)" 4 "Reserved" 5 "Reserved" 6 "Reserved" 7 "Invalid" ;
VAL_ 1031 APSM_WalkInEnable 0 "Disable" 1 "Enable" 2 "Not Used" 3 "Error" ;
VAL_ 1031 APSM_LimSetSta 0 "Default" 1 "Initialized" 2 "Not Initialized" 3 "Reserved" ;
VAL_ 1031 APSM_FootRest_Opt 0 "Default" 1 "Off" 2 "On(FootRest OPT)" 3 "Ivalid" ;
VAL_ 1031 APSM_RSE_Opt 0 "Default" 1 "Off" 2 "On(RSE OPT)" 3 "Ivalid" ;
VAL_ 1064 APSU_DiagSta 0 "Stop Diag" 1 "Start Diag" 2 "Not Used" 3 "Error Indicator" ;
VAL_ 1064 APSU_AstAllLmtSta 0 "Default" 1 "Not Set" 2 "All Set" 3 "Invalid" ;
VAL_ 1064 APSU_EsyAcsGetOnSta 0 "off" 1 "on" 2 "Not Used" 3 "Error Indicator" ;
VAL_ 1064 APSU_EsyAcsGetOffSta 0 "off" 1 "on" 2 "Not Used" 3 "Error Indicator" ;
VAL_ 1064 APSU_EsyAcsStpSta 0 "off" 1 "on" 2 "Not Used" 3 "Error Indicator" ;
VAL_ 1064 APSU_RVal 0 "Default Value" 1 "Off(Disable)" 2 "Enable" 3 "Reserved" 4 "Reserved" 5 "Reserved" 6 "Reserved" 7 "Invalid" ;
VAL_ 639 ATS_RRSeatHeaterSW 0 "Default" 1 "Short On" 2 "Long On" 3 "Invalid" ;
VAL_ 639 ATS_RLSeatHeaterUpSW 0 "Default" 1 "Short On" 2 "Long On" 3 "Invalid" ;
VAL_ 639 ATS_RRSeatVentDownSW 0 "Default" 1 "Short On" 2 "Long On" 3 "Invalid" ;
VAL_ 639 ATS_RLSeatVentDownSW 0 "Default" 1 "Short On" 2 "Long On" 3 "Invalid" ;
VAL_ 639 ATS_RLMemoryRestBtn 0 "Default" 1 "Off" 2 "On" 3 "Invalid" ;
VAL_ 639 ATS_RLMemoryReturnBtn 0 "Default" 1 "Off" 2 "On" 3 "Invalid" ;
VAL_ 639 ATS_RLSeatHeaterSW 0 "Default" 1 "Short On" 2 "Long On" 3 "Invalid" ;
VAL_ 639 ATS_RRMemoryRestBtn 0 "Default" 1 "Off" 2 "On" 3 "Invalid" ;
VAL_ 639 ATS_RRMemoryReturnBtn 0 "Default" 1 "Off" 2 "On" 3 "Invalid" ;
VAL_ 639 ATS_RRMemoryAvWtcBtn 0 "Default" 1 "Off" 2 "On" 3 "Invalid" ;
VAL_ 639 ATS_RRMemoryReadingBtn 0 "Default" 1 "Off" 2 "On" 3 "Invalid" ;
VAL_ 639 ATS_RRRestModBtnSTD 0 "Default" 1 "Off" 2 "On" 3 "Invalid" ;
VAL_ 639 ATS_RRResetModBtnSTD 0 "Default" 1 "Off" 2 "On" 3 "Invalid" ;
VAL_ 639 ATS_RRAvWtcModBtnSTD 0 "Default" 1 "Off" 2 "On" 3 "Invalid" ;
VAL_ 639 ATS_RRReadingModBtnSTD 0 "Default" 1 "Off" 2 "On" 3 "Invalid" ;
VAL_ 639 ATS_RRSeatVentSW 0 "Default" 1 "Short On" 2 "Long On" 3 "Invalid" ;
VAL_ 639 ATS_RLRestModBtnSTD 0 "Default" 1 "Off" 2 "On" 3 "Invalid" ;
VAL_ 639 ATS_RLResetModBtnSTD 0 "Default" 1 "Off" 2 "On" 3 "Invalid" ;
VAL_ 639 ATS_RRModestateStopBtn 0 "Default" 1 "Off" 2 "On" 3 "Invalid" ;
VAL_ 639 ATS_RLModestateStopBtn 0 "Default" 1 "Off" 2 "On" 3 "Invalid" ;
VAL_ 639 ATS_RLResetRestBtn 0 "Default" 1 "Off" 2 "On" 3 "Invalid" ;
VAL_ 639 ATS_RLResetReturnBtn 0 "Default" 1 "Off" 2 "On" 3 "Invalid" ;
VAL_ 639 ATS_RRResetRestBtn 0 "Default" 1 "Off" 2 "On" 3 "Invalid" ;
VAL_ 639 ATS_RRResetReturnBtn 0 "Default" 1 "Off" 2 "On" 3 "Invalid" ;
VAL_ 639 ATS_RRResetAvWtcBtn 0 "Default" 1 "Off" 2 "On" 3 "Invalid" ;
VAL_ 639 ATS_RRResetReadingBtn 0 "Default" 1 "Off" 2 "On" 3 "Invalid" ;
VAL_ 639 ATS_RLSeatVentSW 0 "Default" 1 "Short On" 2 "Long On" 3 "Invalid" ;
VAL_ 639 ATS_RRSeatHeaterUpSW 0 "Default" 1 "Short On" 2 "Long On" 3 "Invalid" ;
VAL_ 623 ATS_ARSOpenCloseStatus 0 "Default" 1 "Open" 2 "Close" 3 "Invalid" ;
VAL_ 623 ATS_RLLumbarDefBtn 0 "Default" 1 "Off" 2 "On" 3 "Reserved" ;
VAL_ 623 ATS_RLLumbarLowBtn 0 "Default" 1 "Off" 2 "On" 3 "Reserved" ;
VAL_ 623 ATS_RLLumbarMidBtn 0 "Default" 1 "Off" 2 "On" 3 "Reserved" ;
VAL_ 623 ATS_RLLumbarUpBtn 0 "Default" 1 "Off" 2 "On" 3 "Reserved" ;
VAL_ 623 ATS_RLBolsterDefBtn 0 "Default" 1 "Off" 2 "On" 3 "Reserved" ;
VAL_ 623 ATS_RLBolsterInfSw 0 "Default" 1 "Off" 2 "On" 3 "Reserved" ;
VAL_ 623 ATS_RRLumbarDefBtn 0 "Default" 1 "Off" 2 "On" 3 "Reserved" ;
VAL_ 623 ATS_RRLumbarLowBtn 0 "Default" 1 "Off" 2 "On" 3 "Reserved" ;
VAL_ 623 ATS_RRLumbarMidBtn 0 "Default" 1 "Off" 2 "On" 3 "Reserved" ;
VAL_ 623 ATS_RRLumbarUpBtn 0 "Default" 1 "Off" 2 "On" 3 "Reserved" ;
VAL_ 623 ATS_RRBolsterDefBtn 0 "Default" 1 "Off" 2 "On" 3 "Reserved" ;
VAL_ 623 ATS_RRBolsterInfSw 0 "Default" 1 "Off" 2 "On" 3 "Reserved" ;
VAL_ 1050 Lamp_HiPrioHzrdReq 0 "Off" 1 "High On" 2 "High Inactive" 3 "Reserved" 4 "Reserved" 5 "Reseved" 6 "Not Used" 7 "Error Indicator" ;
VAL_ 1050 Lamp_LoPrioHzrdReq 0 "Off" 1 "Low On" 2 "Low Inactive" 3 "Reserved" 4 "Reserved" 5 "Reseved" 6 "Not Used" 7 "Error Indicator" ;
VAL_ 1050 Lamp_IntTailLmpOnReq 0 "Off" 1 "On" 2 "Not Used" 3 "Error Indicator" ;
VAL_ 1050 Lamp_ExtrnlTailLmpOnReq 0 "Off" 1 "On" 2 "Not Used" 3 "Error Indicator" ;
VAL_ 1050 Lamp_HdLmpLoOnReq 0 "Off" 1 "On" 2 "Not Used" 3 "Error Indicator" ;
VAL_ 1050 Lamp_HdLmpHiOnReq 0 "Off" 1 "On" 2 "Not Used" 3 "Error Indicator" ;
VAL_ 1050 Lamp_AvTailLmpSta 0 "Off" 1 "On" 2 "Not Used" 3 "Error Indicator" ;
VAL_ 1050 Lamp_BckUpLmpCmd 0 "Off" 1 "On" 2 "Not Used" 3 "Error Indicator" ;
VAL_ 1050 Lamp_DrlOnReq 0 "Off" 1 "On" 2 "Not Used" 3 "Error Indicator" ;
VAL_ 1052 Lamp_AutoLtSnsrNightSta 0 "Off" 1 "Night" 2 "Not Used" 3 "Error Indicator" ;
VAL_ 1052 Lamp_VendorInfo 0 "Not Used" 1 "TRW(BCS)" 2 "HELLA" 3 "Not Used" 4 "Not Used" 5 "Not Used" 6 "Not Used" 7 "Error Indicator" ;
VAL_ 1052 Lamp_AutoLtSnsrHorVal 0 "0x0x0~0x3FF:Light Sensor Value" 1023 "0x0x0~0x3FF:Light Sensor Value" ;
VAL_ 1052 IBU_HDPSpprtSWVer 0 "Not Support (Init)" 1 "SW Version" 2 "SW Version" 3 "SW Version" 4 "SW Version" 5 "SW Version" 6 "SW Version" 7 "SW Version" 8 "SW Version" 9 "SW Version" 10 "SW Version" 11 "SW Version" 12 "SW Version" 13 "SW Version" 14 "SW Version" 15 "SW Version" 16 "SW Version" 17 "SW Version" 18 "SW Version" 19 "SW Version" 20 "SW Version" 21 "SW Version" 22 "SW Version" 23 "SW Version" 24 "SW Version" 25 "SW Version" 26 "SW Version" 27 "SW Version" 28 "SW Version" 29 "SW Version" 30 "SW Version" 31 "SW Version" 32 "SW Version" 33 "SW Version" 34 "SW Version" 35 "SW Version" 36 "SW Version" 37 "SW Version" 38 "SW Version" 39 "SW Version" 40 "SW Version" 41 "SW Version" 42 "SW Version" 43 "SW Version" 44 "SW Version" 45 "SW Version" 46 "SW Version" 47 "SW Version" 48 "SW Version" 49 "SW Version" 50 "SW Version" 51 "SW Version" 52 "SW Version" 53 "SW Version" 54 "SW Version" 55 "SW Version" 56 "SW Version" 57 "SW Version" 58 "SW Version" 59 "SW Version" 60 "SW Version" 61 "SW Version" 62 "SW Version" 63 "Error Indicator" ;
VAL_ 1052 Wiper_RainAmount 0 "0x0x0~0x96:PH=0.5*HEX%" 150 "0x0x0~0x96:PH=0.5*HEX%" 151 "0x97~0xFE:Reserved" 254 "0x97~0xFE:Reserved" 255 "Invalid" ;
VAL_ 1584 AMP_NaviWarnSound 0 "Navi Warning Off" 1 "Navi Warning On" 2 "Unused" 3 "Invalid" ;
VAL_ 1584 AMP_Beep1Mode 0 "Beep1 mode off" 1 "Beep1 mode On" 2 "Unsed" 3 "Invalid" ;
VAL_ 1584 AMP_MasterBeepVolumeStep 0 "level 0" 1 "level 1" 2 "level 2" 3 "level 3" 4 "level 4" 5 "level 5" 6 "Reserved" 7 "Invalid" ;
VAL_ 1584 AMP_SignalDoctor 0 "Signal Doctor OFF" 1 "Signal Doctor ON" 2 "Unused" 3 "Invalid" ;
VAL_ 1584 AMP_RrTTSSound 0 "RrTTS Off" 1 "RrTTS ON" 2 "Unused" 3 "Invalid" ;
VAL_ 1584 AMP_ASDMode 0 "Not use" 1 "ASD OFF" 2 "Reserved" 3 "ASD ON" 4 "Reserved" 5 "Reserved" 6 "Reserved" 7 "Invalid" ;
VAL_ 1584 AMP_ANCMode 0 "Not used" 1 "ANC Off" 2 "ANC On" 3 "Invalid" ;
VAL_ 1584 AMP_VirtualVenueMode 0 "Off" 1 "Livingroom" 2 "ConcertHall" 3 "Stadium" 4 "Reserved" 5 "Reserved" 6 "Reserved" 7 "Invalid" ;
VAL_ 1584 AMP_QLIMode 0 "Off" 1 "Reference" 2 "Audience" 3 "OnStage" 4 "Reserved" 5 "Reserved" 6 "Reserved" 7 "Invalid" ;
VAL_ 1584 AMP_DriverMode 0 "Off" 1 "On" 2 "Reserved" 3 "Invalid" ;
VAL_ 1584 AMP_NaviSound 0 "Navi Off" 1 "Navi ON" 2 "Unused" 3 "Invalid" ;
VAL_ 1584 AMP_VoiceGuideTTS 0 "Off" 1 "On" 2 "Reserved" 3 "Invalid" ;
VAL_ 1584 AMP_Beep1KBDMode 0 "Beep1 mode off" 1 "Beep1 mode On" 2 "Unsed" 3 "Invalid" ;
VAL_ 1584 AMP_NaviWarnVolumeStep 0 "0x0x0~0xFD:Navi Warning Volume" 253 "0x0x0~0xFD:Navi Warning Volume" 254 "Req. amp supported Navi Set" 255 "Invalid" ;
VAL_ 1584 AMP_TTSSound 0 "TTS Off" 1 "TTS ON" 2 "Unused" 3 "Invalid" ;
VAL_ 1584 AMP_SDVCStep 0 "off" 1 "low" 2 "mid" 3 "high" 7 "Invalid" ;
VAL_ 577 C_AstBolsterInfSw_HU 0 "Default" 1 "Off" 2 "On" 3 "Invalid" ;
VAL_ 577 C_RLHrestUpSw_HU 0 "Default" 1 "Off" 2 "On" 3 "Invalid" ;
VAL_ 577 C_RLHrestDnSw_HU 0 "Default" 1 "Off" 2 "On" 3 "Invalid" ;
VAL_ 577 C_RLHrestFwdSw_HU 0 "Default" 1 "Off" 2 "On" 3 "Invalid" ;
VAL_ 577 C_AstBolsterDefSw_HU 0 "Default" 1 "Off" 2 "On" 3 "Invalid" ;
VAL_ 577 C_RLHrestBwdSw_HU 0 "Default" 1 "Off" 2 "On" 3 "Invalid" ;
VAL_ 577 C_RLLumbarUpSw_HU 0 "Default" 1 "Off" 2 "On" 3 "Invalid" ;
VAL_ 577 C_RLLumbarMidSw_HU 0 "Default" 1 "Off" 2 "On" 3 "Invalid" ;
VAL_ 577 C_RLLumbarLowSw_HU 0 "Default" 1 "Off" 2 "On" 3 "Invalid" ;
VAL_ 577 C_RLLumbarDefSw_HU 0 "Default" 1 "Off" 2 "On" 3 "Invalid" ;
VAL_ 577 C_RLBolsterInfSw_HU 0 "Default" 1 "Off" 2 "On" 3 "Invalid" ;
VAL_ 577 C_RLBolsterDefSw_HU 0 "Default" 1 "Off" 2 "On" 3 "Invalid" ;
VAL_ 577 C_AstHrestUpSw_HU 0 "Default" 1 "Off" 2 "On" 3 "Invalid" ;
VAL_ 577 C_AstHrestDnSw_HU 0 "Default" 1 "Off" 2 "On" 3 "Invalid" ;
VAL_ 577 C_AstFootrestFldSw_HU 0 "Default" 1 "Off" 2 "On" 3 "Invalid" ;
VAL_ 577 C_AstHrestFwdSw_HU 0 "Default" 1 "Off" 2 "On" 3 "Invalid" ;
VAL_ 577 C_AstHrestBwdSw_HU 0 "Default" 1 "Off" 2 "On" 3 "Invalid" ;
VAL_ 577 C_AstFootrestUnFldSw_HU 0 "Default" 1 "Off" 2 "On" 3 "Invalid" ;
VAL_ 578 C_RRLegSupFwdSw_HU 0 "Default" 1 "Off" 2 "On" 3 "Invalid" ;
VAL_ 578 C_RRHrestDnSw_HU 0 "Default" 1 "Off" 2 "On" 3 "Invalid" ;
VAL_ 578 C_RRHrestFwdSw_HU 0 "Default" 1 "Off" 2 "On" 3 "Invalid" ;
VAL_ 578 C_RRHrestBwdSw_HU 0 "Default" 1 "Off" 2 "On" 3 "Invalid" ;
VAL_ 578 C_RRLumbarUpSw_HU 0 "Default" 1 "Off" 2 "On" 3 "Invalid" ;
VAL_ 578 C_RRLumbarMidSw_HU 0 "Default" 1 "Off" 2 "On" 3 "Invalid" ;
VAL_ 578 C_RRLegSupBwdSw_HU 0 "Default" 1 "Off" 2 "On" 3 "Invalid" ;
VAL_ 578 C_RRLumbarLowSw_HU 0 "Default" 1 "Off" 2 "On" 3 "Invalid" ;
VAL_ 578 C_RRLumbarDefSw_HU 0 "Default" 1 "Off" 2 "On" 3 "Invalid" ;
VAL_ 578 C_RRBolsterInfSw_HU 0 "Default" 1 "Off" 2 "On" 3 "Invalid" ;
VAL_ 578 C_RRLegSupUpSw_HU 0 "Default" 1 "Off" 2 "On" 3 "Invalid" ;
VAL_ 578 C_RROneTchNValueSet 0 "Default" 1 "Off" 2 "Return" 3 "Relax" 4 "AV" 5 "Read" 6 "Reserved" 7 "Invalid" ;
VAL_ 578 C_RLOneTchNValueSet 0 "Default" 1 "Off" 2 "Return" 3 "Relax" 4 "Reserved" 5 "Reserved" 6 "Reserved" 7 "Invalid" ;
VAL_ 578 C_RRBolsterDefSw_HU 0 "Default" 1 "Off" 2 "On" 3 "Invalid" ;
VAL_ 578 C_AstRlxTiltUpSw_HU 0 "Default" 1 "Off" 2 "On" 3 "Invalid" ;
VAL_ 578 C_AstRlxTiltDnSw_HU 0 "Default" 1 "Off" 2 "On" 3 "Invalid" ;
VAL_ 578 C_RLRSEUpSw_HU 0 "Default" 1 "Off" 2 "On" 3 "Invalid" ;
VAL_ 578 C_RLRSEDnSw_HU 0 "Default" 1 "Off" 2 "On" 3 "Invalid" ;
VAL_ 578 C_RRRSEUpSw_HU 0 "Default" 1 "Off" 2 "On" 3 "Invalid" ;
VAL_ 578 C_RRLegSupDnSw_HU 0 "Default" 1 "Off" 2 "On" 3 "Invalid" ;
VAL_ 578 C_RRRSEDnSw_HU 0 "Default" 1 "Off" 2 "On" 3 "Invalid" ;
VAL_ 578 C_RRHrestUpSw_HU 0 "Default" 1 "Off" 2 "On" 3 "Invalid" ;
VAL_ 95 CF_AVN_MdLpBttmRedNvalueSet 0 "0x0x000~0x0FF:Red Color 0~255 (User selection)" 255 "0x0x000~0x0FF:Red Color 0~255 (User selection)" 256 "0x100~0x1FF:Red Color 0~255 (Expert Recommendation)" 511 "0x100~0x1FF:Red Color 0~255 (Expert Recommendation)" 512 "Default" 1023 "Invalid" ;
VAL_ 95 CF_AVN_MdLpBttmGreenNvalueSet 0 "0x0x000~0x0FF:0~255 (User selection)" 255 "0x0x000~0x0FF:0~255 (User selection)" 256 "0x100~0x1FF:0~255 (Expert Recommendation)" 511 "0x100~0x1FF:0~255 (Expert Recommendation)" 512 "Default" 1023 "Invalid" ;
VAL_ 95 CF_AVN_MdLpBttmBlueNvalueSet 0 "0x0x000~0x0FF:0~255 (User Selection)" 255 "0x0x000~0x0FF:0~255 (User Selection)" 256 "0x100~0x1FF:0~255 (Expert Recommendation)" 511 "0x100~0x1FF:0~255 (Expert Recommendation)" 512 "Default" 1023 "Invalid" ;
VAL_ 95 CF_AVN_MdLpSpdModNvalueSet 0 "Default" 1 "Off" 2 "On" 3 "Invalid" ;
VAL_ 95 CF_AVN_MdLpColorModNvalueSet 0 "Default" 1 "Single" 2 "Multi" 3 "Invalid" ;
VAL_ 95 CF_AVN_AIVoiceModNvalueSet 0 "Default" 1 "AI Voice Start" 2 "User Response" 3 "User No Response" 4 "Processing" 5 "AI Voice Response" 6 "AI Voice End" 7 "Invalid" ;
VAL_ 95 CF_AVN_AIVoiceMicModNvalue 0 "Default" 1 "MiCModLVL 1" 16 "MiCModLVL 16" 17 "MiCModLVL 17" 18 "MiCModLVL 18" 19 "MiCModLVL 19" 20 "MiCModLVL 20" 21 "MiCModLVL 21" 22 "MiCModLVL 22" 23 "MiCModLVL 23" 24 "MiCModLVL 24" 25 "MiCModLVL 25" 26 "MiCModLVL 26" 27 "MiCModLVL 27" 28 "MiCModLVL 28" 29 "MiCModLVL 29" 30 "MiCModLVL 30" 31 "MiCModLVL 31" 2 "MiCModLVL 2" 32 "MiCModLVL 32" 33 "MiCModLVL 33" 34 "MiCModLVL 34" 35 "MiCModLVL 35" 36 "MiCModLVL 36" 37 "MiCModLVL 37" 38 "MiCModLVL 38" 39 "MiCModLVL 39" 40 "MiCModLVL 40" 41 "MiCModLVL 41" 42 "MiCModLVL 42" 43 "MiCModLVL 43" 44 "MiCModLVL 44" 45 "MiCModLVL 45" 46 "MiCModLVL 46" 47 "MiCModLVL 47" 3 "MiCModLVL 3" 48 "MiCModLVL 48" 49 "MiCModLVL 49" 50 "MiCModLVL 50" 51 "MiCModLVL 51" 52 "MiCModLVL 52" 53 "MiCModLVL 53" 54 "MiCModLVL 54" 55 "MiCModLVL 55" 56 "MiCModLVL 56" 57 "MiCModLVL 57" 58 "MiCModLVL 58" 59 "MiCModLVL 59" 60 "MiCModLVL 60" 61 "MiCModLVL 61" 62 "MiCModLVL 62" 63 "Invalid" 4 "MiCModLVL 4" 5 "MiCModLVL 5" 6 "MiCModLVL 6" 7 "MiCModLVL 7" 8 "MiCModLVL 8" 9 "MiCModLVL 9" 10 "MiCModLVL 10" 11 "MiCModLVL 11" 12 "MiCModLVL 12" 13 "MiCModLVL 13" 14 "MiCModLVL 14" 15 "MiCModLVL 15" ;
VAL_ 95 CF_AVN_AIVoiceTTSModNvalue 0 "Default" 1 "TTSModLVL 1" 16 "TTSModLVL 16" 17 "TTSModLVL 17" 18 "TTSModLVL 18" 19 "TTSModLVL 19" 20 "TTSModLVL 20" 21 "TTSModLVL 21" 22 "TTSModLVL 22" 23 "TTSModLVL 23" 24 "TTSModLVL 24" 25 "TTSModLVL 25" 26 "TTSModLVL 26" 27 "TTSModLVL 27" 28 "TTSModLVL 28" 29 "TTSModLVL 29" 30 "TTSModLVL 30" 31 "TTSModLVL 31" 2 "TTSModLVL 2" 32 "TTSModLVL 32" 33 "TTSModLVL 33" 34 "TTSModLVL 34" 35 "TTSModLVL 35" 36 "TTSModLVL 36" 37 "TTSModLVL 37" 38 "TTSModLVL 38" 39 "TTSModLVL 39" 40 "TTSModLVL 40" 41 "TTSModLVL 41" 42 "TTSModLVL 42" 43 "TTSModLVL 43" 44 "TTSModLVL 44" 45 "TTSModLVL 45" 46 "TTSModLVL 46" 47 "TTSModLVL 47" 3 "TTSModLVL 3" 48 "TTSModLVL 48" 49 "TTSModLVL 49" 50 "TTSModLVL 50" 51 "TTSModLVL 51" 52 "TTSModLVL 52" 53 "TTSModLVL 53" 54 "TTSModLVL 54" 55 "TTSModLVL 55" 56 "TTSModLVL 56" 57 "TTSModLVL 57" 58 "TTSModLVL 58" 59 "TTSModLVL 59" 60 "TTSModLVL 60" 61 "TTSModLVL 61" 62 "TTSModLVL 62" 63 "Invalid" 4 "TTSModLVL 4" 5 "TTSModLVL 5" 6 "TTSModLVL 6" 7 "TTSModLVL 7" 8 "TTSModLVL 8" 9 "TTSModLVL 9" 10 "TTSModLVL 10" 11 "TTSModLVL 11" 12 "TTSModLVL 12" 13 "TTSModLVL 13" 14 "TTSModLVL 14" 15 "TTSModLVL 15" ;
VAL_ 95 CF_AVN_WiperAutoModeSet 0 "Default" 1 "Auto Wash Mode Off" 2 "Auto Wash Mode On" 3 "RESERVED" 4 "RESERVED" 5 "RESERVED" 6 "RESERVED" 7 "Invalid" ;
VAL_ 95 CF_AVN_AFCUAutoWashModeSet 0 "Default" 1 "AFCU Auto Wash Mode Off" 2 "AFCU Auto Wash Mode On" 3 "RESERVED" 4 "RESERVED" 5 "RESERVED" 6 "RESERVED" 7 "Invalid" ;
VAL_ 95 CF_AVN_PSDAutoWashModeSet 0 "Default" 1 "PSD Auto Wash Mode Off" 2 "PSD Auto Wash Mode On" 3 "RESERVED" 4 "RESERVED" 5 "RESERVED" 6 "RESERVED" 7 "Invalid" ;
VAL_ 95 CF_AVN_PTGAutoWashModeSet 0 "Default" 1 "PTG Auto Wash Mode Off" 2 "PTG AUto Wash Mode On" 3 "RESERVED" 4 "RESERVED" 5 "RESERVED" 6 "RESERVED" 7 "Invalid" ;
VAL_ 95 CF_AVN_CDMAutoWashModeSet 0 "Default" 1 "CDM Auto Wash Mode Off" 2 "CDM Auto Wash Mode On" 3 "RESERVED" 4 "RESERVED" 5 "RESERVED" 6 "RESERVED" 7 "Invalid" ;
VAL_ 2281833729 DMIC_DrvModSta 0 "Individual" 1 "Snow" 2 "Comfort(Normal)" 3 "Comfort+(Comfort)" 4 "ECO" 5 "Sport" 6 "Sport+" 7 "Smart" 8 "VIP" 9 "Baby" 10 "GT" 11 "Not Used" 12 "Not Used" 13 "Not Used" 14 "Not Used" 15 "Error Indicator" ;
VAL_ 2281833729 DMIC_SmtShftModSta 0 "OFF" 1 "ON" 2 "Not used" 3 "Error Indicator" ;
VAL_ 2281833729 DMIC_EngModSta 0 "0FF" 1 "ON" 2 "Comfort(Normal)" 3 "Comfort+(Comfort)" 4 "ECO" 5 "Sport" 6 "Sport+" 7 "Smart" 8 "VIP" 9 "Baby" 10 "Snow" 11 "Retro" 12 "Not used" 13 "Not used" 14 "Not used" 15 "Error Indicator" ;
VAL_ 2281833729 DMIC_IndEngModSta 0 "0FF" 1 "ON" 2 "Comfort(Normal)" 3 "Comfort+(Comfort)" 4 "ECO" 5 "Sport" 6 "Sport+" 7 "Smart" 8 "VIP" 9 "Not used" 10 "Not used" 11 "Not used" 12 "Not used" 13 "Not used" 14 "Not used" 15 "Error Indicator" ;
VAL_ 2281833729 DMIC_TmModSta 0 "0FF" 1 "ON" 2 "Comfort(Normal)" 3 "Comfort+(Comfort)" 4 "ECO" 5 "Sport" 6 "Sport+" 7 "Smart" 8 "VIP" 9 "Baby" 10 "Snow" 11 "Retro" 12 "Not used" 13 "Not used" 14 "Not used" 15 "Error Indicator" ;
VAL_ 2281833729 DMIC_IndTmModSta 0 "0FF" 1 "ON" 2 "Comfort(Normal)" 3 "Comfort+(Comfort)" 4 "ECO" 5 "Sport" 6 "Sport+" 7 "Smart" 8 "VIP" 9 "Not used" 10 "Not used" 11 "Not used" 12 "Not used" 13 "Not used" 14 "Not used" 15 "Error Indicator" ;
VAL_ 2281833729 DMIC_EscModSta 0 "0FF" 1 "ON" 2 "Comfort(Normal)" 3 "Comfort+(Comfort)" 4 "ECO" 5 "Sport" 6 "Sport+" 7 "Smart" 8 "VIP" 9 "Baby" 10 "Snow" 11 "Retro" 12 "Not used" 13 "Not used" 15 "Error Indicator" ;
VAL_ 2281833729 DMIC_IndEscModSta 0 "0FF" 1 "ON" 2 "Comfort(Normal)" 3 "Comfort+(Comfort)" 4 "ECO" 5 "Sport" 6 "Sport+" 7 "Smart" 8 "Not used" 9 "Not used" 10 "Not used" 11 "Not used" 12 "Not used" 13 "Not used" 14 "Not used" 15 "Error Indicator" ;
VAL_ 2281833729 DMIC_MdpsModSta 0 "0FF" 1 "ON" 2 "Comfort(Normal)" 3 "Comfort+(Comfort)" 4 "ECO" 5 "Sport" 6 "Sport+" 7 "Smart" 8 "VIP" 9 "Baby" 10 "Snow" 11 "Retro" 12 "Not used" 13 "Not used" 14 "Not used" 15 "Error Indicator" ;
VAL_ 2281833729 DMIC_IndMdpsModSta 0 "0FF" 1 "ON" 2 "Comfort(Normal)" 3 "Comfort+(Comfort)" 4 "ECO" 5 "Sport" 6 "Sport+" 7 "Smart" 8 "VIP" 9 "Not used" 10 "Not used" 11 "Not used" 12 "Not used" 13 "Not used" 14 "Not used" 15 "Error Indicator" ;
VAL_ 2281833731 DMIC_VcuModSta 0 "0FF" 1 "ON" 2 "Comfort(Normal)" 3 "Comfort+(Comfort)" 4 "ECO" 5 "Sport" 6 "Sport+" 7 "Smart" 8 "VIP" 9 "Baby" 10 "Snow" 11 "Retro" 12 "Not used" 13 "Not used" 14 "Not used" 15 "Error Indicator" ;
VAL_ 2281833731 DMIC_DrvModTyp 0 "Default" 1 "Drive Mode Case1" 2 "Drive Mode Case2" 3 "Drive Mode Case3" 4 "Drive Mode Case4" 5 "Drive Mode Case5" 6 "Drive Mode Case6" 7 "Drive Mode Case7" 8 "Drive Mode Case8" 9 "Drive Mode Case9" 10 "Drive Mode Case10" 11 "Drive Mode Case11" 12 "Drive Mode Case12" 13 "Drive Mode Case13" 14 "Drive Mode Case14" 15 "Invalid" ;
VAL_ 2281833731 DMIC_EngFltSta 0 "Not defective" 1 "Defective" 2 "Not used" 3 "Error Indicator" ;
VAL_ 2281833731 DMIC_TmFltSta 0 "Not defective" 1 "Defective" 2 "Not used" 3 "Error Indicator" ;
VAL_ 2281833731 DMIC_EscFltSta 0 "Not defective" 1 "Defective" 2 "Not used" 3 "Error Indicator" ;
VAL_ 2281833731 DMIC_MdpsFltSta 0 "Not defective" 1 "Defective" 2 "Not used" 3 "Error Indicator" ;
VAL_ 2281833731 DMIC_EcsFltSta 0 "Not defective" 1 "Defective" 2 "Not used" 3 "Error Indicator" ;
VAL_ 2281833731 DMIC_AwdFltSta 0 "Not defective" 1 "Defective" 2 "Not used" 3 "Error Indicator" ;
VAL_ 2281833731 DMIC_RevFltSta 0 "Not defective" 1 "Defective" 2 "Not used" 3 "Error Indicator" ;
VAL_ 2281833731 DMIC_PrflFltSta 0 "Not defective" 1 "Defective" 2 "Not used" 3 "Error Indicator" ;
VAL_ 2281833731 DMIC_ElsdFltSta 0 "Not defective" 1 "Defective" 2 "Not used" 3 "Error Indicator" ;
VAL_ 2281833731 DMIC_EsndFltSta 0 "Not defective" 1 "Defective" 2 "Not used" 3 "Error Indicator" ;
VAL_ 2281833731 DMIC_RwsFltSta 0 "Not defective" 1 "Defective" 2 "Not used" 3 "Error Indicator" ;
VAL_ 2281833731 DMIC_IndWhlDrvSta 0 "Not used" 1 "AUTO" 2 "2WD" 3 "4WD" ;
VAL_ 2281833731 DMIC_IndVcuModSta 0 "0FF" 1 "ON" 2 "Comfort(Normal)" 3 "Comfort+(Comfort)" 4 "ECO" 5 "Sport" 6 "Sport+" 7 "Smart" 8 "VIP" 9 "Not used" 10 "Not used" 11 "Not used" 12 "Not used" 13 "Not used" 14 "Not used" 15 "Error Indicator" ;
VAL_ 2281833731 DMIC_VcuFltSta 0 "Not defective" 1 "Defective" 2 "Not used" 3 "Error Indicator" ;
VAL_ 2281833731 DMIC_IndMtrPwrSta 0 "Not used" 1 "Step 1" 2 "Step 2" 3 "Step 3" 4 "Step 4" 5 "Step 5" 6 "Step 6" 7 "Step 7" ;
VAL_ 2281833731 DMIC_IndAccSenSta 0 "Not used" 1 "Step 1" 2 "Step 2" 3 "Step 3" 4 "Step 4" 5 "Step 5" 6 "Step 6" 7 "Step 7" ;
VAL_ 2281833731 DMIC_IndDecSenSta 0 "Not used" 1 "Step 1" 2 "Step 2" 3 "Step 3" 4 "Step 4" 5 "Step 5" 6 "Step 6" 7 "Step 7" ;
VAL_ 2281833731 DMIC_IndMaxVehSpdSta 0 "Not used" 1 "30" 2 "35" 3 "40" 4 "45" 5 "50" 6 "55" 7 "60" 8 "65" 9 "70" 10 "75" 11 "80" 12 "85" 13 "90" 14 "95" 15 "100" 16 "105" 17 "110" 18 "115" 19 "120" 20 "125" 21 "130" 22 "135" 23 "140" 24 "145" 25 "150" 26 "155" 27 "160" 28 "165" 29 "170" 30 "175" 31 "180" 32 "185" 33 "190" 34 "195" 35 "200" 36 "Reserved" 37 "Reserved" 38 "Reserved" 39 "Reserved" 40 "Reserved" 41 "Reserved" 42 "Reserved" 43 "Reserved" 44 "Reserved" 45 "Reserved" 46 "Reserved" 47 "Reserved" 48 "Reserved" 49 "Reserved" 50 "Reserved" 51 "Reserved" 52 "Reserved" 53 "Reserved" 54 "Reserved" 55 "Reserved" 56 "Reserved" 57 "Reserved" 58 "Reserved" 59 "Reserved" 60 "Reserved" 61 "Reserved" 62 "Reserved" 63 "Reserved" ;
VAL_ 2281833731 DMIC_DrvMod2Typ 0 "Default" 1 "Drive Mode Case1" 2 "Drive Mode Case2" 3 "Drive Mode Case3" 4 "Drive Mode Case4" 5 "Drive Mode Case5" 6 "Drive Mode Case6" 7 "Drive Mode Case7" 8 "Drive Mode Case8" 9 "Drive Mode Case9" 10 "Drive Mode Case10" 11 "Drive Mode Case11" 12 "Drive Mode Case12" 13 "Drive Mode Case13" 14 "Drive Mode Case14" 15 "Invalid" ;
VAL_ 2281833731 DMIC_DrvModFltSta 0 "All mode available" 1 "Sport mode unavailable" 2 "ECO mode and Sport mode unavailable" 3 "Comfort(Normal) mode only available (The other modes unavailable)" 4 "Not used" 5 "Not used" 6 "Not used" 7 "Not used" 8 "Not used" 9 "Not used" 10 "Not used" 11 "Not used" 12 "Not used" 13 "Not used" 14 "Not used" 15 "Error Indicator" ;
VAL_ 1041 ICU_MtGearPosRSta 0 "Off" 1 "On" 2 "RESERVED" 3 "RESERVED" ;
VAL_ 1041 Autocut_DlvryModSta 0 "Before Delivery(Welcome Off)" 1 "After Delivery(Welcome On)" 2 "Not Used" 3 "Error Indicator" ;
VAL_ 1041 DoorLock_AsstDrUnLkSta 0 "Lock" 1 "Unlock" 2 "Not Used" 3 "Error Indicator" ;
VAL_ 1041 Warn_DrvDrSwSta 0 "Close" 1 "Open" 2 "Not Used" 3 "Error Indicator" ;
VAL_ 1041 DoorLock_DrvKeyUnLkSwSta 0 "Off" 1 "Unlock" 2 "Not Used" 3 "Error Indicator" ;
VAL_ 1041 DoorLock_RrLftDrUnLkSta 0 "Lock" 1 "Unlock" 2 "Not Used" 3 "Error Indicator" ;
VAL_ 1041 DoorLock_RrRtDrUnLkSta 0 "Lock" 1 "Unlock" 2 "Not Used" 3 "Error Indicator" ;
VAL_ 1041 Warn_AsstDrSwSta 0 "Close" 1 "Open" 2 "Not Used" 3 "Error Indicator" ;
VAL_ 1041 Warn_AsstStBltSwSta 0 "Unbelted" 1 "Belted" 2 "Not Used" 3 "Error Indicator" ;
VAL_ 1041 Warn_BrkFldSwSta 0 "Off" 1 "On" 2 "Not Used" 3 "Error Indicator" ;
VAL_ 1041 DoorLock_DrvKeyLkSwSta 0 "Off" 1 "Lock" 2 "Not Used" 3 "Error Indicator" ;
VAL_ 1041 Warn_DrvStBltSwSta 0 "Unbelted" 1 "Belted" 2 "Not Used" 3 "Error Indicator" ;
VAL_ 1041 Warn_HoodSwSta 0 "Off" 1 "On" 2 "Not Used" 3 "Error Indicator" ;
VAL_ 1041 Warn_PassStOccSta 0 "Off (UnSeated)" 1 "On (Seated)" 2 "Not Used" 3 "Error Indicator" ;
VAL_ 1041 Warn_PrkngBrkSwSta 0 "Off" 1 "On" 2 "Not Used" 3 "Error Indicator" ;
VAL_ 1041 Warn_RrCtrStBltSwSta 0 "Unbelted" 1 "Belted" 2 "Not Used" 3 "Error Indicator" ;
VAL_ 1041 Warn_RrLftDrSwSta 0 "Close" 1 "Open" 2 "Not Used" 3 "Error Indicator" ;
VAL_ 1041 Warn_RrLftStBltSwSta 0 "Unbelted" 1 "Belted" 2 "Not Used" 3 "Error Indicator" ;
VAL_ 1041 Warn_RrRtDrSwSta 0 "Close" 1 "Open" 2 "Not Used" 3 "Error Indicator" ;
VAL_ 1041 Warn_RrRtStBltSwSta 0 "Unbelted" 1 "Belted" 2 "Not Used" 3 "Error Indicator" ;
VAL_ 1041 Warn_HoodSwMemorySta 0 "No event" 1 "hood_open_close" 2 "reserved" 3 "reserved" ;
VAL_ 1041 Warn_WshrFldSwSta 0 "Off" 1 "On" 2 "RESERVED" 3 "RESERVED" ;
VAL_ 1041 ICU_Haptic_OPT 0 "Default" 1 "No option(None Haptic Option)" 2 "Option" 3 "Invalid" ;
VAL_ 1043 Lamp_TrnSigLmpRtActiveSt 0 "Off (Inactive)" 1 "On (Active)" 2 "Reserved" 3 "Invalid" ;
VAL_ 1043 ExtLamp_HzrdSwSta 0 "Off" 1 "On" 2 "Not Used" 3 "Error Indicator" ;
VAL_ 1043 IntLamp_InlTailLmpSta 0 "Off" 1 "On" 2 "Not Used" 3 "Error Indicator" ;
VAL_ 1043 Lamp_LedHdLmpSta 0 "LED Headlamp is in nornal condition" 1 "Reserved" 2 "LED Fail" 3 "Reserved" ;
VAL_ 1043 TrnLmpSeqEnblCmd 0 "Off" 1 "On" 2 "Reserved" 3 "Reserved" ;
VAL_ 1043 Lamp_TrnSigLmpLftOnReq 0 "Inactive" 1 "Active Off(Flasher Off)" 2 "Active On(Flasher On)" 3 "reserved" ;
VAL_ 1043 Lamp_TrnSigLmpRtOnReq 0 "Inactive" 1 "Active Off(Flasher Off)" 2 "Active On(Flasher On)" 3 "reserved" ;
VAL_ 1043 Lamp_TrnSigLmpLftActiveSt 0 "Off (Inactive)" 1 "On (Active)" 2 "Reserved" 3 "Invalid" ;
VAL_ 1044 Trunk_TrnkInReleaseSwSta 0 "Off" 1 "On" 2 "Not Used" 3 "Error Indicator" ;
VAL_ 1044 Trunk_TrnkTlgtOutReleaseSwSta 0 "Off" 1 "On" 2 "Not Used" 3 "Error Indicator" ;
VAL_ 1044 Trunk_TrnkTlgtSwSta 0 "Close(Full Lock)" 1 "Open(Not Full Lock)" 2 "Not Used" 3 "Error Indicator" ;
VAL_ 1044 Trunk_GlvBxTrnkLkSwSta 0 "Off" 1 "On" 2 "Not Used" 3 "Error Indicator" ;
VAL_ 1044 Trunk_TlgtFullOpnSwSta 0 "Close(Not Full Open)" 1 "Open(Full Open)" 2 "Not Used" 3 "Error Indicator" ;
VAL_ 1044 Trunk_TrnkTlgtReleaseRlySta 0 "OFF" 1 "ON" 2 "Not Used" 3 "Error Indicator" ;
VAL_ 1044 USM_OneTouchTrnSigFuncSta 0 "Default" 1 "One Touch Turn Off" 2 "3 Flashing" 3 "5 Flashing" 4 "7 Flashing" 5 "Invalid" 6 "RESERVED" 7 "RESERVED" ;
VAL_ 1044 DoorLock_DrvDrUnLkSta 0 "Lock" 1 "Unlock" 2 "Not Used" 3 "Error Indicator" ;
VAL_ 1044 DoorLock_LkOutSta 0 "Off" 1 "On" 2 "Not Used" 3 "Error Indicator" ;
VAL_ 1044 C_CrashUnlockState 0 "Off" 1 "Unlock(Crash)" 2 "RESERVED" 3 "RESERVED" ;
VAL_ 1044 C_AutoLeverManualSW 0 "Not Manual" 1 "Manual" 2 "Manual +" 3 "Manual -" ;
VAL_ 1048 DriveTypeOption 0 "Left Handle Drive Type" 1 "Right Handle Drive Type" 3 "Error Indicator" ;
VAL_ 1048 Warn_RrLftSBRMATSwSta 0 "Off (UnSeated)" 1 "On (Seated)" 3 "Error Indicator" ;
VAL_ 1048 Warn_RrRhtSBRMATSwSta 0 "Off (UnSeated)" 1 "On (Seated)" 3 "Error Indicator" ;
VAL_ 1048 Lamp_FootLampOnReq 0 "Off" 1 "On" 2 "Dim Out" 3 "Error Indicator" ;
VAL_ 1048 Lamp_MoodLampOnReq 0 "0%" 1 "FadeIn" 2 "MoodBrightPercent" 3 "FadeOut" 4 "100%" 5 "RESERVED" 6 "RESERVED" 7 "RESERVED" ;
VAL_ 1048 ICU_PowerAutoCutModSta 0 "Factory Mode (default)" 1 "Dealer Mode" 2 "Customer Mode" 3 "Error Indicator" ;
VAL_ 1048 ICU_SoCBattStaMsgReq 0 "Default" 1 "Alert" 2 "Warning" 3 "Invalid" ;
VAL_ 1048 C_1stCTRSeatBeltSW 0 "Unbelted" 1 "Belted" ;
VAL_ 1048 Brake_SwSta_ICU 0 "Off" 1 "On" 2 "RESERVED" 3 "RESERVED" ;
VAL_ 1048 C_1stCTRSBRMatSw 0 "Off (UnSeated)" 1 "On (Seated)" ;
VAL_ 1048 C_3rdRCSeatBeltSW 0 "Unbelted" 1 "Belted" ;
VAL_ 1048 C_3rdRRSBRMatSw 0 "Off (UnSeated)" 1 "On (Seated)" ;
VAL_ 1048 C_3rdRLSBRMatSw 0 "Off (UnSeated)" 1 "On (Seated)" ;
VAL_ 1048 C_3rdRRSeatBeltSW 0 "Unbelted" 1 "Belted" ;
VAL_ 1048 C_3rdRLSeatBeltSW 0 "Unbelted" 1 "Belted" ;
VAL_ 1048 HSWS_SysWrngSta_ICU 0 "Normal" 1 "System Fail" 2 "Reserved" 3 "Invalid" ;
VAL_ 1040 BmsFailWarning 0 "Normal(Default)" 1 "1st warning" 2 "2nd warning" 3 "SMS warning" ;
VAL_ 1040 ICU_BS2SoC 0 "0x0x00~0x64:0% ~ 100 %" 100 "0x0x00~0x64:0% ~ 100 %" 101 "0x65~0xFE:Invalid" 254 "0x65~0xFE:Invalid" 255 "Error" ;
VAL_ 1040 ICU_BS2NCap 0 "0x0x00~0xFA:0Ah ~ 250Ah" 250 "0x0x00~0xFA:0Ah ~ 250Ah" 251 "Invalid" 252 "Invalid" 253 "Invalid" 254 "Invalid" 255 "Error" ;
VAL_ 1040 ICU_BS2OpnCirVol 0 "0x0x000~0xFA0:10.000V ~ 14.000V" 4000 "0x0x000~0xFA0:10.000V ~ 14.000V" 4001 "Invailid" 4002 "Invailid" 4003 "Invailid" 4004 "Invailid" 4005 "Invailid" 4006 "Invailid" 4007 "Invailid" 4008 "Invailid" 4009 "Invailid" 4010 "Invailid" 4011 "Invailid" 4012 "Invailid" 4013 "Invailid" 4014 "Invailid" 4015 "Invailid" 4016 "Invailid" 4017 "Invailid" 4018 "Invailid" 4019 "Invailid" 4020 "Invailid" 4021 "Invailid" 4022 "Invailid" 4023 "Invailid" 4024 "Invailid" 4025 "Invailid" 4026 "Invailid" 4027 "Invailid" 4028 "Invailid" 4029 "Invailid" 4030 "Invailid" 4031 "Invailid" 4032 "Invailid" 4033 "Invailid" 4034 "Invailid" 4035 "Invailid" 4036 "Invailid" 4037 "Invailid" 4038 "Invailid" 4039 "Invailid" 4040 "Invailid" 4041 "Invailid" 4042 "Invailid" 4043 "Invailid" 4044 "Invailid" 4045 "Invailid" 4046 "Invailid" 4047 "Invailid" 4048 "Invailid" 4049 "Invailid" 4050 "Invailid" 4051 "Invailid" 4052 "Invailid" 4053 "Invailid" 4054 "Invailid" 4055 "Invailid" 4056 "Invailid" 4057 "Invailid" 4058 "Invailid" 4059 "Invailid" 4060 "Invailid" 4061 "Invailid" 4062 "Invailid" 4063 "Invailid" 4064 "Invailid" 4065 "Invailid" 4066 "Invailid" 4067 "Invailid" 4068 "Invailid" 4069 "Invailid" 4070 "Invailid" 4071 "Invailid" 4072 "Invailid" 4073 "Invailid" 4074 "Invailid" 4075 "Invailid" 4076 "Invailid" 4077 "Invailid" 4078 "Invailid" 4079 "Invailid" 4080 "Invailid" 4081 "Invailid" 4082 "Invailid" 4083 "Invailid" 4084 "Invailid" 4085 "Invailid" 4086 "Invailid" 4087 "Invailid" 4088 "Invailid" 4089 "Invailid" 4090 "Invailid" 4091 "Invailid" 4092 "Invailid" 4093 "Invailid" 4094 "Invailid" 4095 "Error" ;
VAL_ 1040 ICU_BS2_FSOC 0 "valid" 1 "invalid" ;
VAL_ 1040 ICU_BS2_FSOH 0 "valid" 1 "invalid" ;
VAL_ 1040 ICU_BS2_FSOF 0 "valid" 1 "invalid" ;
VAL_ 1040 ICU_BS2_FQSTAT 0 "valid" 1 "invalid" ;
VAL_ 1040 ICU_BS2SoH 0 "0x0x00~0x64:0% ~ 100 %" 100 "0x0x00~0x64:0% ~ 100 %" 101 "0x65~0xFE:Invalid" 254 "0x65~0xFE:Invalid" 255 "Error" ;
VAL_ 1040 ICU_BS2SoF 0 "0x0x00~0xF0:0.00V ~ 12.00V" 240 "0x0x00~0xF0:0.00V ~ 12.00V" 241 "Invalid" 242 "Invalid" 243 "Invalid" 244 "Invalid" 245 "Invalid" 246 "Invalid" 247 "Invalid" 248 "Invalid" 249 "Invalid" 250 "Invalid" 251 "Invalid" 252 "Invalid" 253 "Invalid" 254 "Invalid" 255 "Error" ;
VAL_ 1029 Warn_ChaDrSwRrSta 0 "Default" 1 "Close" 2 "Open" 3 "Error Indicator" ;
VAL_ 1029 DoorLock_CtrlDrLkSwSta_ICU 0 "Off" 1 "On(Lock On)" 2 "Not Used" 3 "Error Indicator" ;
VAL_ 1029 DoorLock_CtrlDrUnLkSwSta_ICU 0 "Off" 1 "On(Unlock On)" 2 "Not Used" 3 "Error Indicator" ;
VAL_ 1029 DoorLock_CtrlDrLkUnLkSwSta_ICU 0 "Off" 1 "On" 2 "Not Used" 3 "Error Indicator" ;
VAL_ 1029 HEV_IGN3On_Req 0 "Default (IG3 Off)" 1 "IG3 On (by BMS)" 2 "IG3 On (by IG1 On)" 3 "IG3 On (by AVNT)" ;
VAL_ 1029 AutoLtOpt 0 "Not Applied" 1 "Applied" 2 "Reserved" 3 "Reserved" ;
VAL_ 1029 ICU_IGN3On_ReqState_New 0 "OFF" 1 "IGN1 On" 2 "IBS On" 3 "IBS and IGN1 On" 4 "CCU(HU) On" 5 "CCU(HU) and IGN1 On" 6 "CCU(HU) and IBS On" 7 "CCU(HU) and IBS and IGN1 On" 8 "VCU On" 9 "VCU and IGN1 On" 10 "VCU and IBS On" 11 "VCU and IBS and IGN1 On" 12 "VCU and CCU(HU) On" 13 "VCU and CCU(HU) and IGN1 On" 14 "VCU and CCU(HU) anc IBS On" 15 "VCU and CCU(HU) anc IBS and IGN1 On" 16 "VCMS On" 17 "VCMS and IGN1 On" 18 "VCMS and IBS On" 19 "VCMS and IBS and IGN1 On" 20 "VCMS and CCU(HU) On" 21 "VCMS and CCU(HU) and IGN1 On" 22 "VCMS and CCU(HU) and IBS On" 23 "VCMS and CCU(HU) and IBS and IGN1 On" 24 "VCMS and VCU On" 25 "VCMS and VCU and IGN1 On" 26 "VCMS and VCU and IBS On" 27 "VCMS and VCU and IBS and IGN1 On" 28 "VCMS and VCU and CCU(HU) On" 29 "VCMS and VCU and CCU(HU) and IGN1 On" 30 "VCMS and VCU and CCU(HU) and IBS On" 31 "VCMS and VCU and CCU(HU) and IBS and IGN1 On" 32 "0x20~0xFF:RESERVED" 255 "0x20~0xFF:RESERVED" ;
VAL_ 1029 ICU_BattMngAlert 0 "No Warning(Default)" 1 "Hazard On" 2 "Tail On" 3 "Hazard/Tail On" 4 "0x4~0xFE:RESERVED" 254 "0x4~0xFE:RESERVED" 255 "Invalid" ;
VAL_ 1029 HLmpLoHiOptLtSrcTyp 0 "Not Applied" 1 "2 Light MFR Bulb" 2 "4 Light Bulb" 3 "4 Light Led Ldm" 4 "Bi-Function Bulb" 5 "Bi-Function Led Ldm" 6 "Reserved" 7 "Reserved" ;
VAL_ 1029 Warn_ChaDrSwFrtSta 0 "Default" 1 "Close" 2 "Open" 3 "Error Indicator" ;
VAL_ 1067 SCM_SWVerMajor1 0 "0x0x0~0x7F:ASCII Code Value (HEX)" 127 "0x0x0~0x7F:ASCII Code Value (HEX)" ;
VAL_ 1067 SCM_SWVerMinor1 0 "0x0x0~0x7F:ASCII Code Value (HEX)" 127 "0x0x0~0x7F:ASCII Code Value (HEX)" ;
VAL_ 1067 SCM_SWVerMinor2 0 "0x0x0~0x7F:ASCII Code Value (HEX)" 127 "0x0x0~0x7F:ASCII Code Value (HEX)" ;
